VERSION ""

NS_ :

BS_:

BU_: GWM SCMB_PSM HVAC_RCCM GENERIC_GWMWakeup SOBDMD_AHCM_FOH TRM _delete SODL RTM PDM SCMH SCMG RSM SODR DDM RGTM DSM SCME TSTR

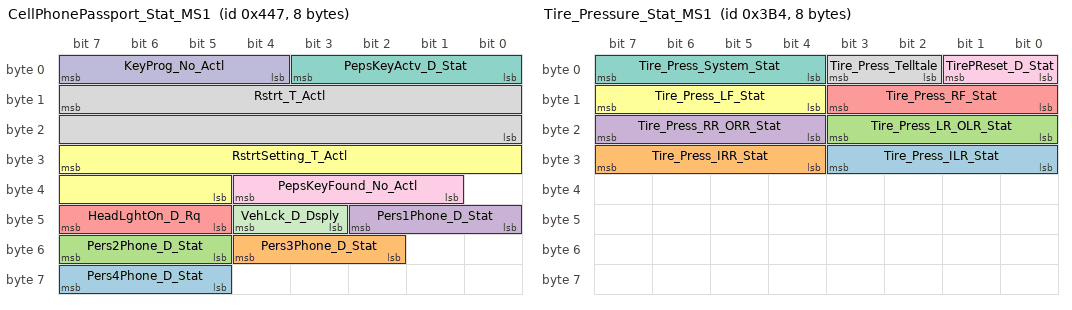
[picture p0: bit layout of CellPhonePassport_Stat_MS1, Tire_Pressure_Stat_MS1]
BO_ 1095 CellPhonePassport_Stat_MS1: 8 GWM
 SG_ Pers4Phone_D_Stat : 63|3@0+ (1,0) [0|7] "SED" Vector__XXX
 SG_ Pers3Phone_D_Stat : 52|3@0+ (1,0) [0|7] "SED" Vector__XXX
 SG_ Pers2Phone_D_Stat : 55|3@0+ (1,0) [0|7] "SED" Vector__XXX
 SG_ Pers1Phone_D_Stat : 42|3@0+ (1,0) [0|7] "SED" Vector__XXX
 SG_ HeadLghtOn_D_Rq : 47|3@0+ (1,0) [0|7] "SED" Vector__XXX
 SG_ RstrtSetting_T_Actl : 31|11@0+ (1,0) [0|2047] "second"  RSM
 SG_ PepsKeyActv_D_Stat : 3|4@0+ (1,0) [0|15] "SED" Vector__XXX
 SG_ Rstrt_T_Actl : 15|16@0+ (1,0) [0|65535] "seconds"  RSM
 SG_ PepsKeyFound_No_Actl : 36|4@0+ (1,0) [0|15] "unitless" Vector__XXX
 SG_ KeyProg_No_Actl : 7|4@0+ (1,0) [0|15] "unitless" Vector__XXX
 SG_ VehLck_D_Dsply : 44|2@0+ (1,0) [0|3] "SED" Vector__XXX

BO_ 948 Tire_Pressure_Stat_MS1: 8 GWM
 SG_ Tire_Press_ILR_Stat : 27|4@0+ (1,0) [0|15] "SED"  RTM
 SG_ Tire_Press_IRR_Stat : 31|4@0+ (1,0) [0|15] "SED"  RTM
 SG_ Tire_Press_LR_OLR_Stat : 19|4@0+ (1,0) [0|15] "SED"  RTM
 SG_ Tire_Press_RR_ORR_Stat : 23|4@0+ (1,0) [0|15] "SED"  RTM
 SG_ Tire_Press_RF_Stat : 11|4@0+ (1,0) [0|15] "SED"  RTM
 SG_ Tire_Press_LF_Stat : 15|4@0+ (1,0) [0|15] "SED"  RTM
 SG_ Tire_Press_System_Stat : 7|4@0+ (1,0) [0|15] "SED"  RTM
 SG_ Tire_Press_Telltale : 3|2@0+ (1,0) [0|3] "SED"  RTM
 SG_ TirePReset_D_Stat : 1|2@0+ (1,0) [0|3] "Discrete"  RTM

BO_ 840 FoH_Day_Req_MS1: 8 GWM
 SG_ FohT2Wednesday_T_Rq : 10|1@0+ (1,0) [0|1] "SED"  SOBDMD_AHCM_FOH
 SG_ FohT2Tuesday_T_Rq : 11|1@0+ (1,0) [0|1] "SED"  SOBDMD_AHCM_FOH
 SG_ FohT2Thursday_T_Rq : 12|1@0+ (1,0) [0|1] "SED"  SOBDMD_AHCM_FOH
 SG_ FohT2Sunday_T_Rq : 13|1@0+ (1,0) [0|1] "SED"  SOBDMD_AHCM_FOH
 SG_ FohT2Saturday_T_Rq : 14|1@0+ (1,0) [0|1] "SED"  SOBDMD_AHCM_FOH
 SG_ FohT2Monday_T_Rq : 15|1@0+ (1,0) [0|1] "SED"  SOBDMD_AHCM_FOH
 SG_ FohT2Friday_T_Rq : 0|1@0+ (1,0) [0|1] "SED"  SOBDMD_AHCM_FOH
 SG_ FohT1Wednesday_T_Rq : 1|1@0+ (1,0) [0|1] "SED"  SOBDMD_AHCM_FOH
 SG_ FohT1Tuesday_T_Rq : 2|1@0+ (1,0) [0|1] "SED"  SOBDMD_AHCM_FOH
 SG_ FohT1Thursday_T_Rq : 3|1@0+ (1,0) [0|1] "SED"  SOBDMD_AHCM_FOH
 SG_ FohT1Sunday_T_Rq : 4|1@0+ (1,0) [0|1] "SED"  SOBDMD_AHCM_FOH
 SG_ FohT1Saturday_T_Rq : 5|1@0+ (1,0) [0|1] "SED"  SOBDMD_AHCM_FOH
 SG_ FohT1Monday_T_Rq : 6|1@0+ (1,0) [0|1] "SED"  SOBDMD_AHCM_FOH
 SG_ FohT1Friday_T_Rq : 7|1@0+ (1,0) [0|1] "SED"  SOBDMD_AHCM_FOH
 SG_ FohAddHeater_D_Rq : 9|2@0+ (1,0) [0|3] "SED"  SOBDMD_AHCM_FOH
 SG_ FohStrtDateYr_No_Rq : 39|8@0+ (1,2000) [2000|2255] "year"  SOBDMD_AHCM_FOH
 SG_ FohStrtDateDay_No_Rq : 23|16@0+ (1,0) [0|65535] "julian day"  SOBDMD_AHCM_FOH

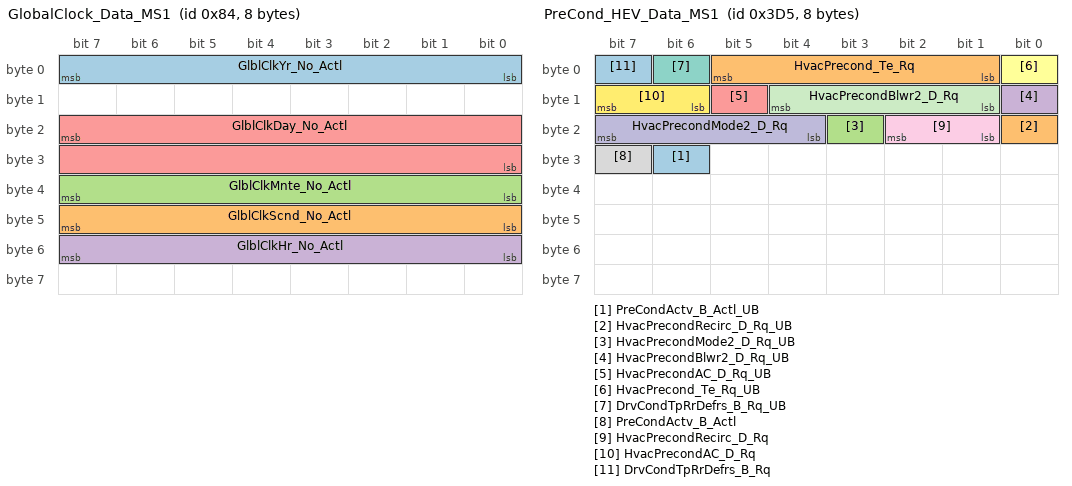
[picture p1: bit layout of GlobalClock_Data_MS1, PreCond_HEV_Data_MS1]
BO_ 132 GlobalClock_Data_MS1: 8 GWM
 SG_ GlblClkYr_No_Actl : 7|8@0+ (1,2000) [2000|2255] "year"  TRM,SOBDMD_AHCM_FOH
 SG_ GlblClkScnd_No_Actl : 47|8@0+ (1,0) [0|255] "second"  TRM,SOBDMD_AHCM_FOH
 SG_ GlblClkMnte_No_Actl : 39|8@0+ (1,0) [0|255] "minute"  TRM,SOBDMD_AHCM_FOH
 SG_ GlblClkHr_No_Actl : 55|8@0+ (1,0) [0|255] "hour"  TRM,SOBDMD_AHCM_FOH
 SG_ GlblClkDay_No_Actl : 23|16@0+ (1,0) [0|65535] "julian day"  TRM,SOBDMD_AHCM_FOH

BO_ 945 Body_Info_7_MS1: 8 GWM
 SG_ KeyOffMde_D_Actl : 7|4@0+ (1,0) [0|15] "SED"  PDM,DDM,DSM,HVAC_RCCM,RGTM

BO_ 981 PreCond_HEV_Data_MS1: 8 GWM
 SG_ PreCondActv_B_Actl_UB : 30|1@0+ (1,0) [0|1] "SED"  HVAC_RCCM
 SG_ HvacPrecondRecirc_D_Rq_UB : 16|1@0+ (1,0) [0|1] "SED"  HVAC_RCCM
 SG_ HvacPrecondMode2_D_Rq_UB : 19|1@0+ (1,0) [0|1] "SED"  HVAC_RCCM
 SG_ HvacPrecondBlwr2_D_Rq_UB : 8|1@0+ (1,0) [0|1] "SED"  HVAC_RCCM
 SG_ HvacPrecondAC_D_Rq_UB : 13|1@0+ (1,0) [0|1] "SED"  HVAC_RCCM
 SG_ HvacPrecond_Te_Rq_UB : 0|1@0+ (1,0) [0|1] "SED"  HVAC_RCCM
 SG_ DrvCondTpRrDefrs_B_Rq_UB : 6|1@0+ (1,0) [0|1] "SED"  HVAC_RCCM
 SG_ PreCondActv_B_Actl : 31|1@0+ (1,0) [0|1] "SED"  HVAC_RCCM
 SG_ HvacPrecondRecirc_D_Rq : 18|2@0+ (1,0) [0|3] "SED"  HVAC_RCCM
 SG_ HvacPrecondMode2_D_Rq : 23|4@0+ (1,0) [0|15] "SED"  HVAC_RCCM
 SG_ HvacPrecondBlwr2_D_Rq : 12|4@0+ (1,0) [0|15] "SED"  HVAC_RCCM
 SG_ HvacPrecondAC_D_Rq : 15|2@0+ (1,0) [0|3] "SED"  HVAC_RCCM
 SG_ DrvCondTpRrDefrs_B_Rq : 7|1@0+ (1,0) [0|1] "SED"  HVAC_RCCM
 SG_ HvacPrecond_Te_Rq : 5|5@0+ (0.5,14.5) [14.5|30] "deg C"  HVAC_RCCM

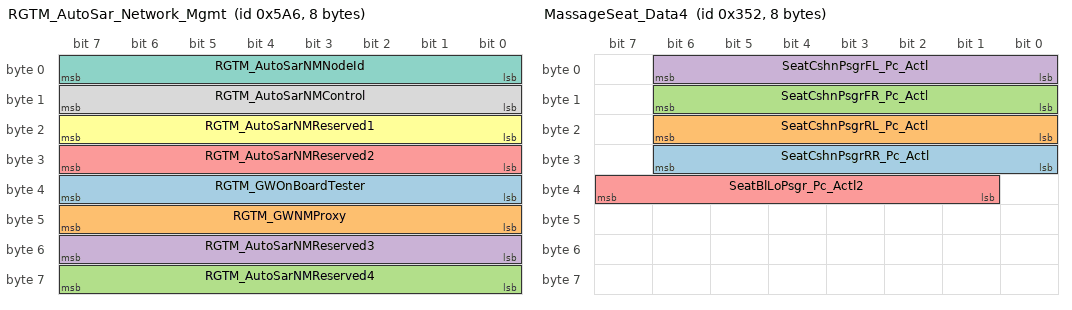
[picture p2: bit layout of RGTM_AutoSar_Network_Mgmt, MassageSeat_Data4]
BO_ 1446 RGTM_AutoSar_Network_Mgmt: 8 RGTM
 SG_ RGTM_GWOnBoardTester : 39|8@0+ (1,0) [0|255] "unitless"  DDM,GWM
 SG_ RGTM_GWNMProxy : 47|8@0+ (1,0) [0|255] "unitless"  DDM,GWM
 SG_ RGTM_AutoSarNMReserved4 : 63|8@0+ (1,0) [0|255] "unitless"  DDM,GWM
 SG_ RGTM_AutoSarNMReserved3 : 55|8@0+ (1,0) [0|255] "unitless"  DDM,GWM
 SG_ RGTM_AutoSarNMReserved2 : 31|8@0+ (1,0) [0|255] "unitless"  DDM,GWM
 SG_ RGTM_AutoSarNMReserved1 : 23|8@0+ (1,0) [0|255] "unitless"  DDM,GWM
 SG_ RGTM_AutoSarNMNodeId : 7|8@0+ (1,0) [0|255] "unitless"  DDM,GWM
 SG_ RGTM_AutoSarNMControl : 15|8@0+ (1,0) [0|255] "unitless"  DDM,GWM

BO_ 839 FuelOpHeater_Stat: 8 SOBDMD_AHCM_FOH
 SG_ FohStop_B_Stat : 49|2@0+ (1,0) [0|3] "SED"  GWM
 SG_ FohMsgTxt_D_Rq : 4|3@0+ (1,0) [0|7] "SED"  GWM
 SG_ FohKeyOff_B_Rq : 6|1@0+ (1,0) [0|1] "SED"  GWM
 SG_ FohEnbl_B_Rq : 7|1@0+ (1,0) [0|1] "SED"  GWM
 SG_ FohTAllEnable_B_Stat : 17|2@0+ (1,0) [0|3] "SED"  GWM
 SG_ FohT2Mnte_T_Stat : 55|6@0+ (1,0) [0|63] "minute"  GWM
 SG_ FohT2Hr_T_Stat : 47|5@0+ (1,0) [0|31] "hour"  GWM
 SG_ FohT2Enable_B_Stat : 63|1@0+ (1,0) [0|1] "SED"  GWM
 SG_ FohT1Mnte_T_Stat : 39|6@0+ (1,0) [0|63] "minute"  GWM
 SG_ FohT1Hr_T_Stat : 31|5@0+ (1,0) [0|31] "hour"  GWM
 SG_ FohT1Enable_B_Stat : 0|1@0+ (1,0) [0|1] "SED"  GWM
 SG_ FohStrtMnte_T_Stat : 23|6@0+ (1,0) [0|63] "minute"  GWM
 SG_ FohStrtHr_T_Stat : 15|5@0+ (1,0) [0|31] "hour"  GWM
 SG_ FohStrtEnable_B_Stat : 1|1@0+ (1,0) [0|1] "SED"  GWM
 SG_ FohContOn_B_Stat : 33|2@0+ (1,0) [0|3] "SED"  GWM
 SG_ FohStrtDay_T_Stat : 10|3@0+ (1,0) [0|7] "SED"  GWM
 SG_ FohT2Wednesday_T_Stat : 56|1@0+ (1,0) [0|1] "SED"  GWM
 SG_ FohT2Tuesday_T_Stat : 57|1@0+ (1,0) [0|1] "SED"  GWM
 SG_ FohT2Thursday_T_Stat : 58|1@0+ (1,0) [0|1] "SED"  GWM
 SG_ FohT2Sunday_T_Stat : 59|1@0+ (1,0) [0|1] "SED"  GWM
 SG_ FohT2Saturday_T_Stat : 60|1@0+ (1,0) [0|1] "SED"  GWM
 SG_ FohT2Monday_T_Stat : 61|1@0+ (1,0) [0|1] "SED"  GWM
 SG_ FohT2Friday_T_Stat : 62|1@0+ (1,0) [0|1] "SED"  GWM
 SG_ FohT1Wednesday_T_Stat : 40|1@0+ (1,0) [0|1] "SED"  GWM
 SG_ FohT1Tuesday_T_Stat : 41|1@0+ (1,0) [0|1] "SED"  GWM
 SG_ FohT1Thursday_T_Stat : 42|1@0+ (1,0) [0|1] "SED"  GWM
 SG_ FohT1Sunday_T_Stat : 24|1@0+ (1,0) [0|1] "SED"  GWM
 SG_ FohT1Saturday_T_Stat : 25|1@0+ (1,0) [0|1] "SED"  GWM
 SG_ FohT1Monday_T_Stat : 26|1@0+ (1,0) [0|1] "SED"  GWM
 SG_ FohT1Friday_T_Stat : 5|1@0+ (1,0) [0|1] "SED"  GWM

BO_ 850 MassageSeat_Data4: 8 SCMH
 SG_ SeatCshnPsgrRR_Pc_Actl : 30|7@0+ (1,0) [0|126] "Percent"  GWM
 SG_ SeatCshnPsgrRL_Pc_Actl : 22|7@0+ (1,0) [0|126] "Percent"  GWM
 SG_ SeatCshnPsgrFR_Pc_Actl : 14|7@0+ (1,0) [0|126] "Percent"  GWM
 SG_ SeatCshnPsgrFL_Pc_Actl : 6|7@0+ (1,0) [0|126] "Percent"  GWM
 SG_ SeatBlLoPsgr_Pc_Actl2 : 39|7@0+ (1,0) [0|126] "Percent"  GWM

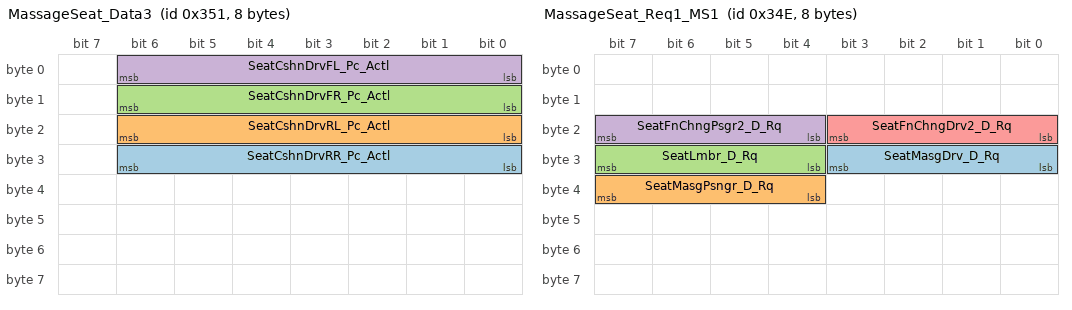
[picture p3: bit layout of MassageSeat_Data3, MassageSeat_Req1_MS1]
BO_ 849 MassageSeat_Data3: 8 SCMG
 SG_ SeatCshnDrvRR_Pc_Actl : 30|7@0+ (1,0) [0|126] "Percent"  GWM
 SG_ SeatCshnDrvRL_Pc_Actl : 22|7@0+ (1,0) [0|126] "Percent"  GWM
 SG_ SeatCshnDrvFR_Pc_Actl : 14|7@0+ (1,0) [0|126] "Percent"  GWM
 SG_ SeatCshnDrvFL_Pc_Actl : 6|7@0+ (1,0) [0|126] "Percent"  GWM

BO_ 846 MassageSeat_Req1_MS1: 8 GWM
 SG_ SeatMasgDrv_D_Rq : 27|4@0+ (1,0) [0|15] "SED" Vector__XXX
 SG_ SeatMasgPsngr_D_Rq : 39|4@0+ (1,0) [0|15] "SED" Vector__XXX
 SG_ SeatLmbr_D_Rq : 31|4@0+ (1,0) [0|15] "SED"  DSM,SCMB_PSM
 SG_ SeatFnChngPsgr2_D_Rq : 23|4@0+ (1,0) [0|15] "SED"  SCMG,SCMH
 SG_ SeatFnChngDrv2_D_Rq : 19|4@0+ (1,0) [0|15] "SED"  SCMG,SCMH

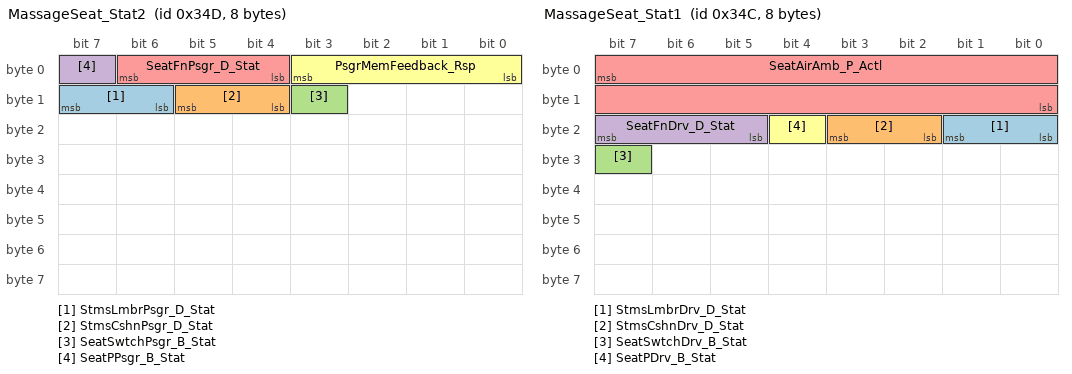
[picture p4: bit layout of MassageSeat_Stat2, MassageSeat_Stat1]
BO_ 845 MassageSeat_Stat2: 8 SCMH
 SG_ StmsLmbrPsgr_D_Stat : 15|2@0+ (1,0) [0|3] "SED"  GWM
 SG_ StmsCshnPsgr_D_Stat : 13|2@0+ (1,0) [0|3] "SED"  GWM
 SG_ SeatSwtchPsgr_B_Stat : 11|1@0+ (1,0) [0|1] "SED"  GWM
 SG_ SeatPPsgr_B_Stat : 7|1@0+ (1,0) [0|1] "SED"  GWM
 SG_ SeatFnPsgr_D_Stat : 6|3@0+ (1,0) [0|7] "SED"  GWM
 SG_ PsgrMemFeedback_Rsp : 3|4@0+ (1,0) [0|15] "SED"  GWM

BO_ 844 MassageSeat_Stat1: 8 SCMG
 SG_ StmsLmbrDrv_D_Stat : 17|2@0+ (1,0) [0|3] "SED"  GWM
 SG_ StmsCshnDrv_D_Stat : 19|2@0+ (1,0) [0|3] "SED"  GWM
 SG_ SeatSwtchDrv_B_Stat : 31|1@0+ (1,0) [0|1] "SED"  GWM
 SG_ SeatFnDrv_D_Stat : 23|3@0+ (1,0) [0|7] "SED"  GWM
 SG_ SeatAirAmb_P_Actl : 7|16@0+ (0.01,0) [0|655.35] "KiloPascal"  GWM,SCMH
 SG_ SeatPDrv_B_Stat : 20|1@0+ (1,0) [0|1] "SED"  GWM

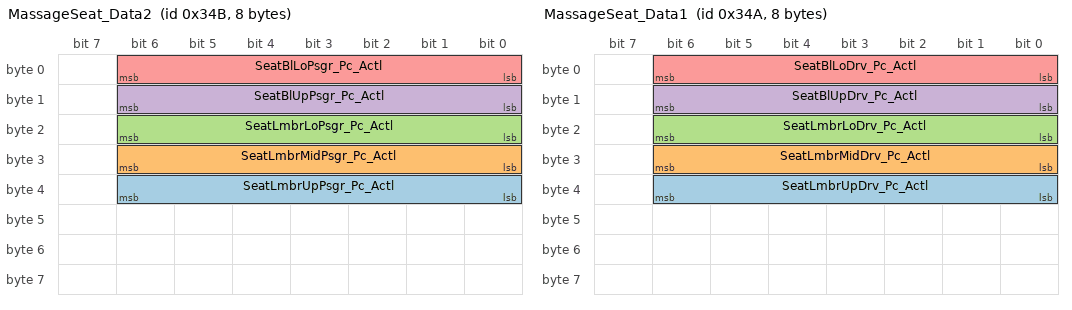
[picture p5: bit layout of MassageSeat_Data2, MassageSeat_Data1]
BO_ 843 MassageSeat_Data2: 8 SCMH
 SG_ SeatLmbrUpPsgr_Pc_Actl : 38|7@0+ (1,0) [0|127] "Percent"  GWM
 SG_ SeatLmbrMidPsgr_Pc_Actl : 30|7@0+ (1,0) [0|127] "Percent"  GWM
 SG_ SeatLmbrLoPsgr_Pc_Actl : 22|7@0+ (1,0) [0|127] "Percent"  GWM
 SG_ SeatBlUpPsgr_Pc_Actl : 14|7@0+ (1,0) [0|126] "Percent"  GWM
 SG_ SeatBlLoPsgr_Pc_Actl : 6|7@0+ (1,0) [0|126] "Percent"  GWM

BO_ 842 MassageSeat_Data1: 8 SCMG
 SG_ SeatLmbrUpDrv_Pc_Actl : 38|7@0+ (1,0) [0|127] "Percent"  GWM
 SG_ SeatLmbrMidDrv_Pc_Actl : 30|7@0+ (1,0) [0|127] "Percent"  GWM
 SG_ SeatLmbrLoDrv_Pc_Actl : 22|7@0+ (1,0) [0|127] "Percent"  GWM
 SG_ SeatBlUpDrv_Pc_Actl : 14|7@0+ (1,0) [0|126] "Percent"  GWM
 SG_ SeatBlLoDrv_Pc_Actl : 6|7@0+ (1,0) [0|126] "Percent"  GWM

BO_ 1994 TesterPhysicalResRSM: 8 RSM
 SG_ TesterPhysicalResRSM : 7|64@0+ (1,0) [0|1.84467E+019] "unitless"  TSTR

BO_ 1986 TesterPhysicalReqRSM: 8 TSTR
 SG_ TesterPhysicalReqRSM : 7|64@0+ (1,0) [0|1.84467E+019] "unitless"  RSM

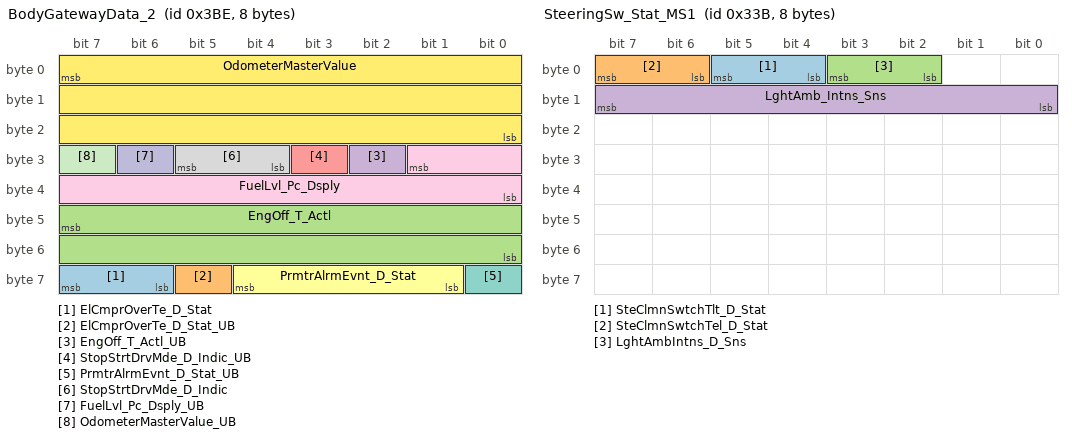
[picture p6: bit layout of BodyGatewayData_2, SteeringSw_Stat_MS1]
BO_ 958 BodyGatewayData_2: 8 GWM
 SG_ ElCmprOverTe_D_Stat : 63|2@0+ (1,0) [0|3] "SED"  HVAC_RCCM
 SG_ ElCmprOverTe_D_Stat_UB : 61|1@0+ (1,0) [0|1] "SED"  HVAC_RCCM
 SG_ EngOff_T_Actl : 47|16@0+ (1,0) [0|65534] "second^0.5"  HVAC_RCCM
 SG_ EngOff_T_Actl_UB : 26|1@0+ (1,0) [0|1] "SED"  HVAC_RCCM
 SG_ StopStrtDrvMde_D_Indic_UB : 27|1@0+ (1,0) [0|1] "SED"  HVAC_RCCM
 SG_ PrmtrAlrmEvnt_D_Stat : 60|4@0+ (1,0) [0|15] "SED"  RSM
 SG_ PrmtrAlrmEvnt_D_Stat_UB : 56|1@0+ (1,0) [0|1] "SED"  RSM
 SG_ StopStrtDrvMde_D_Indic : 29|2@0+ (1,0) [0|3] "SED"  HVAC_RCCM
 SG_ FuelLvl_Pc_Dsply : 25|10@0+ (0.108696,-5.217408) [-5.217408|105.9786] "Percent"  SOBDMD_AHCM_FOH
 SG_ FuelLvl_Pc_Dsply_UB : 30|1@0+ (1,0) [0|1] "SED"  SOBDMD_AHCM_FOH
 SG_ OdometerMasterValue_UB : 31|1@0+ (1,0) [0|1] "SED"  HVAC_RCCM,SOBDMD_AHCM_FOH,RGTM
 SG_ OdometerMasterValue : 7|24@0+ (1,0) [0|16777214] "km"  HVAC_RCCM,SOBDMD_AHCM_FOH,RGTM

BO_ 827 SteeringSw_Stat_MS1: 8 GWM
 SG_ SteClmnSwtchTlt_D_Stat : 5|2@0+ (1,0) [0|3] "SED"  DSM
 SG_ SteClmnSwtchTel_D_Stat : 7|2@0+ (1,0) [0|3] "SED"  DSM
 SG_ LghtAmbIntns_D_Sns : 3|2@0+ (1,0) [0|3] "SED" Vector__XXX
 SG_ LghtAmb_Intns_Sns : 15|8@0+ (1,0) [0|255] "unitless" Vector__XXX

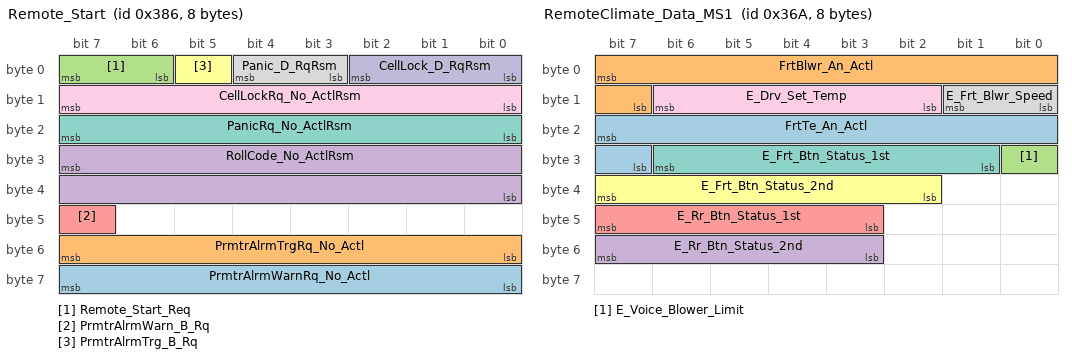
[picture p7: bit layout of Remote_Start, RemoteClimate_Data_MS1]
BO_ 902 Remote_Start: 8 RSM
 SG_ PrmtrAlrmWarnRq_No_Actl : 63|8@0+ (1,0) [0|255] "unitless"  GWM
 SG_ PrmtrAlrmTrgRq_No_Actl : 55|8@0+ (1,0) [0|255] "unitless"  GWM
 SG_ Remote_Start_Req : 7|2@0+ (1,0) [0|3] "SED"  GWM
 SG_ RollCode_No_ActlRsm : 31|16@0+ (1,0) [0|65535] "unitless"  GWM
 SG_ PrmtrAlrmWarn_B_Rq : 47|1@0+ (1,0) [0|1] "SED"  GWM
 SG_ PrmtrAlrmTrg_B_Rq : 5|1@0+ (1,0) [0|1] "SED"  GWM
 SG_ PanicRq_No_ActlRsm : 23|8@0+ (1,0) [0|255] "unitless"  GWM
 SG_ Panic_D_RqRsm : 4|2@0+ (1,0) [0|3] "SED"  GWM
 SG_ CellLockRq_No_ActlRsm : 15|8@0+ (1,0) [0|255] "unitless"  GWM
 SG_ CellLock_D_RqRsm : 2|3@0+ (1,0) [0|7] "SED"  GWM

BO_ 765 GatewayData_MS1: 8 GWM
 SG_ ValetMode_D_Stat_UB : 35|1@0+ (1,0) [0|1] "SED"  DSM
 SG_ ValetMode_D_Stat : 25|2@0+ (1,0) [0|3] "SED"  DSM
 SG_ CcStat_D_Actl_UB : 48|1@0+ (1,0) [0|1] "SED" Vector__XXX
 SG_ CcStat_D_Actl : 51|3@0+ (1,0) [0|7] "SED" Vector__XXX
 SG_ PrplTqMnSat_B_Actl_UB : 52|1@0+ (1,0) [0|1] "SED" Vector__XXX
 SG_ PrplTqMnSat_B_Actl : 53|1@0+ (1,0) [0|1] "SED" Vector__XXX
 SG_ ClimtBlwrLim_B_Rq_UB : 60|1@0+ (1,0) [0|1] "SED"  HVAC_RCCM
 SG_ ClimtBlwrLim_B_Rq : 61|1@0+ (1,0) [0|1] "SED"  HVAC_RCCM
 SG_ TrlrBrkActCnnct_B_Actl_UB : 62|1@0+ (1,0) [0|1] "SED" Vector__XXX
 SG_ TrlrBrkActCnnct_B_Actl : 63|1@0+ (1,0) [0|1] "SED" Vector__XXX
 SG_ EmPrflButtnAssoc_D_Rq : 17|2@0+ (1,0) [0|3] "SED"  DSM
 SG_ EmPrflButtnAssoc_D_Rq_UB : 56|1@0+ (1,0) [0|1] "SED"  DSM
 SG_ CamraFrntStat_D_Stat_UB : 32|1@0+ (1,0) [0|1] "SED"  HVAC_RCCM
 SG_ CamraFrntStat_D_Stat : 34|2@0+ (1,0) [0|3] "SED"  HVAC_RCCM
 SG_ AutoHoldSwMde_B_Ind_UB : 46|1@0+ (1,0) [0|1] "SED"  HVAC_RCCM
 SG_ AutoHoldSwMde_B_Ind : 47|1@0+ (1,0) [0|1] "SED"  HVAC_RCCM
 SG_ SteWhlHeat_D_Stat : 39|4@0+ (1,0) [0|15] "SED"  HVAC_RCCM
 SG_ Running_Board_Cmd_UB : 27|1@0+ (1,0) [0|1] "SED" Vector__XXX
 SG_ Running_Board_Cmd : 29|2@0+ (1,0) [0|3] "SED" Vector__XXX
 SG_ Bezel_Beeps_Rq_UB : 18|1@0+ (1,0) [0|1] "SED" Vector__XXX
 SG_ Bezel_Beeps_Rq : 20|2@0+ (1,0) [0|3] "unitless" Vector__XXX
 SG_ Diagnostic_Operation_Rq_UB : 21|1@0+ (1,0) [0|1] "SED"  HVAC_RCCM
 SG_ Bezel_Diag_State_Rq_UB : 23|1@0+ (1,0) [0|1] "SED" Vector__XXX
 SG_ Bezel_Diag_Module_Rq_UB : 22|1@0+ (1,0) [0|1] "SED" Vector__XXX
 SG_ Diagnostic_Operation_Rq : 11|4@0+ (1,0) [0|15] "unitless"  HVAC_RCCM
 SG_ Bezel_Diag_State_Rq : 1|2@0+ (1,0) [0|3] "unitless" Vector__XXX
 SG_ Bezel_Diag_Module_Rq : 15|4@0+ (1,0) [0|15] "unitless" Vector__XXX
 SG_ HMI_HMIMode_St_UB : 2|1@0+ (1,0) [0|1] "SED"  HVAC_RCCM,RGTM
 SG_ HMI_HMIMode_St : 5|3@0+ (1,0) [0|7] "SED"  HVAC_RCCM,RGTM
 SG_ Mc_VehUnitTempUsrSel_St_UB : 6|1@0+ (1,0) [0|1] "SED"  HVAC_RCCM
 SG_ Mc_VehUnitTempUsrSel_St : 7|1@0+ (1,0) [0|1] "SED"  HVAC_RCCM
 SG_ PsngrFrntDetct_D_Actl_UB : 40|1@0+ (1,0) [0|1] "SED"  HVAC_RCCM
 SG_ PsngrFrntDetct_D_Actl : 55|2@0+ (1,0) [0|3] "SED"  HVAC_RCCM
 SG_ SteWhlHeat_D_Stat_UB : 26|1@0+ (1,0) [0|1] "SED"  HVAC_RCCM
 SG_ PrkAidLamp_D_Rq_UB : 41|1@0+ (1,0) [0|1] "SED" Vector__XXX
 SG_ ParkDetect_Stat_UB : 30|1@0+ (1,0) [0|1] "SED"  RSM
 SG_ ParkDetect_Stat : 31|1@0+ (1,0) [0|1] "SED"  RSM
 SG_ Voice_Blower_Limit_UB : 44|1@0+ (1,0) [0|1] "SED"  HVAC_RCCM
 SG_ Voice_Blower_Limit : 45|1@0+ (1,0) [0|1] "SED"  HVAC_RCCM
 SG_ PwStep_D_DrvInhbt_UB : 57|1@0+ (1,0) [0|1] "SED" Vector__XXX
 SG_ PwStep_D_DrvInhbt : 59|2@0+ (1,0) [0|3] "SED" Vector__XXX

BO_ 874 RemoteClimate_Data_MS1: 8 GWM
 SG_ FrtTe_An_Actl : 23|9@0+ (1,0) [0|510] "degrees"  HVAC_RCCM
 SG_ FrtBlwr_An_Actl : 7|9@0+ (1,0) [0|510] "degrees"  HVAC_RCCM
 SG_ E_Voice_Blower_Limit : 24|1@0+ (1,0) [0|1] "SED"  HVAC_RCCM
 SG_ E_Rr_Btn_Status_2nd : 55|5@0+ (1,0) [0|31] "SED"  HVAC_RCCM
 SG_ E_Rr_Btn_Status_1st : 47|5@0+ (1,0) [0|31] "SED"  HVAC_RCCM
 SG_ E_Frt_Btn_Status_2nd : 39|6@0+ (1,0) [0|63] "SED"  HVAC_RCCM
 SG_ E_Frt_Btn_Status_1st : 30|6@0+ (1,0) [0|63] "SED"  HVAC_RCCM
 SG_ E_Frt_Blwr_Speed : 9|2@0+ (1,0) [0|3] "SED"  HVAC_RCCM
 SG_ E_Drv_Set_Temp : 14|5@0+ (1,0) [0|31] "SED"  HVAC_RCCM

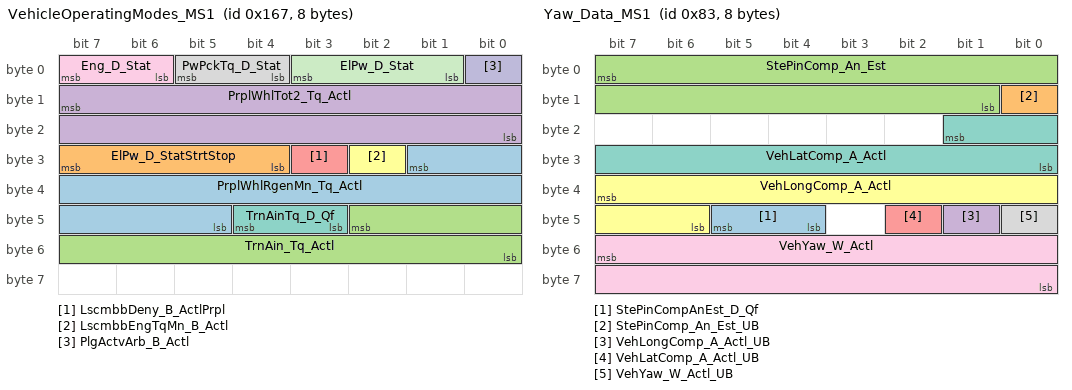
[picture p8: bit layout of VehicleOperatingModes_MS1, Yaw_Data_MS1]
BO_ 359 VehicleOperatingModes_MS1: 8 GWM
 SG_ PrplWhlRgenMn_Tq_Actl : 25|13@0+ (4,-16380) [-16380|16380] "Nm" Vector__XXX
 SG_ ElPw_D_StatStrtStop : 31|4@0+ (1,0) [0|15] "SED" Vector__XXX
 SG_ TrnAin_Tq_Actl : 42|11@0+ (1,-500) [-500|1547] "Nm" Vector__XXX
 SG_ PrplWhlTot2_Tq_Actl : 15|16@0+ (4,-131072) [-131072|131060] "Nm" Vector__XXX
 SG_ LscmbbDeny_B_ActlPrpl : 27|1@0+ (1,0) [0|1] "SED" Vector__XXX
 SG_ LscmbbEngTqMn_B_Actl : 26|1@0+ (1,0) [0|1] "SED" Vector__XXX
 SG_ TrnAinTq_D_Qf : 44|2@0+ (1,0) [0|3] "SED" Vector__XXX
 SG_ PwPckTq_D_Stat : 5|2@0+ (1,0) [0|3] "SED"  SCMB_PSM,SCME,HVAC_RCCM,RSM,TRM,SCMH,SCMG,RTM,RGTM,PDM,DSM,DDM,SOBDMD_AHCM_FOH
 SG_ Eng_D_Stat : 7|2@0+ (1,0) [0|3] "SED"  HVAC_RCCM,SOBDMD_AHCM_FOH
 SG_ PlgActvArb_B_Actl : 0|1@0+ (1,0) [0|1] "SED" Vector__XXX
 SG_ ElPw_D_Stat : 3|3@0+ (1,0) [0|7] "SED"  SCMB_PSM,SCME,HVAC_RCCM,SCMG,SCMH,TRM,SOBDMD_AHCM_FOH,DDM,DSM,PDM,RGTM,RTM

BO_ 131 Yaw_Data_MS1: 8 GWM
 SG_ StePinCompAnEst_D_Qf : 45|2@0+ (1,0) [0|3] "SED"  SODL,SODR
 SG_ StePinComp_An_Est_UB : 8|1@0+ (1,0) [0|1] "SED"  SODL,SODR
 SG_ StePinComp_An_Est : 7|15@0+ (0.1,-1600) [-1600|1676.7] "degrees"  SODL,SODR
 SG_ VehLongComp_A_Actl_UB : 41|1@0+ (1,0) [0|1] "SED"  RGTM
 SG_ VehLatComp_A_Actl_UB : 42|1@0+ (1,0) [0|1] "SED"  RGTM
 SG_ VehLongComp_A_Actl : 39|10@0+ (0.035,-17.9) [-17.9|17.835] "m/s^2"  RGTM
 SG_ VehLatComp_A_Actl : 17|10@0+ (0.035,-17.9) [-17.9|17.835] "m/s^2"  RGTM
 SG_ VehYaw_W_Actl_UB : 40|1@0+ (1,0) [0|1] "SED"  SODL,SODR
 SG_ VehYaw_W_Actl : 55|16@0+ (0.0002,-6.5) [-6.5|6.6066] "rad/s"  SODL,SODR

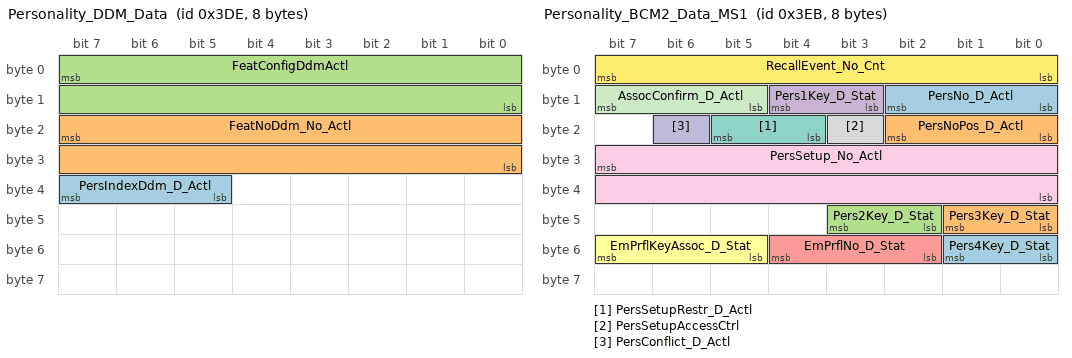
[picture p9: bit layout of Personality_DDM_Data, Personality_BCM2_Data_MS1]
BO_ 990 Personality_DDM_Data: 8 DDM
 SG_ PersIndexDdm_D_Actl : 39|3@0+ (1,0) [0|7] "SED"  GWM
 SG_ FeatNoDdm_No_Actl : 23|16@0+ (1,0) [0|65535] "Number"  GWM
 SG_ FeatConfigDdmActl : 7|16@0+ (1,0) [0|65535] "Undefined"  GWM

BO_ 1003 Personality_BCM2_Data_MS1: 8 GWM
 SG_ Pers4Key_D_Stat : 49|2@0+ (1,0) [0|3] "SED" Vector__XXX
 SG_ Pers3Key_D_Stat : 41|2@0+ (1,0) [0|3] "SED" Vector__XXX
 SG_ Pers2Key_D_Stat : 43|2@0+ (1,0) [0|3] "SED" Vector__XXX
 SG_ Pers1Key_D_Stat : 12|2@0+ (1,0) [0|3] "SED" Vector__XXX
 SG_ EmPrflNo_D_Stat : 52|3@0+ (1,0) [0|7] "SED" Vector__XXX
 SG_ EmPrflKeyAssoc_D_Stat : 55|3@0+ (1,0) [0|7] "SED" Vector__XXX
 SG_ PersSetupRestr_D_Actl : 21|2@0+ (1,0) [0|3] "SED"  HVAC_RCCM,PDM,DDM,DSM
 SG_ PersSetupAccessCtrl : 19|1@0+ (1,0) [0|1] "SED"  HVAC_RCCM,DDM,DSM
 SG_ PersSetup_No_Actl : 31|16@0+ (1,0) [0|65535] "Number"  HVAC_RCCM,PDM,DDM,DSM
 SG_ PersConflict_D_Actl : 22|1@0+ (1,0) [0|1] "SED" Vector__XXX
 SG_ AssocConfirm_D_Actl : 15|3@0+ (1,0) [0|7] "SED" Vector__XXX
 SG_ RecallEvent_No_Cnt : 7|8@0+ (1,0) [0|255] "Counts"  HVAC_RCCM,SCMG,SCMH,DDM,DSM
 SG_ PersNo_D_Actl : 10|3@0+ (1,0) [0|7] "SED"  HVAC_RCCM,DDM,DSM,SCMG,SCMH
 SG_ PersNoPos_D_Actl : 18|3@0+ (1,0) [0|7] "SED"  SCMG,SCMH,DSM

BO_ 1945 TesterPhysicalResTRM: 8 TRM
 SG_ TesterPhysicalResTRM : 7|64@0+ (1,0) [0|1.84467E+019] "unitless"  TSTR

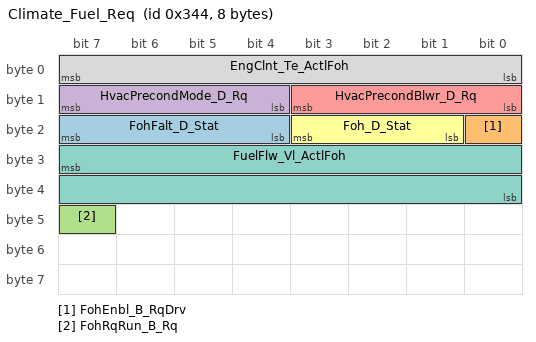
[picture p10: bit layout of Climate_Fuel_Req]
BO_ 836 Climate_Fuel_Req: 8 SOBDMD_AHCM_FOH
 SG_ FohFalt_D_Stat : 23|4@0+ (1,0) [0|15] "SED"  GWM
 SG_ FohEnbl_B_RqDrv : 16|1@0+ (1,0) [0|1] "SED"  GWM
 SG_ FohRqRun_B_Rq : 47|1@0+ (1,0) [0|1] "SED"  GWM
 SG_ HvacPrecondMode_D_Rq : 15|4@0+ (1,0) [0|15] "SED"  HVAC_RCCM,GWM
 SG_ HvacPrecondBlwr_D_Rq : 11|4@0+ (1,0) [0|15] "SED"  HVAC_RCCM,GWM
 SG_ Foh_D_Stat : 19|3@0+ (1,0) [0|7] "SED"  HVAC_RCCM,GWM
 SG_ FuelFlw_Vl_ActlFoh : 31|16@0+ (25,0) [0|1638375] "microlitre"  GWM
 SG_ EngClnt_Te_ActlFoh : 7|8@0+ (1,-50) [-50|204] "degC"  HVAC_RCCM,GWM

CM_ BO_ 948 "$3B4 used by CGEA SPDJB";
CM_ SG_ 840 FohT2Wednesday_T_Rq "Signal not transmitted on vehicles that do not have the Fuel operated heater feature.";
CM_ SG_ 840 FohT2Tuesday_T_Rq "Signal not transmitted on vehicles that do not have the Fuel operated heater feature.";
CM_ SG_ 840 FohT2Thursday_T_Rq "Signal not transmitted on vehicles that do not have the Fuel operated heater feature.";
CM_ SG_ 840 FohT2Sunday_T_Rq "Signal not transmitted on vehicles that do not have the Fuel operated heater feature.";
CM_ SG_ 840 FohT2Saturday_T_Rq "Signal not transmitted on vehicles that do not have the Fuel operated heater feature.";
CM_ SG_ 840 FohT2Monday_T_Rq "Signal not transmitted on vehicles that do not have the Fuel operated heater feature.";
CM_ SG_ 840 FohT2Friday_T_Rq "Signal not transmitted on vehicles that do not have the Fuel operated heater feature.";
CM_ SG_ 840 FohT1Wednesday_T_Rq "Signal not transmitted on vehicles that do not have the Fuel operated heater feature.";
CM_ SG_ 840 FohT1Tuesday_T_Rq "Signal not transmitted on vehicles that do not have the Fuel operated heater feature.";
CM_ SG_ 840 FohT1Thursday_T_Rq "Signal not transmitted on vehicles that do not have the Fuel operated heater feature.";
CM_ SG_ 840 FohT1Sunday_T_Rq "Signal not transmitted on vehicles that do not have the Fuel operated heater feature.";
CM_ SG_ 840 FohT1Saturday_T_Rq "Signal not transmitted on vehicles that do not have the Fuel operated heater feature.";
CM_ SG_ 840 FohT1Monday_T_Rq "Signal not transmitted on vehicles that do not have the Fuel operated heater feature.";
CM_ SG_ 840 FohT1Friday_T_Rq "Signal not transmitted on vehicles that do not have the Fuel operated heater feature.";
CM_ SG_ 981 HvacPrecondMode2_D_Rq "Signal not transmitted on vehicles that do not have the Fuel operated heater feature.";
CM_ SG_ 981 HvacPrecondBlwr2_D_Rq "Signal not transmitted on vehicles that do not have the Fuel operated heater feature.";
CM_ SG_ 839 FohStop_B_Stat "Signal not transmitted on vehicles that do not have the Fuel operated heater feature.";
CM_ SG_ 839 FohMsgTxt_D_Rq "Signal not transmitted on vehicles that do not have the Fuel operated heater feature.";
CM_ SG_ 839 FohKeyOff_B_Rq "Signal not transmitted on vehicles that do not have the Fuel operated heater feature.";
CM_ SG_ 839 FohEnbl_B_Rq "Signal not transmitted on vehicles that do not have the Fuel operated heater feature.";
CM_ SG_ 839 FohTAllEnable_B_Stat "Signal not transmitted on vehicles that do not have the Fuel operated heater feature.";
CM_ SG_ 839 FohT2Mnte_T_Stat "Signal not transmitted on vehicles that do not have the Fuel operated heater feature.";
CM_ SG_ 839 FohT2Hr_T_Stat "Signal not transmitted on vehicles that do not have the Fuel operated heater feature.";
CM_ SG_ 839 FohT2Enable_B_Stat "Signal not transmitted on vehicles that do not have the Fuel operated heater feature.";
CM_ SG_ 839 FohT1Mnte_T_Stat "Signal not transmitted on vehicles that do not have the Fuel operated heater feature.";
CM_ SG_ 839 FohT1Hr_T_Stat "Signal not transmitted on vehicles that do not have the Fuel operated heater feature.";
CM_ SG_ 839 FohT1Enable_B_Stat "Signal not transmitted on vehicles that do not have the Fuel operated heater feature.";
CM_ SG_ 839 FohStrtMnte_T_Stat "Signal not transmitted on vehicles that do not have the Fuel operated heater feature.";
CM_ SG_ 839 FohStrtHr_T_Stat "Signal not transmitted on vehicles that do not have the Fuel operated heater feature.";
CM_ SG_ 839 FohStrtEnable_B_Stat "Signal not transmitted on vehicles that do not have the Fuel operated heater feature.";
CM_ SG_ 839 FohContOn_B_Stat "Signal not transmitted on vehicles that do not have the Fuel operated heater feature.";
CM_ SG_ 839 FohStrtDay_T_Stat "Signal not transmitted on vehicles that do not have the Fuel operated heater feature.";
CM_ SG_ 839 FohT2Wednesday_T_Stat "Signal not transmitted on vehicles that do not have the Fuel operated heater feature.";
CM_ SG_ 839 FohT2Tuesday_T_Stat "Signal not transmitted on vehicles that do not have the Fuel operated heater feature.";
CM_ SG_ 839 FohT2Thursday_T_Stat "Signal not transmitted on vehicles that do not have the Fuel operated heater feature.";
CM_ SG_ 839 FohT2Sunday_T_Stat "Signal not transmitted on vehicles that do not have the Fuel operated heater feature.";
CM_ SG_ 839 FohT2Saturday_T_Stat "Signal not transmitted on vehicles that do not have the Fuel operated heater feature.";
CM_ SG_ 839 FohT2Monday_T_Stat "Signal not transmitted on vehicles that do not have the Fuel operated heater feature.";
CM_ SG_ 839 FohT2Friday_T_Stat "Signal not transmitted on vehicles that do not have the Fuel operated heater feature.";
CM_ SG_ 839 FohT1Wednesday_T_Stat "Signal not transmitted on vehicles that do not have the Fuel operated heater feature.";
CM_ SG_ 839 FohT1Tuesday_T_Stat "Signal not transmitted on vehicles that do not have the Fuel operated heater feature.";
CM_ SG_ 839 FohT1Thursday_T_Stat "Signal not transmitted on vehicles that do not have the Fuel operated heater feature.";
CM_ SG_ 839 FohT1Sunday_T_Stat "Signal not transmitted on vehicles that do not have the Fuel operated heater feature.";
CM_ SG_ 839 FohT1Saturday_T_Stat "Signal not transmitted on vehicles that do not have the Fuel operated heater feature.";
CM_ SG_ 839 FohT1Monday_T_Stat "Signal not transmitted on vehicles that do not have the Fuel operated heater feature.";
CM_ SG_ 839 FohT1Friday_T_Stat "Signal not transmitted on vehicles that do not have the Fuel operated heater feature.";
CM_ SG_ 765 CcStat_D_Actl "ABSGenSigTimeoutTime=1000";
CM_ SG_ 765 Bezel_Beeps_Rq "Vehicle Settings";
CM_ SG_ 765 Diagnostic_Operation_Rq "Object:BezelDiagnostics.MFD_Bezel_Diagnostic.St";
CM_ SG_ 765 Bezel_Diag_State_Rq "Object:BezelDiagnostics.MFD_Bezel_Diagnostic.Rq";
CM_ SG_ 765 Bezel_Diag_Module_Rq "Object:BezelDiagnostics.MFD_Bezel_Diagnostic.St";
CM_ SG_ 765 HMI_HMIMode_St "Object ACU System Master.HMIMode
OR
Object NAV System Master.HMIMode

Refer Method HMIAudioMode in the SPSS";
CM_ SG_ 765 Mc_VehUnitTempUsrSel_St "Object.VehicleSettings.Disp_Temperature.Rq";
CM_ BO_ 874 "Tx HS3 FCIMB for 16U502";
CM_ SG_ 359 TrnAin_Tq_Actl "Signal not transmitted on HEV variances.";
CM_ SG_ 359 TrnAinTq_D_Qf "Signal not transmitted on HEV variances.";
CM_ SG_ 359 PlgActvArb_B_Actl "Only supported on PHEV programs.  PlgActvArb_B_Actl HPCM will Tx on Powersplit PHEV’s,  On MHT PHEVs the PCM_HEV will Tx and HPCM will Rx. 
";
CM_ SG_ 131 VehYaw_W_Actl "CCMGenSigTimeoutTime=1000";
CM_ SG_ 836 FohFalt_D_Stat "Signal not transmitted on vehicles that do not have the Fuel operated heater feature.";
CM_ SG_ 836 FohEnbl_B_RqDrv "Signal not transmitted on vehicles that do not have the Fuel operated heater feature.";
CM_ SG_ 836 FohRqRun_B_Rq "Signal not transmitted on vehicles that do not have the Fuel operated heater feature.";
CM_ SG_ 836 HvacPrecondMode_D_Rq "Signal not transmitted on vehicles that do not have the Fuel operated heater feature.";
CM_ SG_ 836 HvacPrecondBlwr_D_Rq "Signal not transmitted on vehicles that do not have the Fuel operated heater feature.";
CM_ SG_ 836 Foh_D_Stat "Signal not transmitted on vehicles that do not have the Fuel operated heater feature.";
CM_ SG_ 836 FuelFlw_Vl_ActlFoh "Signal not transmitted on vehicles that do not have the Fuel operated heater feature.";
CM_ SG_ 836 EngClnt_Te_ActlFoh "Signal not transmitted on vehicles that do not have the Fuel operated heater feature.";
BA_DEF_ BO_  "FrameGatewayNetwork" STRING ;
BA_DEF_ BO_  "FrameGatewayMS1" HEX 0 1407;
BA_DEF_ BO_  "NetworkInitialization" ENUM  "No","Yes";
BA_DEF_ BO_  "FrameGatewayId" HEX 0 1407;
BA_DEF_ BO_  "EventRateOfChange" INT 10 10000;
BA_DEF_ BO_  "GenMsgStartDelayTime" INT 0 10000;
BA_DEF_ BO_  "GenMsgNrOfRepetition" INT 0 100;
BA_DEF_ BO_  "GenMsgDelayTime" INT 0 1000;
BA_DEF_ BO_  "GenMsgCycleTime" INT 0 100000;
BA_DEF_ BO_  "GenMsgSendType" ENUM  "FixedPeriodic","Event","EnabledPeriodic","NotUsed","NotUsed","EventPeriodic","NotUsed","NotUsed","NoMsgSendType";
BA_DEF_ SG_  "U_P702_MY2021_Tx" ENUM  "No","Yes";
BA_DEF_ SG_  "U_CX727_MY2021_Tx" ENUM  "No","Yes";
BA_DEF_ SG_  "U_VN127_MY20_Tx" ENUM  "No","Yes";
BA_DEF_ SG_  "U_H567_MY20_Tx" ENUM  "No","Yes";
BA_DEF_ SG_  "U_CX430_MY2021_Tx" ENUM  "No","Yes";
BA_DEF_ SG_  "U_U611_U625_MY20_Phev_Tx" ENUM  "No","Yes";
BA_DEF_ SG_  "U_B562_MY18_Diesel_Tx" ENUM  "No","Yes";
BA_DEF_ SG_  "U_CX482_CX483_MY20_Tx" ENUM  "No","Yes";
BA_DEF_ SG_  "U_U611_U625_MY20_Hev_Tx" ENUM  "No","Yes";
BA_DEF_ SG_  "U_U611_U625_MY20_Gas_Tx" ENUM  "No","Yes";
BA_DEF_ SG_  "U_B500_MY18_Diesel_Tx" ENUM  "No","Yes";
BA_DEF_ SG_  "U_B500_MY18_Gas_Tx" ENUM  "No","Yes";
BA_DEF_ SG_  "U_C490_MY18_Tx" ENUM  "No","Yes";
BA_DEF_ SG_  "U_B562_MY18_Gas_Tx" ENUM  "No","Yes";
BA_DEF_ SG_  "U_C519_MY18_5_Gas_Tx" ENUM  "No","Yes";
BA_DEF_ SG_  "U_C519_MY18_5_Diesel_Tx" ENUM  "No","Yes";
BA_DEF_ SG_  "U_B515_MCA_MY17_Gas_Tx" ENUM  "No","Yes";
BA_DEF_ SG_  "U_B515_MCA_MY17_Diesel_Tx" ENUM  "No","Yes";
BA_DEF_ SG_  "U_B479_MY17_Diesel_Tx" ENUM  "No","Yes";
BA_DEF_ SG_  "U_B479_MY17_Gas_Tx" ENUM  "No","Yes";
BA_DEF_ SG_  "U_P702_MY2021_Rx" ENUM  "No","Yes";
BA_DEF_ SG_  "U_CX727_MY2021_Rx" ENUM  "No","Yes";
BA_DEF_ SG_  "U_VN127_MY20_Rx" ENUM  "No","Yes";
BA_DEF_ SG_  "U_H567_MY20_Rx" ENUM  "No","Yes";
BA_DEF_ SG_  "U_CX430_MY2021_Rx" ENUM  "No","Yes";
BA_DEF_ SG_  "U_U611_U625_MY20_Phev_Rx" ENUM  "No","Yes";
BA_DEF_ SG_  "U_B562_MY18_Diesel_Rx" ENUM  "No","Yes";
BA_DEF_ SG_  "U_CX482_CX483_MY20_Rx" ENUM  "No","Yes";
BA_DEF_ SG_  "U_U611_U625_MY20_Hev_Rx" ENUM  "No","Yes";
BA_DEF_ SG_  "U_U611_U625_MY20_Gas_Rx" ENUM  "No","Yes";
BA_DEF_ SG_  "U_B500_MY18_Diesel_Rx" ENUM  "No","Yes";
BA_DEF_ SG_  "U_B500_MY18_Gas_Rx" ENUM  "No","Yes";
BA_DEF_ SG_  "U_C490_MY18_Rx" ENUM  "No","Yes";
BA_DEF_ SG_  "U_B562_MY18_Gas_Rx" ENUM  "No","Yes";
BA_DEF_ SG_  "U_LC1_B515_MY17_Gas_Rx" ENUM  "No","Yes";
BA_DEF_ SG_  "U_LC1_B515_MY17_Diesel_Rx" ENUM  "No","Yes";
BA_DEF_ SG_  "U_C519_MY18_5_Gas_Rx" ENUM  "No","Yes";
BA_DEF_ SG_  "U_C519_MY18_5_Diesel_Rx" ENUM  "No","Yes";
BA_DEF_ SG_  "U_B515_MCA_MY17_Gas_Rx" ENUM  "No","Yes";
BA_DEF_ SG_  "U_B515_MCA_MY17_Diesel_Rx" ENUM  "No","Yes";
BA_DEF_ SG_  "U_B479_MY17_Diesel_Rx" ENUM  "No","Yes";
BA_DEF_ SG_  "U_B479_MY17_Gas_Rx" ENUM  "No","Yes";
BA_DEF_ SG_  "U_B562LC_MY15_Gas_Rx" ENUM  "No","Yes";
BA_DEF_ SG_  "U_B562LC_MY15_Diesel_Rx" ENUM  "No","Yes";
BA_DEF_ SG_  "GenSigStartValue" HEX 0 268435455;
BA_DEF_ SG_  "MetaData" ENUM  "No","Yes";
BA_DEF_ SG_  "ContentDependant" ENUM  "No","Yes";
BA_DEF_ SG_  "GenSigStartValueInteger" INT 0 1000000000;
BA_DEF_ SG_  "UsedOnPgmDBC" ENUM  "No","Yes";
BA_DEF_ SG_  "CrossOver_InfoCAN" ENUM  "No","Yes";
BA_DEF_ SG_  "WakeupSignal" ENUM  "No","Yes";
BA_DEF_ SG_  "GenSigInactiveValue" INT 0 100000;
BA_DEF_ SG_  "GenSigSendType" ENUM  "Cyclic","OnWrite","vector_leerstring","OnChange","vector_leerstring","IfActive","vector_leerstring","NoSigSendType";
BA_DEF_ BO_  "AuthFreshnessCounterSyncAttempt" INT 0 2;
BA_DEF_ BO_  "GenMsgRoutingTimeoutTime" INT 0 5000;
BA_DEF_ BO_  "MessageGateway" ENUM  "No","Yes";
BA_DEF_ BO_  "NmAsrMessage" ENUM  "No","Yes";
BA_DEF_ BO_  "DiagState" ENUM  "No","Yes";
BA_DEF_ BO_  "DiagRequest" ENUM  "No","Yes";
BA_DEF_ BO_  "DiagResponse" ENUM  "No","Yes";
BA_DEF_ BO_  "NmMessage" ENUM  "No","Yes";
BA_DEF_ BO_  "GenMsgILSupport" ENUM  "No","Yes";
BA_DEF_DEF_  "FrameGatewayNetwork" "NONE";
BA_DEF_DEF_  "FrameGatewayMS1" 0;
BA_DEF_DEF_  "NetworkInitialization" "Yes";
BA_DEF_DEF_  "FrameGatewayId" 0;
BA_DEF_DEF_  "EventRateOfChange" 10000;
BA_DEF_DEF_  "GenMsgStartDelayTime" 0;
BA_DEF_DEF_  "GenMsgNrOfRepetition" 1;
BA_DEF_DEF_  "GenMsgDelayTime" 20;
BA_DEF_DEF_  "GenMsgCycleTime" 0;
BA_DEF_DEF_  "GenMsgSendType" "NoMsgSendType";
BA_DEF_DEF_  "U_P702_MY2021_Tx" "No";
BA_DEF_DEF_  "U_CX727_MY2021_Tx" "No";
BA_DEF_DEF_  "U_VN127_MY20_Tx" "No";
BA_DEF_DEF_  "U_H567_MY20_Tx" "No";
BA_DEF_DEF_  "U_CX430_MY2021_Tx" "No";
BA_DEF_DEF_  "U_U611_U625_MY20_Phev_Tx" "No";
BA_DEF_DEF_  "U_B562_MY18_Diesel_Tx" "No";
BA_DEF_DEF_  "U_CX482_CX483_MY20_Tx" "No";
BA_DEF_DEF_  "U_U611_U625_MY20_Hev_Tx" "No";
BA_DEF_DEF_  "U_U611_U625_MY20_Gas_Tx" "No";
BA_DEF_DEF_  "U_B500_MY18_Diesel_Tx" "No";
BA_DEF_DEF_  "U_B500_MY18_Gas_Tx" "No";
BA_DEF_DEF_  "U_C490_MY18_Tx" "No";
BA_DEF_DEF_  "U_B562_MY18_Gas_Tx" "No";
BA_DEF_DEF_  "U_C519_MY18_5_Gas_Tx" "No";
BA_DEF_DEF_  "U_C519_MY18_5_Diesel_Tx" "No";
BA_DEF_DEF_  "U_B515_MCA_MY17_Gas_Tx" "No";
BA_DEF_DEF_  "U_B515_MCA_MY17_Diesel_Tx" "No";
BA_DEF_DEF_  "U_B479_MY17_Diesel_Tx" "No";
BA_DEF_DEF_  "U_B479_MY17_Gas_Tx" "No";
BA_DEF_DEF_  "U_P702_MY2021_Rx" "No";
BA_DEF_DEF_  "U_CX727_MY2021_Rx" "No";
BA_DEF_DEF_  "U_VN127_MY20_Rx" "No";
BA_DEF_DEF_  "U_H567_MY20_Rx" "No";
BA_DEF_DEF_  "U_CX430_MY2021_Rx" "No";
BA_DEF_DEF_  "U_U611_U625_MY20_Phev_Rx" "No";
BA_DEF_DEF_  "U_B562_MY18_Diesel_Rx" "No";
BA_DEF_DEF_  "U_CX482_CX483_MY20_Rx" "No";
BA_DEF_DEF_  "U_U611_U625_MY20_Hev_Rx" "No";
BA_DEF_DEF_  "U_U611_U625_MY20_Gas_Rx" "No";
BA_DEF_DEF_  "U_B500_MY18_Diesel_Rx" "No";
BA_DEF_DEF_  "U_B500_MY18_Gas_Rx" "No";
BA_DEF_DEF_  "U_C490_MY18_Rx" "No";
BA_DEF_DEF_  "U_B562_MY18_Gas_Rx" "No";
BA_DEF_DEF_  "U_LC1_B515_MY17_Gas_Rx" "No";
BA_DEF_DEF_  "U_LC1_B515_MY17_Diesel_Rx" "No";
BA_DEF_DEF_  "U_C519_MY18_5_Gas_Rx" "No";
BA_DEF_DEF_  "U_C519_MY18_5_Diesel_Rx" "No";
BA_DEF_DEF_  "U_B515_MCA_MY17_Gas_Rx" "No";
BA_DEF_DEF_  "U_B515_MCA_MY17_Diesel_Rx" "No";
BA_DEF_DEF_  "U_B479_MY17_Diesel_Rx" "No";
BA_DEF_DEF_  "U_B479_MY17_Gas_Rx" "No";
BA_DEF_DEF_  "U_B562LC_MY15_Gas_Rx" "No";
BA_DEF_DEF_  "U_B562LC_MY15_Diesel_Rx" "No";
BA_DEF_DEF_  "GenSigStartValue" 0;
BA_DEF_DEF_  "MetaData" "No";
BA_DEF_DEF_  "ContentDependant" "No";
BA_DEF_DEF_  "GenSigStartValueInteger" 0;
BA_DEF_DEF_  "UsedOnPgmDBC" "Yes";
BA_DEF_DEF_  "CrossOver_InfoCAN" "No";
BA_DEF_DEF_  "WakeupSignal" "No";
BA_DEF_DEF_  "GenSigInactiveValue" 0;
BA_DEF_DEF_  "GenSigSendType" "NoSigSendType";
BA_DEF_DEF_  "AuthFreshnessCounterSyncAttempt" 2;
BA_DEF_DEF_  "GenMsgRoutingTimeoutTime" 0;
BA_DEF_DEF_  "MessageGateway" "No";
BA_DEF_DEF_  "NmAsrMessage" "No";
BA_DEF_DEF_  "DiagState" "No";
BA_DEF_DEF_  "DiagRequest" "No";
BA_DEF_DEF_  "DiagResponse" "No";
BA_DEF_DEF_  "NmMessage" "No";
BA_DEF_DEF_  "GenMsgILSupport" "Yes";
BA_ "FrameGatewayNetwork" BO_ 1095 "HS1_CAN";
BA_ "FrameGatewayId" BO_ 1095 1095;
BA_ "FrameGatewayNetwork" BO_ 948 "HS1_CAN";
BA_ "FrameGatewayId" BO_ 948 948;
BA_ "FrameGatewayNetwork" BO_ 840 "HS3_CAN";
BA_ "FrameGatewayId" BO_ 840 840;
BA_ "FrameGatewayNetwork" BO_ 132 "HS1_CAN";
BA_ "FrameGatewayId" BO_ 132 132;
BA_ "GenMsgSendType" BO_ 945 5;
BA_ "GenMsgCycleTime" BO_ 945 1000;
BA_ "FrameGatewayNetwork" BO_ 945 "HS1_CAN";
BA_ "FrameGatewayId" BO_ 945 945;
BA_ "GenMsgCycleTime" BO_ 981 1000;
BA_ "GenMsgSendType" BO_ 981 0;
BA_ "NetworkInitialization" BO_ 1446 0;
BA_ "GenMsgCycleTime" BO_ 1446 1000;
BA_ "GenMsgSendType" BO_ 1446 0;
BA_ "NmAsrMessage" BO_ 1446 1;
BA_ "GenMsgILSupport" BO_ 1446 0;
BA_ "GenMsgCycleTime" BO_ 839 100;
BA_ "GenMsgSendType" BO_ 839 0;
BA_ "GenMsgCycleTime" BO_ 850 500;
BA_ "GenMsgSendType" BO_ 850 0;
BA_ "GenMsgCycleTime" BO_ 849 500;
BA_ "GenMsgSendType" BO_ 849 0;
BA_ "FrameGatewayNetwork" BO_ 846 "HS3_CAN";
BA_ "FrameGatewayId" BO_ 846 846;
BA_ "GenMsgCycleTime" BO_ 845 1000;
BA_ "GenMsgSendType" BO_ 845 5;
BA_ "GenMsgCycleTime" BO_ 844 1000;
BA_ "GenMsgSendType" BO_ 844 5;
BA_ "GenMsgCycleTime" BO_ 843 1000;
BA_ "GenMsgSendType" BO_ 843 5;
BA_ "GenMsgCycleTime" BO_ 842 1000;
BA_ "GenMsgSendType" BO_ 842 5;
BA_ "NetworkInitialization" BO_ 1994 0;
BA_ "GenMsgDelayTime" BO_ 1994 0;
BA_ "GenMsgSendType" BO_ 1994 1;
BA_ "DiagResponse" BO_ 1994 1;
BA_ "GenMsgILSupport" BO_ 1994 0;
BA_ "NetworkInitialization" BO_ 1986 0;
BA_ "GenMsgDelayTime" BO_ 1986 0;
BA_ "GenMsgSendType" BO_ 1986 1;
BA_ "DiagRequest" BO_ 1986 1;
BA_ "GenMsgILSupport" BO_ 1986 0;
BA_ "GenMsgCycleTime" BO_ 958 100;
BA_ "GenMsgSendType" BO_ 958 5;
BA_ "GenMsgCycleTime" BO_ 827 1000;
BA_ "GenMsgSendType" BO_ 827 5;
BA_ "GenMsgRoutingTimeoutTime" BO_ 827 180;
BA_ "MessageGateway" BO_ 827 1;
BA_ "GenMsgCycleTime" BO_ 902 1000;
BA_ "GenMsgSendType" BO_ 902 5;
BA_ "GenMsgCycleTime" BO_ 765 1000;
BA_ "GenMsgSendType" BO_ 765 5;
BA_ "GenMsgSendType" BO_ 874 5;
BA_ "GenMsgCycleTime" BO_ 874 1000;
BA_ "FrameGatewayNetwork" BO_ 874 "HS3_CAN";
BA_ "FrameGatewayId" BO_ 874 874;
BA_ "GenMsgCycleTime" BO_ 359 1000;
BA_ "GenMsgSendType" BO_ 359 5;
BA_ "GenMsgRoutingTimeoutTime" BO_ 359 30;
BA_ "MessageGateway" BO_ 359 1;
BA_ "GenMsgCycleTime" BO_ 131 100;
BA_ "GenMsgSendType" BO_ 131 0;
BA_ "GenMsgCycleTime" BO_ 990 1000;
BA_ "GenMsgSendType" BO_ 990 5;
BA_ "GenMsgSendType" BO_ 1003 5;
BA_ "GenMsgCycleTime" BO_ 1003 1000;
BA_ "FrameGatewayNetwork" BO_ 1003 "HS1_CAN";
BA_ "FrameGatewayId" BO_ 1003 1003;
BA_ "NetworkInitialization" BO_ 1945 0;
BA_ "GenMsgDelayTime" BO_ 1945 0;
BA_ "GenMsgSendType" BO_ 1945 1;
BA_ "DiagResponse" BO_ 1945 1;
BA_ "GenMsgILSupport" BO_ 1945 0;
BA_ "GenMsgCycleTime" BO_ 836 1000;
BA_ "GenMsgSendType" BO_ 836 5;
BA_ "GenSigStartValue" SG_ 1095 HeadLghtOn_D_Rq 1;
BA_ "GenSigStartValueInteger" SG_ 1095 HeadLghtOn_D_Rq 1;
BA_ "WakeupSignal" SG_ 1095 HeadLghtOn_D_Rq 1;
BA_ "U_CX727_MY2021_Rx" SG_ 1095 RstrtSetting_T_Actl 1;
BA_ "U_CX430_MY2021_Rx" SG_ 1095 RstrtSetting_T_Actl 1;
BA_ "U_CX482_CX483_MY20_Rx" SG_ 1095 RstrtSetting_T_Actl 1;
BA_ "U_C519_MY18_5_Gas_Rx" SG_ 1095 RstrtSetting_T_Actl 1;
BA_ "U_C519_MY18_5_Diesel_Rx" SG_ 1095 RstrtSetting_T_Actl 1;
BA_ "U_B515_MCA_MY17_Gas_Rx" SG_ 1095 RstrtSetting_T_Actl 1;
BA_ "U_B515_MCA_MY17_Diesel_Rx" SG_ 1095 RstrtSetting_T_Actl 1;
BA_ "U_CX727_MY2021_Rx" SG_ 1095 Rstrt_T_Actl 1;
BA_ "U_CX430_MY2021_Rx" SG_ 1095 Rstrt_T_Actl 1;
BA_ "U_CX482_CX483_MY20_Rx" SG_ 1095 Rstrt_T_Actl 1;
BA_ "U_C519_MY18_5_Gas_Rx" SG_ 1095 Rstrt_T_Actl 1;
BA_ "U_C519_MY18_5_Diesel_Rx" SG_ 1095 Rstrt_T_Actl 1;
BA_ "U_B515_MCA_MY17_Gas_Rx" SG_ 1095 Rstrt_T_Actl 1;
BA_ "U_B515_MCA_MY17_Diesel_Rx" SG_ 1095 Rstrt_T_Actl 1;
BA_ "U_P702_MY2021_Rx" SG_ 948 Tire_Press_ILR_Stat 1;
BA_ "U_CX727_MY2021_Rx" SG_ 948 Tire_Press_ILR_Stat 1;
BA_ "U_VN127_MY20_Rx" SG_ 948 Tire_Press_ILR_Stat 1;
BA_ "U_H567_MY20_Rx" SG_ 948 Tire_Press_ILR_Stat 1;
BA_ "U_CX430_MY2021_Rx" SG_ 948 Tire_Press_ILR_Stat 1;
BA_ "U_U611_U625_MY20_Phev_Rx" SG_ 948 Tire_Press_ILR_Stat 1;
BA_ "U_CX482_CX483_MY20_Rx" SG_ 948 Tire_Press_ILR_Stat 1;
BA_ "U_U611_U625_MY20_Hev_Rx" SG_ 948 Tire_Press_ILR_Stat 1;
BA_ "U_U611_U625_MY20_Gas_Rx" SG_ 948 Tire_Press_ILR_Stat 1;
BA_ "U_C519_MY18_5_Gas_Rx" SG_ 948 Tire_Press_ILR_Stat 1;
BA_ "U_C519_MY18_5_Diesel_Rx" SG_ 948 Tire_Press_ILR_Stat 1;
BA_ "U_B515_MCA_MY17_Gas_Rx" SG_ 948 Tire_Press_ILR_Stat 1;
BA_ "U_B515_MCA_MY17_Diesel_Rx" SG_ 948 Tire_Press_ILR_Stat 1;
BA_ "U_B479_MY17_Diesel_Rx" SG_ 948 Tire_Press_ILR_Stat 1;
BA_ "U_B479_MY17_Gas_Rx" SG_ 948 Tire_Press_ILR_Stat 1;
BA_ "CrossOver_InfoCAN" SG_ 948 Tire_Press_ILR_Stat 1;
BA_ "U_P702_MY2021_Rx" SG_ 948 Tire_Press_IRR_Stat 1;
BA_ "U_CX727_MY2021_Rx" SG_ 948 Tire_Press_IRR_Stat 1;
BA_ "U_VN127_MY20_Rx" SG_ 948 Tire_Press_IRR_Stat 1;
BA_ "U_H567_MY20_Rx" SG_ 948 Tire_Press_IRR_Stat 1;
BA_ "U_CX430_MY2021_Rx" SG_ 948 Tire_Press_IRR_Stat 1;
BA_ "U_U611_U625_MY20_Phev_Rx" SG_ 948 Tire_Press_IRR_Stat 1;
BA_ "U_CX482_CX483_MY20_Rx" SG_ 948 Tire_Press_IRR_Stat 1;
BA_ "U_U611_U625_MY20_Hev_Rx" SG_ 948 Tire_Press_IRR_Stat 1;
BA_ "U_U611_U625_MY20_Gas_Rx" SG_ 948 Tire_Press_IRR_Stat 1;
BA_ "U_C519_MY18_5_Gas_Rx" SG_ 948 Tire_Press_IRR_Stat 1;
BA_ "U_C519_MY18_5_Diesel_Rx" SG_ 948 Tire_Press_IRR_Stat 1;
BA_ "U_B515_MCA_MY17_Gas_Rx" SG_ 948 Tire_Press_IRR_Stat 1;
BA_ "U_B515_MCA_MY17_Diesel_Rx" SG_ 948 Tire_Press_IRR_Stat 1;
BA_ "U_B479_MY17_Diesel_Rx" SG_ 948 Tire_Press_IRR_Stat 1;
BA_ "U_B479_MY17_Gas_Rx" SG_ 948 Tire_Press_IRR_Stat 1;
BA_ "CrossOver_InfoCAN" SG_ 948 Tire_Press_IRR_Stat 1;
BA_ "U_P702_MY2021_Rx" SG_ 948 Tire_Press_LR_OLR_Stat 1;
BA_ "U_CX727_MY2021_Rx" SG_ 948 Tire_Press_LR_OLR_Stat 1;
BA_ "U_VN127_MY20_Rx" SG_ 948 Tire_Press_LR_OLR_Stat 1;
BA_ "U_H567_MY20_Rx" SG_ 948 Tire_Press_LR_OLR_Stat 1;
BA_ "U_CX430_MY2021_Rx" SG_ 948 Tire_Press_LR_OLR_Stat 1;
BA_ "U_U611_U625_MY20_Phev_Rx" SG_ 948 Tire_Press_LR_OLR_Stat 1;
BA_ "U_CX482_CX483_MY20_Rx" SG_ 948 Tire_Press_LR_OLR_Stat 1;
BA_ "U_U611_U625_MY20_Hev_Rx" SG_ 948 Tire_Press_LR_OLR_Stat 1;
BA_ "U_U611_U625_MY20_Gas_Rx" SG_ 948 Tire_Press_LR_OLR_Stat 1;
BA_ "U_C519_MY18_5_Gas_Rx" SG_ 948 Tire_Press_LR_OLR_Stat 1;
BA_ "U_C519_MY18_5_Diesel_Rx" SG_ 948 Tire_Press_LR_OLR_Stat 1;
BA_ "U_B515_MCA_MY17_Gas_Rx" SG_ 948 Tire_Press_LR_OLR_Stat 1;
BA_ "U_B515_MCA_MY17_Diesel_Rx" SG_ 948 Tire_Press_LR_OLR_Stat 1;
BA_ "U_B479_MY17_Diesel_Rx" SG_ 948 Tire_Press_LR_OLR_Stat 1;
BA_ "U_B479_MY17_Gas_Rx" SG_ 948 Tire_Press_LR_OLR_Stat 1;
BA_ "CrossOver_InfoCAN" SG_ 948 Tire_Press_LR_OLR_Stat 1;
BA_ "U_P702_MY2021_Rx" SG_ 948 Tire_Press_RR_ORR_Stat 1;
BA_ "U_CX727_MY2021_Rx" SG_ 948 Tire_Press_RR_ORR_Stat 1;
BA_ "U_VN127_MY20_Rx" SG_ 948 Tire_Press_RR_ORR_Stat 1;
BA_ "U_H567_MY20_Rx" SG_ 948 Tire_Press_RR_ORR_Stat 1;
BA_ "U_CX430_MY2021_Rx" SG_ 948 Tire_Press_RR_ORR_Stat 1;
BA_ "U_U611_U625_MY20_Phev_Rx" SG_ 948 Tire_Press_RR_ORR_Stat 1;
BA_ "U_CX482_CX483_MY20_Rx" SG_ 948 Tire_Press_RR_ORR_Stat 1;
BA_ "U_U611_U625_MY20_Hev_Rx" SG_ 948 Tire_Press_RR_ORR_Stat 1;
BA_ "U_U611_U625_MY20_Gas_Rx" SG_ 948 Tire_Press_RR_ORR_Stat 1;
BA_ "U_C519_MY18_5_Gas_Rx" SG_ 948 Tire_Press_RR_ORR_Stat 1;
BA_ "U_C519_MY18_5_Diesel_Rx" SG_ 948 Tire_Press_RR_ORR_Stat 1;
BA_ "U_B515_MCA_MY17_Gas_Rx" SG_ 948 Tire_Press_RR_ORR_Stat 1;
BA_ "U_B515_MCA_MY17_Diesel_Rx" SG_ 948 Tire_Press_RR_ORR_Stat 1;
BA_ "U_B479_MY17_Diesel_Rx" SG_ 948 Tire_Press_RR_ORR_Stat 1;
BA_ "U_B479_MY17_Gas_Rx" SG_ 948 Tire_Press_RR_ORR_Stat 1;
BA_ "CrossOver_InfoCAN" SG_ 948 Tire_Press_RR_ORR_Stat 1;
BA_ "U_P702_MY2021_Rx" SG_ 948 Tire_Press_RF_Stat 1;
BA_ "U_CX727_MY2021_Rx" SG_ 948 Tire_Press_RF_Stat 1;
BA_ "U_VN127_MY20_Rx" SG_ 948 Tire_Press_RF_Stat 1;
BA_ "U_H567_MY20_Rx" SG_ 948 Tire_Press_RF_Stat 1;
BA_ "U_CX430_MY2021_Rx" SG_ 948 Tire_Press_RF_Stat 1;
BA_ "U_U611_U625_MY20_Phev_Rx" SG_ 948 Tire_Press_RF_Stat 1;
BA_ "U_CX482_CX483_MY20_Rx" SG_ 948 Tire_Press_RF_Stat 1;
BA_ "U_U611_U625_MY20_Hev_Rx" SG_ 948 Tire_Press_RF_Stat 1;
BA_ "U_U611_U625_MY20_Gas_Rx" SG_ 948 Tire_Press_RF_Stat 1;
BA_ "U_C519_MY18_5_Gas_Rx" SG_ 948 Tire_Press_RF_Stat 1;
BA_ "U_C519_MY18_5_Diesel_Rx" SG_ 948 Tire_Press_RF_Stat 1;
BA_ "U_B515_MCA_MY17_Gas_Rx" SG_ 948 Tire_Press_RF_Stat 1;
BA_ "U_B515_MCA_MY17_Diesel_Rx" SG_ 948 Tire_Press_RF_Stat 1;
BA_ "U_B479_MY17_Diesel_Rx" SG_ 948 Tire_Press_RF_Stat 1;
BA_ "U_B479_MY17_Gas_Rx" SG_ 948 Tire_Press_RF_Stat 1;
BA_ "CrossOver_InfoCAN" SG_ 948 Tire_Press_RF_Stat 1;
BA_ "U_P702_MY2021_Rx" SG_ 948 Tire_Press_LF_Stat 1;
BA_ "U_CX727_MY2021_Rx" SG_ 948 Tire_Press_LF_Stat 1;
BA_ "U_VN127_MY20_Rx" SG_ 948 Tire_Press_LF_Stat 1;
BA_ "U_H567_MY20_Rx" SG_ 948 Tire_Press_LF_Stat 1;
BA_ "U_CX430_MY2021_Rx" SG_ 948 Tire_Press_LF_Stat 1;
BA_ "U_U611_U625_MY20_Phev_Rx" SG_ 948 Tire_Press_LF_Stat 1;
BA_ "U_CX482_CX483_MY20_Rx" SG_ 948 Tire_Press_LF_Stat 1;
BA_ "U_U611_U625_MY20_Hev_Rx" SG_ 948 Tire_Press_LF_Stat 1;
BA_ "U_U611_U625_MY20_Gas_Rx" SG_ 948 Tire_Press_LF_Stat 1;
BA_ "U_C519_MY18_5_Gas_Rx" SG_ 948 Tire_Press_LF_Stat 1;
BA_ "U_C519_MY18_5_Diesel_Rx" SG_ 948 Tire_Press_LF_Stat 1;
BA_ "U_B515_MCA_MY17_Gas_Rx" SG_ 948 Tire_Press_LF_Stat 1;
BA_ "U_B515_MCA_MY17_Diesel_Rx" SG_ 948 Tire_Press_LF_Stat 1;
BA_ "U_B479_MY17_Diesel_Rx" SG_ 948 Tire_Press_LF_Stat 1;
BA_ "U_B479_MY17_Gas_Rx" SG_ 948 Tire_Press_LF_Stat 1;
BA_ "CrossOver_InfoCAN" SG_ 948 Tire_Press_LF_Stat 1;
BA_ "U_P702_MY2021_Rx" SG_ 948 Tire_Press_System_Stat 1;
BA_ "U_CX727_MY2021_Rx" SG_ 948 Tire_Press_System_Stat 1;
BA_ "U_VN127_MY20_Rx" SG_ 948 Tire_Press_System_Stat 1;
BA_ "U_H567_MY20_Rx" SG_ 948 Tire_Press_System_Stat 1;
BA_ "U_CX430_MY2021_Rx" SG_ 948 Tire_Press_System_Stat 1;
BA_ "U_U611_U625_MY20_Phev_Rx" SG_ 948 Tire_Press_System_Stat 1;
BA_ "U_CX482_CX483_MY20_Rx" SG_ 948 Tire_Press_System_Stat 1;
BA_ "U_U611_U625_MY20_Hev_Rx" SG_ 948 Tire_Press_System_Stat 1;
BA_ "U_U611_U625_MY20_Gas_Rx" SG_ 948 Tire_Press_System_Stat 1;
BA_ "U_C519_MY18_5_Gas_Rx" SG_ 948 Tire_Press_System_Stat 1;
BA_ "U_C519_MY18_5_Diesel_Rx" SG_ 948 Tire_Press_System_Stat 1;
BA_ "U_B515_MCA_MY17_Gas_Rx" SG_ 948 Tire_Press_System_Stat 1;
BA_ "U_B515_MCA_MY17_Diesel_Rx" SG_ 948 Tire_Press_System_Stat 1;
BA_ "U_B479_MY17_Diesel_Rx" SG_ 948 Tire_Press_System_Stat 1;
BA_ "U_B479_MY17_Gas_Rx" SG_ 948 Tire_Press_System_Stat 1;
BA_ "CrossOver_InfoCAN" SG_ 948 Tire_Press_System_Stat 1;
BA_ "U_P702_MY2021_Rx" SG_ 948 Tire_Press_Telltale 1;
BA_ "U_CX727_MY2021_Rx" SG_ 948 Tire_Press_Telltale 1;
BA_ "U_VN127_MY20_Rx" SG_ 948 Tire_Press_Telltale 1;
BA_ "U_H567_MY20_Rx" SG_ 948 Tire_Press_Telltale 1;
BA_ "U_CX430_MY2021_Rx" SG_ 948 Tire_Press_Telltale 1;
BA_ "U_U611_U625_MY20_Phev_Rx" SG_ 948 Tire_Press_Telltale 1;
BA_ "U_CX482_CX483_MY20_Rx" SG_ 948 Tire_Press_Telltale 1;
BA_ "U_U611_U625_MY20_Hev_Rx" SG_ 948 Tire_Press_Telltale 1;
BA_ "U_U611_U625_MY20_Gas_Rx" SG_ 948 Tire_Press_Telltale 1;
BA_ "U_C519_MY18_5_Gas_Rx" SG_ 948 Tire_Press_Telltale 1;
BA_ "U_C519_MY18_5_Diesel_Rx" SG_ 948 Tire_Press_Telltale 1;
BA_ "U_B515_MCA_MY17_Gas_Rx" SG_ 948 Tire_Press_Telltale 1;
BA_ "U_B515_MCA_MY17_Diesel_Rx" SG_ 948 Tire_Press_Telltale 1;
BA_ "U_B479_MY17_Diesel_Rx" SG_ 948 Tire_Press_Telltale 1;
BA_ "U_B479_MY17_Gas_Rx" SG_ 948 Tire_Press_Telltale 1;
BA_ "CrossOver_InfoCAN" SG_ 948 Tire_Press_Telltale 1;
BA_ "U_P702_MY2021_Rx" SG_ 948 TirePReset_D_Stat 1;
BA_ "U_CX727_MY2021_Rx" SG_ 948 TirePReset_D_Stat 1;
BA_ "U_VN127_MY20_Rx" SG_ 948 TirePReset_D_Stat 1;
BA_ "U_H567_MY20_Rx" SG_ 948 TirePReset_D_Stat 1;
BA_ "U_CX430_MY2021_Rx" SG_ 948 TirePReset_D_Stat 1;
BA_ "U_U611_U625_MY20_Phev_Rx" SG_ 948 TirePReset_D_Stat 1;
BA_ "U_CX482_CX483_MY20_Rx" SG_ 948 TirePReset_D_Stat 1;
BA_ "U_U611_U625_MY20_Hev_Rx" SG_ 948 TirePReset_D_Stat 1;
BA_ "U_U611_U625_MY20_Gas_Rx" SG_ 948 TirePReset_D_Stat 1;
BA_ "U_C519_MY18_5_Gas_Rx" SG_ 948 TirePReset_D_Stat 1;
BA_ "U_C519_MY18_5_Diesel_Rx" SG_ 948 TirePReset_D_Stat 1;
BA_ "U_B515_MCA_MY17_Gas_Rx" SG_ 948 TirePReset_D_Stat 1;
BA_ "U_B515_MCA_MY17_Diesel_Rx" SG_ 948 TirePReset_D_Stat 1;
BA_ "U_B479_MY17_Diesel_Rx" SG_ 948 TirePReset_D_Stat 1;
BA_ "U_B479_MY17_Gas_Rx" SG_ 948 TirePReset_D_Stat 1;
BA_ "CrossOver_InfoCAN" SG_ 948 TirePReset_D_Stat 1;
BA_ "CrossOver_InfoCAN" SG_ 840 FohT2Wednesday_T_Rq 1;
BA_ "ContentDependant" SG_ 840 FohT2Wednesday_T_Rq 1;
BA_ "U_C519_MY18_5_Diesel_Rx" SG_ 840 FohT2Wednesday_T_Rq 1;
BA_ "U_C519_MY18_5_Gas_Rx" SG_ 840 FohT2Wednesday_T_Rq 1;
BA_ "U_CX482_CX483_MY20_Rx" SG_ 840 FohT2Wednesday_T_Rq 1;
BA_ "CrossOver_InfoCAN" SG_ 840 FohT2Tuesday_T_Rq 1;
BA_ "ContentDependant" SG_ 840 FohT2Tuesday_T_Rq 1;
BA_ "U_C519_MY18_5_Diesel_Rx" SG_ 840 FohT2Tuesday_T_Rq 1;
BA_ "U_C519_MY18_5_Gas_Rx" SG_ 840 FohT2Tuesday_T_Rq 1;
BA_ "U_CX482_CX483_MY20_Rx" SG_ 840 FohT2Tuesday_T_Rq 1;
BA_ "CrossOver_InfoCAN" SG_ 840 FohT2Thursday_T_Rq 1;
BA_ "ContentDependant" SG_ 840 FohT2Thursday_T_Rq 1;
BA_ "U_C519_MY18_5_Diesel_Rx" SG_ 840 FohT2Thursday_T_Rq 1;
BA_ "U_C519_MY18_5_Gas_Rx" SG_ 840 FohT2Thursday_T_Rq 1;
BA_ "U_CX482_CX483_MY20_Rx" SG_ 840 FohT2Thursday_T_Rq 1;
BA_ "CrossOver_InfoCAN" SG_ 840 FohT2Sunday_T_Rq 1;
BA_ "ContentDependant" SG_ 840 FohT2Sunday_T_Rq 1;
BA_ "U_C519_MY18_5_Diesel_Rx" SG_ 840 FohT2Sunday_T_Rq 1;
BA_ "U_C519_MY18_5_Gas_Rx" SG_ 840 FohT2Sunday_T_Rq 1;
BA_ "U_CX482_CX483_MY20_Rx" SG_ 840 FohT2Sunday_T_Rq 1;
BA_ "CrossOver_InfoCAN" SG_ 840 FohT2Saturday_T_Rq 1;
BA_ "ContentDependant" SG_ 840 FohT2Saturday_T_Rq 1;
BA_ "U_C519_MY18_5_Diesel_Rx" SG_ 840 FohT2Saturday_T_Rq 1;
BA_ "U_C519_MY18_5_Gas_Rx" SG_ 840 FohT2Saturday_T_Rq 1;
BA_ "U_CX482_CX483_MY20_Rx" SG_ 840 FohT2Saturday_T_Rq 1;
BA_ "CrossOver_InfoCAN" SG_ 840 FohT2Monday_T_Rq 1;
BA_ "ContentDependant" SG_ 840 FohT2Monday_T_Rq 1;
BA_ "U_C519_MY18_5_Diesel_Rx" SG_ 840 FohT2Monday_T_Rq 1;
BA_ "U_C519_MY18_5_Gas_Rx" SG_ 840 FohT2Monday_T_Rq 1;
BA_ "U_CX482_CX483_MY20_Rx" SG_ 840 FohT2Monday_T_Rq 1;
BA_ "CrossOver_InfoCAN" SG_ 840 FohT2Friday_T_Rq 1;
BA_ "ContentDependant" SG_ 840 FohT2Friday_T_Rq 1;
BA_ "U_C519_MY18_5_Diesel_Rx" SG_ 840 FohT2Friday_T_Rq 1;
BA_ "U_C519_MY18_5_Gas_Rx" SG_ 840 FohT2Friday_T_Rq 1;
BA_ "U_CX482_CX483_MY20_Rx" SG_ 840 FohT2Friday_T_Rq 1;
BA_ "CrossOver_InfoCAN" SG_ 840 FohT1Wednesday_T_Rq 1;
BA_ "ContentDependant" SG_ 840 FohT1Wednesday_T_Rq 1;
BA_ "U_C519_MY18_5_Diesel_Rx" SG_ 840 FohT1Wednesday_T_Rq 1;
BA_ "U_C519_MY18_5_Gas_Rx" SG_ 840 FohT1Wednesday_T_Rq 1;
BA_ "U_CX482_CX483_MY20_Rx" SG_ 840 FohT1Wednesday_T_Rq 1;
BA_ "CrossOver_InfoCAN" SG_ 840 FohT1Tuesday_T_Rq 1;
BA_ "ContentDependant" SG_ 840 FohT1Tuesday_T_Rq 1;
BA_ "U_C519_MY18_5_Diesel_Rx" SG_ 840 FohT1Tuesday_T_Rq 1;
BA_ "U_C519_MY18_5_Gas_Rx" SG_ 840 FohT1Tuesday_T_Rq 1;
BA_ "U_CX482_CX483_MY20_Rx" SG_ 840 FohT1Tuesday_T_Rq 1;
BA_ "CrossOver_InfoCAN" SG_ 840 FohT1Thursday_T_Rq 1;
BA_ "ContentDependant" SG_ 840 FohT1Thursday_T_Rq 1;
BA_ "U_C519_MY18_5_Diesel_Rx" SG_ 840 FohT1Thursday_T_Rq 1;
BA_ "U_C519_MY18_5_Gas_Rx" SG_ 840 FohT1Thursday_T_Rq 1;
BA_ "U_CX482_CX483_MY20_Rx" SG_ 840 FohT1Thursday_T_Rq 1;
BA_ "CrossOver_InfoCAN" SG_ 840 FohT1Sunday_T_Rq 1;
BA_ "ContentDependant" SG_ 840 FohT1Sunday_T_Rq 1;
BA_ "U_C519_MY18_5_Diesel_Rx" SG_ 840 FohT1Sunday_T_Rq 1;
BA_ "U_C519_MY18_5_Gas_Rx" SG_ 840 FohT1Sunday_T_Rq 1;
BA_ "U_CX482_CX483_MY20_Rx" SG_ 840 FohT1Sunday_T_Rq 1;
BA_ "CrossOver_InfoCAN" SG_ 840 FohT1Saturday_T_Rq 1;
BA_ "ContentDependant" SG_ 840 FohT1Saturday_T_Rq 1;
BA_ "U_C519_MY18_5_Diesel_Rx" SG_ 840 FohT1Saturday_T_Rq 1;
BA_ "U_C519_MY18_5_Gas_Rx" SG_ 840 FohT1Saturday_T_Rq 1;
BA_ "U_CX482_CX483_MY20_Rx" SG_ 840 FohT1Saturday_T_Rq 1;
BA_ "CrossOver_InfoCAN" SG_ 840 FohT1Monday_T_Rq 1;
BA_ "ContentDependant" SG_ 840 FohT1Monday_T_Rq 1;
BA_ "U_C519_MY18_5_Diesel_Rx" SG_ 840 FohT1Monday_T_Rq 1;
BA_ "U_C519_MY18_5_Gas_Rx" SG_ 840 FohT1Monday_T_Rq 1;
BA_ "U_CX482_CX483_MY20_Rx" SG_ 840 FohT1Monday_T_Rq 1;
BA_ "CrossOver_InfoCAN" SG_ 840 FohT1Friday_T_Rq 1;
BA_ "ContentDependant" SG_ 840 FohT1Friday_T_Rq 1;
BA_ "U_C519_MY18_5_Diesel_Rx" SG_ 840 FohT1Friday_T_Rq 1;
BA_ "U_C519_MY18_5_Gas_Rx" SG_ 840 FohT1Friday_T_Rq 1;
BA_ "U_CX482_CX483_MY20_Rx" SG_ 840 FohT1Friday_T_Rq 1;
BA_ "U_CX482_CX483_MY20_Rx" SG_ 840 FohAddHeater_D_Rq 1;
BA_ "U_C519_MY18_5_Gas_Rx" SG_ 840 FohAddHeater_D_Rq 1;
BA_ "U_C519_MY18_5_Diesel_Rx" SG_ 840 FohAddHeater_D_Rq 1;
BA_ "U_CX482_CX483_MY20_Rx" SG_ 840 FohStrtDateYr_No_Rq 1;
BA_ "U_C519_MY18_5_Gas_Rx" SG_ 840 FohStrtDateYr_No_Rq 1;
BA_ "U_C519_MY18_5_Diesel_Rx" SG_ 840 FohStrtDateYr_No_Rq 1;
BA_ "U_CX482_CX483_MY20_Rx" SG_ 840 FohStrtDateDay_No_Rq 1;
BA_ "U_C519_MY18_5_Gas_Rx" SG_ 840 FohStrtDateDay_No_Rq 1;
BA_ "U_C519_MY18_5_Diesel_Rx" SG_ 840 FohStrtDateDay_No_Rq 1;
BA_ "U_P702_MY2021_Rx" SG_ 132 GlblClkYr_No_Actl 1;
BA_ "U_CX430_MY2021_Rx" SG_ 132 GlblClkYr_No_Actl 1;
BA_ "U_U611_U625_MY20_Phev_Rx" SG_ 132 GlblClkYr_No_Actl 1;
BA_ "U_U611_U625_MY20_Gas_Rx" SG_ 132 GlblClkYr_No_Actl 1;
BA_ "U_B515_MCA_MY17_Gas_Rx" SG_ 132 GlblClkYr_No_Actl 1;
BA_ "U_B515_MCA_MY17_Diesel_Rx" SG_ 132 GlblClkYr_No_Actl 1;
BA_ "U_B479_MY17_Diesel_Rx" SG_ 132 GlblClkYr_No_Actl 1;
BA_ "U_B479_MY17_Gas_Rx" SG_ 132 GlblClkYr_No_Actl 1;
BA_ "U_CX482_CX483_MY20_Rx" SG_ 132 GlblClkYr_No_Actl 1;
BA_ "U_C519_MY18_5_Gas_Rx" SG_ 132 GlblClkYr_No_Actl 1;
BA_ "U_C519_MY18_5_Diesel_Rx" SG_ 132 GlblClkYr_No_Actl 1;
BA_ "CrossOver_InfoCAN" SG_ 132 GlblClkYr_No_Actl 1;
BA_ "U_P702_MY2021_Rx" SG_ 132 GlblClkScnd_No_Actl 1;
BA_ "U_CX430_MY2021_Rx" SG_ 132 GlblClkScnd_No_Actl 1;
BA_ "U_U611_U625_MY20_Phev_Rx" SG_ 132 GlblClkScnd_No_Actl 1;
BA_ "U_U611_U625_MY20_Gas_Rx" SG_ 132 GlblClkScnd_No_Actl 1;
BA_ "U_B515_MCA_MY17_Gas_Rx" SG_ 132 GlblClkScnd_No_Actl 1;
BA_ "U_B515_MCA_MY17_Diesel_Rx" SG_ 132 GlblClkScnd_No_Actl 1;
BA_ "U_B479_MY17_Diesel_Rx" SG_ 132 GlblClkScnd_No_Actl 1;
BA_ "U_B479_MY17_Gas_Rx" SG_ 132 GlblClkScnd_No_Actl 1;
BA_ "U_CX482_CX483_MY20_Rx" SG_ 132 GlblClkScnd_No_Actl 1;
BA_ "U_C519_MY18_5_Gas_Rx" SG_ 132 GlblClkScnd_No_Actl 1;
BA_ "U_C519_MY18_5_Diesel_Rx" SG_ 132 GlblClkScnd_No_Actl 1;
BA_ "CrossOver_InfoCAN" SG_ 132 GlblClkScnd_No_Actl 1;
BA_ "U_P702_MY2021_Rx" SG_ 132 GlblClkMnte_No_Actl 1;
BA_ "U_CX430_MY2021_Rx" SG_ 132 GlblClkMnte_No_Actl 1;
BA_ "U_U611_U625_MY20_Phev_Rx" SG_ 132 GlblClkMnte_No_Actl 1;
BA_ "U_U611_U625_MY20_Gas_Rx" SG_ 132 GlblClkMnte_No_Actl 1;
BA_ "U_B515_MCA_MY17_Gas_Rx" SG_ 132 GlblClkMnte_No_Actl 1;
BA_ "U_B515_MCA_MY17_Diesel_Rx" SG_ 132 GlblClkMnte_No_Actl 1;
BA_ "U_B479_MY17_Diesel_Rx" SG_ 132 GlblClkMnte_No_Actl 1;
BA_ "U_B479_MY17_Gas_Rx" SG_ 132 GlblClkMnte_No_Actl 1;
BA_ "U_CX482_CX483_MY20_Rx" SG_ 132 GlblClkMnte_No_Actl 1;
BA_ "U_C519_MY18_5_Gas_Rx" SG_ 132 GlblClkMnte_No_Actl 1;
BA_ "U_C519_MY18_5_Diesel_Rx" SG_ 132 GlblClkMnte_No_Actl 1;
BA_ "CrossOver_InfoCAN" SG_ 132 GlblClkMnte_No_Actl 1;
BA_ "U_P702_MY2021_Rx" SG_ 132 GlblClkHr_No_Actl 1;
BA_ "U_CX430_MY2021_Rx" SG_ 132 GlblClkHr_No_Actl 1;
BA_ "U_U611_U625_MY20_Phev_Rx" SG_ 132 GlblClkHr_No_Actl 1;
BA_ "U_U611_U625_MY20_Gas_Rx" SG_ 132 GlblClkHr_No_Actl 1;
BA_ "U_B515_MCA_MY17_Gas_Rx" SG_ 132 GlblClkHr_No_Actl 1;
BA_ "U_B515_MCA_MY17_Diesel_Rx" SG_ 132 GlblClkHr_No_Actl 1;
BA_ "U_B479_MY17_Diesel_Rx" SG_ 132 GlblClkHr_No_Actl 1;
BA_ "U_B479_MY17_Gas_Rx" SG_ 132 GlblClkHr_No_Actl 1;
BA_ "U_CX482_CX483_MY20_Rx" SG_ 132 GlblClkHr_No_Actl 1;
BA_ "U_C519_MY18_5_Gas_Rx" SG_ 132 GlblClkHr_No_Actl 1;
BA_ "U_C519_MY18_5_Diesel_Rx" SG_ 132 GlblClkHr_No_Actl 1;
BA_ "CrossOver_InfoCAN" SG_ 132 GlblClkHr_No_Actl 1;
BA_ "U_P702_MY2021_Rx" SG_ 132 GlblClkDay_No_Actl 1;
BA_ "U_CX430_MY2021_Rx" SG_ 132 GlblClkDay_No_Actl 1;
BA_ "U_U611_U625_MY20_Phev_Rx" SG_ 132 GlblClkDay_No_Actl 1;
BA_ "U_U611_U625_MY20_Gas_Rx" SG_ 132 GlblClkDay_No_Actl 1;
BA_ "U_B515_MCA_MY17_Gas_Rx" SG_ 132 GlblClkDay_No_Actl 1;
BA_ "U_B515_MCA_MY17_Diesel_Rx" SG_ 132 GlblClkDay_No_Actl 1;
BA_ "U_B479_MY17_Diesel_Rx" SG_ 132 GlblClkDay_No_Actl 1;
BA_ "U_B479_MY17_Gas_Rx" SG_ 132 GlblClkDay_No_Actl 1;
BA_ "U_CX482_CX483_MY20_Rx" SG_ 132 GlblClkDay_No_Actl 1;
BA_ "U_C519_MY18_5_Gas_Rx" SG_ 132 GlblClkDay_No_Actl 1;
BA_ "U_C519_MY18_5_Diesel_Rx" SG_ 132 GlblClkDay_No_Actl 1;
BA_ "CrossOver_InfoCAN" SG_ 132 GlblClkDay_No_Actl 1;
BA_ "U_P702_MY2021_Rx" SG_ 945 KeyOffMde_D_Actl 1;
BA_ "U_H567_MY20_Rx" SG_ 945 KeyOffMde_D_Actl 1;
BA_ "U_CX430_MY2021_Rx" SG_ 945 KeyOffMde_D_Actl 1;
BA_ "U_CX727_MY2021_Rx" SG_ 945 KeyOffMde_D_Actl 1;
BA_ "U_U611_U625_MY20_Phev_Rx" SG_ 945 KeyOffMde_D_Actl 1;
BA_ "U_CX482_CX483_MY20_Rx" SG_ 945 KeyOffMde_D_Actl 1;
BA_ "U_U611_U625_MY20_Hev_Rx" SG_ 945 KeyOffMde_D_Actl 1;
BA_ "U_U611_U625_MY20_Gas_Rx" SG_ 945 KeyOffMde_D_Actl 1;
BA_ "U_C519_MY18_5_Gas_Rx" SG_ 945 KeyOffMde_D_Actl 1;
BA_ "U_C519_MY18_5_Diesel_Rx" SG_ 945 KeyOffMde_D_Actl 1;
BA_ "GenSigSendType" SG_ 945 KeyOffMde_D_Actl 3;
BA_ "GenSigSendType" SG_ 981 PreCondActv_B_Actl_UB 3;
BA_ "U_CX727_MY2021_Rx" SG_ 981 PreCondActv_B_Actl_UB 1;
BA_ "U_U611_U625_MY20_Phev_Rx" SG_ 981 PreCondActv_B_Actl_UB 1;
BA_ "U_CX482_CX483_MY20_Rx" SG_ 981 PreCondActv_B_Actl_UB 1;
BA_ "U_U611_U625_MY20_Hev_Rx" SG_ 981 PreCondActv_B_Actl_UB 1;
BA_ "U_U611_U625_MY20_Gas_Rx" SG_ 981 PreCondActv_B_Actl_UB 1;
BA_ "GenSigSendType" SG_ 981 HvacPrecondRecirc_D_Rq_UB 3;
BA_ "U_CX727_MY2021_Rx" SG_ 981 HvacPrecondRecirc_D_Rq_UB 1;
BA_ "U_U611_U625_MY20_Phev_Rx" SG_ 981 HvacPrecondRecirc_D_Rq_UB 1;
BA_ "U_CX482_CX483_MY20_Rx" SG_ 981 HvacPrecondRecirc_D_Rq_UB 1;
BA_ "U_U611_U625_MY20_Hev_Rx" SG_ 981 HvacPrecondRecirc_D_Rq_UB 1;
BA_ "U_U611_U625_MY20_Gas_Rx" SG_ 981 HvacPrecondRecirc_D_Rq_UB 1;
BA_ "GenSigSendType" SG_ 981 HvacPrecondMode2_D_Rq_UB 3;
BA_ "U_CX727_MY2021_Rx" SG_ 981 HvacPrecondMode2_D_Rq_UB 1;
BA_ "U_U611_U625_MY20_Phev_Rx" SG_ 981 HvacPrecondMode2_D_Rq_UB 1;
BA_ "U_CX482_CX483_MY20_Rx" SG_ 981 HvacPrecondMode2_D_Rq_UB 1;
BA_ "U_U611_U625_MY20_Hev_Rx" SG_ 981 HvacPrecondMode2_D_Rq_UB 1;
BA_ "U_U611_U625_MY20_Gas_Rx" SG_ 981 HvacPrecondMode2_D_Rq_UB 1;
BA_ "GenSigSendType" SG_ 981 HvacPrecondBlwr2_D_Rq_UB 3;
BA_ "U_CX727_MY2021_Rx" SG_ 981 HvacPrecondBlwr2_D_Rq_UB 1;
BA_ "U_U611_U625_MY20_Phev_Rx" SG_ 981 HvacPrecondBlwr2_D_Rq_UB 1;
BA_ "U_CX482_CX483_MY20_Rx" SG_ 981 HvacPrecondBlwr2_D_Rq_UB 1;
BA_ "U_U611_U625_MY20_Hev_Rx" SG_ 981 HvacPrecondBlwr2_D_Rq_UB 1;
BA_ "U_U611_U625_MY20_Gas_Rx" SG_ 981 HvacPrecondBlwr2_D_Rq_UB 1;
BA_ "GenSigSendType" SG_ 981 HvacPrecondAC_D_Rq_UB 3;
BA_ "U_CX727_MY2021_Rx" SG_ 981 HvacPrecondAC_D_Rq_UB 1;
BA_ "U_U611_U625_MY20_Phev_Rx" SG_ 981 HvacPrecondAC_D_Rq_UB 1;
BA_ "U_CX482_CX483_MY20_Rx" SG_ 981 HvacPrecondAC_D_Rq_UB 1;
BA_ "U_U611_U625_MY20_Hev_Rx" SG_ 981 HvacPrecondAC_D_Rq_UB 1;
BA_ "U_U611_U625_MY20_Gas_Rx" SG_ 981 HvacPrecondAC_D_Rq_UB 1;
BA_ "GenSigSendType" SG_ 981 HvacPrecond_Te_Rq_UB 3;
BA_ "U_CX727_MY2021_Rx" SG_ 981 HvacPrecond_Te_Rq_UB 1;
BA_ "U_U611_U625_MY20_Phev_Rx" SG_ 981 HvacPrecond_Te_Rq_UB 1;
BA_ "U_CX482_CX483_MY20_Rx" SG_ 981 HvacPrecond_Te_Rq_UB 1;
BA_ "U_U611_U625_MY20_Hev_Rx" SG_ 981 HvacPrecond_Te_Rq_UB 1;
BA_ "U_U611_U625_MY20_Gas_Rx" SG_ 981 HvacPrecond_Te_Rq_UB 1;
BA_ "GenSigSendType" SG_ 981 DrvCondTpRrDefrs_B_Rq_UB 3;
BA_ "U_CX727_MY2021_Rx" SG_ 981 DrvCondTpRrDefrs_B_Rq_UB 1;
BA_ "U_U611_U625_MY20_Phev_Rx" SG_ 981 DrvCondTpRrDefrs_B_Rq_UB 1;
BA_ "U_CX482_CX483_MY20_Rx" SG_ 981 DrvCondTpRrDefrs_B_Rq_UB 1;
BA_ "U_U611_U625_MY20_Hev_Rx" SG_ 981 DrvCondTpRrDefrs_B_Rq_UB 1;
BA_ "U_U611_U625_MY20_Gas_Rx" SG_ 981 DrvCondTpRrDefrs_B_Rq_UB 1;
BA_ "GenSigSendType" SG_ 981 PreCondActv_B_Actl 3;
BA_ "U_CX727_MY2021_Rx" SG_ 981 PreCondActv_B_Actl 1;
BA_ "U_U611_U625_MY20_Phev_Rx" SG_ 981 PreCondActv_B_Actl 1;
BA_ "U_CX482_CX483_MY20_Rx" SG_ 981 PreCondActv_B_Actl 1;
BA_ "U_U611_U625_MY20_Hev_Rx" SG_ 981 PreCondActv_B_Actl 1;
BA_ "U_U611_U625_MY20_Gas_Rx" SG_ 981 PreCondActv_B_Actl 1;
BA_ "GenSigSendType" SG_ 981 HvacPrecondRecirc_D_Rq 3;
BA_ "U_CX727_MY2021_Rx" SG_ 981 HvacPrecondRecirc_D_Rq 1;
BA_ "U_U611_U625_MY20_Phev_Rx" SG_ 981 HvacPrecondRecirc_D_Rq 1;
BA_ "U_CX482_CX483_MY20_Rx" SG_ 981 HvacPrecondRecirc_D_Rq 1;
BA_ "U_U611_U625_MY20_Hev_Rx" SG_ 981 HvacPrecondRecirc_D_Rq 1;
BA_ "U_U611_U625_MY20_Gas_Rx" SG_ 981 HvacPrecondRecirc_D_Rq 1;
BA_ "GenSigSendType" SG_ 981 HvacPrecondMode2_D_Rq 3;
BA_ "U_CX727_MY2021_Rx" SG_ 981 HvacPrecondMode2_D_Rq 1;
BA_ "U_U611_U625_MY20_Phev_Rx" SG_ 981 HvacPrecondMode2_D_Rq 1;
BA_ "U_CX482_CX483_MY20_Rx" SG_ 981 HvacPrecondMode2_D_Rq 1;
BA_ "U_U611_U625_MY20_Hev_Rx" SG_ 981 HvacPrecondMode2_D_Rq 1;
BA_ "U_U611_U625_MY20_Gas_Rx" SG_ 981 HvacPrecondMode2_D_Rq 1;
BA_ "ContentDependant" SG_ 981 HvacPrecondMode2_D_Rq 1;
BA_ "WakeupSignal" SG_ 981 HvacPrecondMode2_D_Rq 1;
BA_ "GenSigSendType" SG_ 981 HvacPrecondBlwr2_D_Rq 3;
BA_ "U_CX727_MY2021_Rx" SG_ 981 HvacPrecondBlwr2_D_Rq 1;
BA_ "U_U611_U625_MY20_Phev_Rx" SG_ 981 HvacPrecondBlwr2_D_Rq 1;
BA_ "U_CX482_CX483_MY20_Rx" SG_ 981 HvacPrecondBlwr2_D_Rq 1;
BA_ "U_U611_U625_MY20_Hev_Rx" SG_ 981 HvacPrecondBlwr2_D_Rq 1;
BA_ "U_U611_U625_MY20_Gas_Rx" SG_ 981 HvacPrecondBlwr2_D_Rq 1;
BA_ "ContentDependant" SG_ 981 HvacPrecondBlwr2_D_Rq 1;
BA_ "WakeupSignal" SG_ 981 HvacPrecondBlwr2_D_Rq 1;
BA_ "GenSigSendType" SG_ 981 HvacPrecondAC_D_Rq 3;
BA_ "U_CX727_MY2021_Rx" SG_ 981 HvacPrecondAC_D_Rq 1;
BA_ "U_U611_U625_MY20_Phev_Rx" SG_ 981 HvacPrecondAC_D_Rq 1;
BA_ "U_CX482_CX483_MY20_Rx" SG_ 981 HvacPrecondAC_D_Rq 1;
BA_ "U_U611_U625_MY20_Hev_Rx" SG_ 981 HvacPrecondAC_D_Rq 1;
BA_ "U_U611_U625_MY20_Gas_Rx" SG_ 981 HvacPrecondAC_D_Rq 1;
BA_ "GenSigSendType" SG_ 981 DrvCondTpRrDefrs_B_Rq 3;
BA_ "U_CX727_MY2021_Rx" SG_ 981 DrvCondTpRrDefrs_B_Rq 1;
BA_ "U_U611_U625_MY20_Phev_Rx" SG_ 981 DrvCondTpRrDefrs_B_Rq 1;
BA_ "U_CX482_CX483_MY20_Rx" SG_ 981 DrvCondTpRrDefrs_B_Rq 1;
BA_ "U_U611_U625_MY20_Hev_Rx" SG_ 981 DrvCondTpRrDefrs_B_Rq 1;
BA_ "U_U611_U625_MY20_Gas_Rx" SG_ 981 DrvCondTpRrDefrs_B_Rq 1;
BA_ "GenSigSendType" SG_ 981 HvacPrecond_Te_Rq 3;
BA_ "U_CX727_MY2021_Rx" SG_ 981 HvacPrecond_Te_Rq 1;
BA_ "U_U611_U625_MY20_Phev_Rx" SG_ 981 HvacPrecond_Te_Rq 1;
BA_ "U_CX482_CX483_MY20_Rx" SG_ 981 HvacPrecond_Te_Rq 1;
BA_ "U_U611_U625_MY20_Hev_Rx" SG_ 981 HvacPrecond_Te_Rq 1;
BA_ "U_U611_U625_MY20_Gas_Rx" SG_ 981 HvacPrecond_Te_Rq 1;
BA_ "GenSigStartValue" SG_ 981 HvacPrecond_Te_Rq 2;
BA_ "GenSigStartValueInteger" SG_ 981 HvacPrecond_Te_Rq 2;
BA_ "U_CX727_MY2021_Tx" SG_ 1446 RGTM_GWOnBoardTester 1;
BA_ "U_U611_U625_MY20_Phev_Tx" SG_ 1446 RGTM_GWOnBoardTester 1;
BA_ "U_CX482_CX483_MY20_Tx" SG_ 1446 RGTM_GWOnBoardTester 1;
BA_ "U_U611_U625_MY20_Hev_Tx" SG_ 1446 RGTM_GWOnBoardTester 1;
BA_ "U_U611_U625_MY20_Gas_Tx" SG_ 1446 RGTM_GWOnBoardTester 1;
BA_ "U_C519_MY18_5_Gas_Tx" SG_ 1446 RGTM_GWOnBoardTester 1;
BA_ "U_C519_MY18_5_Diesel_Tx" SG_ 1446 RGTM_GWOnBoardTester 1;
BA_ "U_P702_MY2021_Rx" SG_ 1446 RGTM_GWOnBoardTester 1;
BA_ "U_U611_U625_MY20_Phev_Rx" SG_ 1446 RGTM_GWOnBoardTester 1;
BA_ "U_CX482_CX483_MY20_Rx" SG_ 1446 RGTM_GWOnBoardTester 1;
BA_ "U_U611_U625_MY20_Hev_Rx" SG_ 1446 RGTM_GWOnBoardTester 1;
BA_ "U_U611_U625_MY20_Gas_Rx" SG_ 1446 RGTM_GWOnBoardTester 1;
BA_ "U_C519_MY18_5_Gas_Rx" SG_ 1446 RGTM_GWOnBoardTester 1;
BA_ "U_C519_MY18_5_Diesel_Rx" SG_ 1446 RGTM_GWOnBoardTester 1;
BA_ "GenSigStartValue" SG_ 1446 RGTM_GWOnBoardTester 255;
BA_ "ContentDependant" SG_ 1446 RGTM_GWOnBoardTester 1;
BA_ "GenSigStartValueInteger" SG_ 1446 RGTM_GWOnBoardTester 255;
BA_ "U_CX727_MY2021_Tx" SG_ 1446 RGTM_GWNMProxy 1;
BA_ "U_U611_U625_MY20_Phev_Tx" SG_ 1446 RGTM_GWNMProxy 1;
BA_ "U_CX482_CX483_MY20_Tx" SG_ 1446 RGTM_GWNMProxy 1;
BA_ "U_U611_U625_MY20_Hev_Tx" SG_ 1446 RGTM_GWNMProxy 1;
BA_ "U_U611_U625_MY20_Gas_Tx" SG_ 1446 RGTM_GWNMProxy 1;
BA_ "U_C519_MY18_5_Gas_Tx" SG_ 1446 RGTM_GWNMProxy 1;
BA_ "U_C519_MY18_5_Diesel_Tx" SG_ 1446 RGTM_GWNMProxy 1;
BA_ "U_P702_MY2021_Rx" SG_ 1446 RGTM_GWNMProxy 1;
BA_ "U_U611_U625_MY20_Phev_Rx" SG_ 1446 RGTM_GWNMProxy 1;
BA_ "U_CX482_CX483_MY20_Rx" SG_ 1446 RGTM_GWNMProxy 1;
BA_ "U_U611_U625_MY20_Hev_Rx" SG_ 1446 RGTM_GWNMProxy 1;
BA_ "U_U611_U625_MY20_Gas_Rx" SG_ 1446 RGTM_GWNMProxy 1;
BA_ "U_C519_MY18_5_Gas_Rx" SG_ 1446 RGTM_GWNMProxy 1;
BA_ "U_C519_MY18_5_Diesel_Rx" SG_ 1446 RGTM_GWNMProxy 1;
BA_ "GenSigStartValue" SG_ 1446 RGTM_GWNMProxy 255;
BA_ "ContentDependant" SG_ 1446 RGTM_GWNMProxy 1;
BA_ "GenSigStartValueInteger" SG_ 1446 RGTM_GWNMProxy 255;
BA_ "U_CX727_MY2021_Tx" SG_ 1446 RGTM_AutoSarNMReserved4 1;
BA_ "U_U611_U625_MY20_Phev_Tx" SG_ 1446 RGTM_AutoSarNMReserved4 1;
BA_ "U_CX482_CX483_MY20_Tx" SG_ 1446 RGTM_AutoSarNMReserved4 1;
BA_ "U_U611_U625_MY20_Hev_Tx" SG_ 1446 RGTM_AutoSarNMReserved4 1;
BA_ "U_U611_U625_MY20_Gas_Tx" SG_ 1446 RGTM_AutoSarNMReserved4 1;
BA_ "U_C519_MY18_5_Gas_Tx" SG_ 1446 RGTM_AutoSarNMReserved4 1;
BA_ "U_C519_MY18_5_Diesel_Tx" SG_ 1446 RGTM_AutoSarNMReserved4 1;
BA_ "U_P702_MY2021_Rx" SG_ 1446 RGTM_AutoSarNMReserved4 1;
BA_ "U_U611_U625_MY20_Phev_Rx" SG_ 1446 RGTM_AutoSarNMReserved4 1;
BA_ "U_CX482_CX483_MY20_Rx" SG_ 1446 RGTM_AutoSarNMReserved4 1;
BA_ "U_U611_U625_MY20_Hev_Rx" SG_ 1446 RGTM_AutoSarNMReserved4 1;
BA_ "U_U611_U625_MY20_Gas_Rx" SG_ 1446 RGTM_AutoSarNMReserved4 1;
BA_ "U_C519_MY18_5_Gas_Rx" SG_ 1446 RGTM_AutoSarNMReserved4 1;
BA_ "U_C519_MY18_5_Diesel_Rx" SG_ 1446 RGTM_AutoSarNMReserved4 1;
BA_ "GenSigStartValue" SG_ 1446 RGTM_AutoSarNMReserved4 255;
BA_ "ContentDependant" SG_ 1446 RGTM_AutoSarNMReserved4 1;
BA_ "GenSigStartValueInteger" SG_ 1446 RGTM_AutoSarNMReserved4 255;
BA_ "U_CX727_MY2021_Tx" SG_ 1446 RGTM_AutoSarNMReserved3 1;
BA_ "U_U611_U625_MY20_Phev_Tx" SG_ 1446 RGTM_AutoSarNMReserved3 1;
BA_ "U_CX482_CX483_MY20_Tx" SG_ 1446 RGTM_AutoSarNMReserved3 1;
BA_ "U_U611_U625_MY20_Hev_Tx" SG_ 1446 RGTM_AutoSarNMReserved3 1;
BA_ "U_U611_U625_MY20_Gas_Tx" SG_ 1446 RGTM_AutoSarNMReserved3 1;
BA_ "U_C519_MY18_5_Gas_Tx" SG_ 1446 RGTM_AutoSarNMReserved3 1;
BA_ "U_C519_MY18_5_Diesel_Tx" SG_ 1446 RGTM_AutoSarNMReserved3 1;
BA_ "U_P702_MY2021_Rx" SG_ 1446 RGTM_AutoSarNMReserved3 1;
BA_ "U_U611_U625_MY20_Phev_Rx" SG_ 1446 RGTM_AutoSarNMReserved3 1;
BA_ "U_CX482_CX483_MY20_Rx" SG_ 1446 RGTM_AutoSarNMReserved3 1;
BA_ "U_U611_U625_MY20_Hev_Rx" SG_ 1446 RGTM_AutoSarNMReserved3 1;
BA_ "U_U611_U625_MY20_Gas_Rx" SG_ 1446 RGTM_AutoSarNMReserved3 1;
BA_ "U_C519_MY18_5_Gas_Rx" SG_ 1446 RGTM_AutoSarNMReserved3 1;
BA_ "U_C519_MY18_5_Diesel_Rx" SG_ 1446 RGTM_AutoSarNMReserved3 1;
BA_ "GenSigStartValue" SG_ 1446 RGTM_AutoSarNMReserved3 255;
BA_ "ContentDependant" SG_ 1446 RGTM_AutoSarNMReserved3 1;
BA_ "GenSigStartValueInteger" SG_ 1446 RGTM_AutoSarNMReserved3 255;
BA_ "U_CX727_MY2021_Tx" SG_ 1446 RGTM_AutoSarNMReserved2 1;
BA_ "U_U611_U625_MY20_Phev_Tx" SG_ 1446 RGTM_AutoSarNMReserved2 1;
BA_ "U_CX482_CX483_MY20_Tx" SG_ 1446 RGTM_AutoSarNMReserved2 1;
BA_ "U_U611_U625_MY20_Hev_Tx" SG_ 1446 RGTM_AutoSarNMReserved2 1;
BA_ "U_U611_U625_MY20_Gas_Tx" SG_ 1446 RGTM_AutoSarNMReserved2 1;
BA_ "U_C519_MY18_5_Gas_Tx" SG_ 1446 RGTM_AutoSarNMReserved2 1;
BA_ "U_C519_MY18_5_Diesel_Tx" SG_ 1446 RGTM_AutoSarNMReserved2 1;
BA_ "U_P702_MY2021_Rx" SG_ 1446 RGTM_AutoSarNMReserved2 1;
BA_ "U_U611_U625_MY20_Phev_Rx" SG_ 1446 RGTM_AutoSarNMReserved2 1;
BA_ "U_CX482_CX483_MY20_Rx" SG_ 1446 RGTM_AutoSarNMReserved2 1;
BA_ "U_U611_U625_MY20_Hev_Rx" SG_ 1446 RGTM_AutoSarNMReserved2 1;
BA_ "U_U611_U625_MY20_Gas_Rx" SG_ 1446 RGTM_AutoSarNMReserved2 1;
BA_ "U_C519_MY18_5_Gas_Rx" SG_ 1446 RGTM_AutoSarNMReserved2 1;
BA_ "U_C519_MY18_5_Diesel_Rx" SG_ 1446 RGTM_AutoSarNMReserved2 1;
BA_ "GenSigStartValue" SG_ 1446 RGTM_AutoSarNMReserved2 255;
BA_ "ContentDependant" SG_ 1446 RGTM_AutoSarNMReserved2 1;
BA_ "GenSigStartValueInteger" SG_ 1446 RGTM_AutoSarNMReserved2 255;
BA_ "U_CX727_MY2021_Tx" SG_ 1446 RGTM_AutoSarNMReserved1 1;
BA_ "U_U611_U625_MY20_Phev_Tx" SG_ 1446 RGTM_AutoSarNMReserved1 1;
BA_ "U_CX482_CX483_MY20_Tx" SG_ 1446 RGTM_AutoSarNMReserved1 1;
BA_ "U_U611_U625_MY20_Hev_Tx" SG_ 1446 RGTM_AutoSarNMReserved1 1;
BA_ "U_U611_U625_MY20_Gas_Tx" SG_ 1446 RGTM_AutoSarNMReserved1 1;
BA_ "U_C519_MY18_5_Gas_Tx" SG_ 1446 RGTM_AutoSarNMReserved1 1;
BA_ "U_C519_MY18_5_Diesel_Tx" SG_ 1446 RGTM_AutoSarNMReserved1 1;
BA_ "U_P702_MY2021_Rx" SG_ 1446 RGTM_AutoSarNMReserved1 1;
BA_ "U_U611_U625_MY20_Phev_Rx" SG_ 1446 RGTM_AutoSarNMReserved1 1;
BA_ "U_CX482_CX483_MY20_Rx" SG_ 1446 RGTM_AutoSarNMReserved1 1;
BA_ "U_U611_U625_MY20_Hev_Rx" SG_ 1446 RGTM_AutoSarNMReserved1 1;
BA_ "U_U611_U625_MY20_Gas_Rx" SG_ 1446 RGTM_AutoSarNMReserved1 1;
BA_ "U_C519_MY18_5_Gas_Rx" SG_ 1446 RGTM_AutoSarNMReserved1 1;
BA_ "U_C519_MY18_5_Diesel_Rx" SG_ 1446 RGTM_AutoSarNMReserved1 1;
BA_ "GenSigStartValue" SG_ 1446 RGTM_AutoSarNMReserved1 255;
BA_ "ContentDependant" SG_ 1446 RGTM_AutoSarNMReserved1 1;
BA_ "GenSigStartValueInteger" SG_ 1446 RGTM_AutoSarNMReserved1 255;
BA_ "U_CX727_MY2021_Tx" SG_ 1446 RGTM_AutoSarNMNodeId 1;
BA_ "U_U611_U625_MY20_Phev_Tx" SG_ 1446 RGTM_AutoSarNMNodeId 1;
BA_ "U_CX482_CX483_MY20_Tx" SG_ 1446 RGTM_AutoSarNMNodeId 1;
BA_ "U_U611_U625_MY20_Hev_Tx" SG_ 1446 RGTM_AutoSarNMNodeId 1;
BA_ "U_U611_U625_MY20_Gas_Tx" SG_ 1446 RGTM_AutoSarNMNodeId 1;
BA_ "U_C519_MY18_5_Gas_Tx" SG_ 1446 RGTM_AutoSarNMNodeId 1;
BA_ "U_C519_MY18_5_Diesel_Tx" SG_ 1446 RGTM_AutoSarNMNodeId 1;
BA_ "U_P702_MY2021_Rx" SG_ 1446 RGTM_AutoSarNMNodeId 1;
BA_ "U_U611_U625_MY20_Phev_Rx" SG_ 1446 RGTM_AutoSarNMNodeId 1;
BA_ "U_CX482_CX483_MY20_Rx" SG_ 1446 RGTM_AutoSarNMNodeId 1;
BA_ "U_U611_U625_MY20_Hev_Rx" SG_ 1446 RGTM_AutoSarNMNodeId 1;
BA_ "U_U611_U625_MY20_Gas_Rx" SG_ 1446 RGTM_AutoSarNMNodeId 1;
BA_ "U_C519_MY18_5_Gas_Rx" SG_ 1446 RGTM_AutoSarNMNodeId 1;
BA_ "U_C519_MY18_5_Diesel_Rx" SG_ 1446 RGTM_AutoSarNMNodeId 1;
BA_ "GenSigStartValue" SG_ 1446 RGTM_AutoSarNMNodeId 166;
BA_ "ContentDependant" SG_ 1446 RGTM_AutoSarNMNodeId 1;
BA_ "GenSigStartValueInteger" SG_ 1446 RGTM_AutoSarNMNodeId 166;
BA_ "U_CX727_MY2021_Tx" SG_ 1446 RGTM_AutoSarNMControl 1;
BA_ "U_U611_U625_MY20_Phev_Tx" SG_ 1446 RGTM_AutoSarNMControl 1;
BA_ "U_CX482_CX483_MY20_Tx" SG_ 1446 RGTM_AutoSarNMControl 1;
BA_ "U_U611_U625_MY20_Hev_Tx" SG_ 1446 RGTM_AutoSarNMControl 1;
BA_ "U_U611_U625_MY20_Gas_Tx" SG_ 1446 RGTM_AutoSarNMControl 1;
BA_ "U_C519_MY18_5_Gas_Tx" SG_ 1446 RGTM_AutoSarNMControl 1;
BA_ "U_C519_MY18_5_Diesel_Tx" SG_ 1446 RGTM_AutoSarNMControl 1;
BA_ "U_P702_MY2021_Rx" SG_ 1446 RGTM_AutoSarNMControl 1;
BA_ "U_U611_U625_MY20_Phev_Rx" SG_ 1446 RGTM_AutoSarNMControl 1;
BA_ "U_CX482_CX483_MY20_Rx" SG_ 1446 RGTM_AutoSarNMControl 1;
BA_ "U_U611_U625_MY20_Hev_Rx" SG_ 1446 RGTM_AutoSarNMControl 1;
BA_ "U_U611_U625_MY20_Gas_Rx" SG_ 1446 RGTM_AutoSarNMControl 1;
BA_ "U_C519_MY18_5_Gas_Rx" SG_ 1446 RGTM_AutoSarNMControl 1;
BA_ "U_C519_MY18_5_Diesel_Rx" SG_ 1446 RGTM_AutoSarNMControl 1;
BA_ "ContentDependant" SG_ 1446 RGTM_AutoSarNMControl 1;
BA_ "U_CX482_CX483_MY20_Tx" SG_ 839 FohStop_B_Stat 1;
BA_ "U_C519_MY18_5_Gas_Tx" SG_ 839 FohStop_B_Stat 1;
BA_ "U_C519_MY18_5_Diesel_Tx" SG_ 839 FohStop_B_Stat 1;
BA_ "GenSigStartValue" SG_ 839 FohStop_B_Stat 3;
BA_ "ContentDependant" SG_ 839 FohStop_B_Stat 1;
BA_ "GenSigStartValueInteger" SG_ 839 FohStop_B_Stat 3;
BA_ "CrossOver_InfoCAN" SG_ 839 FohStop_B_Stat 1;
BA_ "WakeupSignal" SG_ 839 FohStop_B_Stat 1;
BA_ "U_CX482_CX483_MY20_Tx" SG_ 839 FohMsgTxt_D_Rq 1;
BA_ "U_C519_MY18_5_Gas_Tx" SG_ 839 FohMsgTxt_D_Rq 1;
BA_ "U_C519_MY18_5_Diesel_Tx" SG_ 839 FohMsgTxt_D_Rq 1;
BA_ "ContentDependant" SG_ 839 FohMsgTxt_D_Rq 1;
BA_ "CrossOver_InfoCAN" SG_ 839 FohMsgTxt_D_Rq 1;
BA_ "U_CX482_CX483_MY20_Tx" SG_ 839 FohKeyOff_B_Rq 1;
BA_ "U_C519_MY18_5_Gas_Tx" SG_ 839 FohKeyOff_B_Rq 1;
BA_ "U_C519_MY18_5_Diesel_Tx" SG_ 839 FohKeyOff_B_Rq 1;
BA_ "U_B479_MY17_Gas_Rx" SG_ 839 FohKeyOff_B_Rq 1;
BA_ "ContentDependant" SG_ 839 FohKeyOff_B_Rq 1;
BA_ "CrossOver_InfoCAN" SG_ 839 FohKeyOff_B_Rq 1;
BA_ "WakeupSignal" SG_ 839 FohKeyOff_B_Rq 1;
BA_ "U_CX482_CX483_MY20_Tx" SG_ 839 FohEnbl_B_Rq 1;
BA_ "U_C519_MY18_5_Gas_Tx" SG_ 839 FohEnbl_B_Rq 1;
BA_ "U_C519_MY18_5_Diesel_Tx" SG_ 839 FohEnbl_B_Rq 1;
BA_ "ContentDependant" SG_ 839 FohEnbl_B_Rq 1;
BA_ "CrossOver_InfoCAN" SG_ 839 FohEnbl_B_Rq 1;
BA_ "WakeupSignal" SG_ 839 FohEnbl_B_Rq 1;
BA_ "U_CX482_CX483_MY20_Tx" SG_ 839 FohTAllEnable_B_Stat 1;
BA_ "U_C519_MY18_5_Gas_Tx" SG_ 839 FohTAllEnable_B_Stat 1;
BA_ "U_C519_MY18_5_Diesel_Tx" SG_ 839 FohTAllEnable_B_Stat 1;
BA_ "GenSigStartValue" SG_ 839 FohTAllEnable_B_Stat 3;
BA_ "ContentDependant" SG_ 839 FohTAllEnable_B_Stat 1;
BA_ "GenSigStartValueInteger" SG_ 839 FohTAllEnable_B_Stat 3;
BA_ "CrossOver_InfoCAN" SG_ 839 FohTAllEnable_B_Stat 1;
BA_ "U_CX482_CX483_MY20_Tx" SG_ 839 FohT2Mnte_T_Stat 1;
BA_ "U_C519_MY18_5_Gas_Tx" SG_ 839 FohT2Mnte_T_Stat 1;
BA_ "U_C519_MY18_5_Diesel_Tx" SG_ 839 FohT2Mnte_T_Stat 1;
BA_ "ContentDependant" SG_ 839 FohT2Mnte_T_Stat 1;
BA_ "CrossOver_InfoCAN" SG_ 839 FohT2Mnte_T_Stat 1;
BA_ "U_CX482_CX483_MY20_Tx" SG_ 839 FohT2Hr_T_Stat 1;
BA_ "U_C519_MY18_5_Gas_Tx" SG_ 839 FohT2Hr_T_Stat 1;
BA_ "U_C519_MY18_5_Diesel_Tx" SG_ 839 FohT2Hr_T_Stat 1;
BA_ "ContentDependant" SG_ 839 FohT2Hr_T_Stat 1;
BA_ "CrossOver_InfoCAN" SG_ 839 FohT2Hr_T_Stat 1;
BA_ "U_CX482_CX483_MY20_Tx" SG_ 839 FohT2Enable_B_Stat 1;
BA_ "U_C519_MY18_5_Gas_Tx" SG_ 839 FohT2Enable_B_Stat 1;
BA_ "U_C519_MY18_5_Diesel_Tx" SG_ 839 FohT2Enable_B_Stat 1;
BA_ "ContentDependant" SG_ 839 FohT2Enable_B_Stat 1;
BA_ "CrossOver_InfoCAN" SG_ 839 FohT2Enable_B_Stat 1;
BA_ "U_CX482_CX483_MY20_Tx" SG_ 839 FohT1Mnte_T_Stat 1;
BA_ "U_C519_MY18_5_Gas_Tx" SG_ 839 FohT1Mnte_T_Stat 1;
BA_ "U_C519_MY18_5_Diesel_Tx" SG_ 839 FohT1Mnte_T_Stat 1;
BA_ "ContentDependant" SG_ 839 FohT1Mnte_T_Stat 1;
BA_ "CrossOver_InfoCAN" SG_ 839 FohT1Mnte_T_Stat 1;
BA_ "U_CX482_CX483_MY20_Tx" SG_ 839 FohT1Hr_T_Stat 1;
BA_ "U_C519_MY18_5_Gas_Tx" SG_ 839 FohT1Hr_T_Stat 1;
BA_ "U_C519_MY18_5_Diesel_Tx" SG_ 839 FohT1Hr_T_Stat 1;
BA_ "ContentDependant" SG_ 839 FohT1Hr_T_Stat 1;
BA_ "CrossOver_InfoCAN" SG_ 839 FohT1Hr_T_Stat 1;
BA_ "U_CX482_CX483_MY20_Tx" SG_ 839 FohT1Enable_B_Stat 1;
BA_ "U_C519_MY18_5_Gas_Tx" SG_ 839 FohT1Enable_B_Stat 1;
BA_ "U_C519_MY18_5_Diesel_Tx" SG_ 839 FohT1Enable_B_Stat 1;
BA_ "ContentDependant" SG_ 839 FohT1Enable_B_Stat 1;
BA_ "CrossOver_InfoCAN" SG_ 839 FohT1Enable_B_Stat 1;
BA_ "U_CX482_CX483_MY20_Tx" SG_ 839 FohStrtMnte_T_Stat 1;
BA_ "U_C519_MY18_5_Gas_Tx" SG_ 839 FohStrtMnte_T_Stat 1;
BA_ "U_C519_MY18_5_Diesel_Tx" SG_ 839 FohStrtMnte_T_Stat 1;
BA_ "ContentDependant" SG_ 839 FohStrtMnte_T_Stat 1;
BA_ "CrossOver_InfoCAN" SG_ 839 FohStrtMnte_T_Stat 1;
BA_ "U_CX482_CX483_MY20_Tx" SG_ 839 FohStrtHr_T_Stat 1;
BA_ "U_C519_MY18_5_Gas_Tx" SG_ 839 FohStrtHr_T_Stat 1;
BA_ "U_C519_MY18_5_Diesel_Tx" SG_ 839 FohStrtHr_T_Stat 1;
BA_ "ContentDependant" SG_ 839 FohStrtHr_T_Stat 1;
BA_ "CrossOver_InfoCAN" SG_ 839 FohStrtHr_T_Stat 1;
BA_ "U_CX482_CX483_MY20_Tx" SG_ 839 FohStrtEnable_B_Stat 1;
BA_ "U_C519_MY18_5_Gas_Tx" SG_ 839 FohStrtEnable_B_Stat 1;
BA_ "U_C519_MY18_5_Diesel_Tx" SG_ 839 FohStrtEnable_B_Stat 1;
BA_ "ContentDependant" SG_ 839 FohStrtEnable_B_Stat 1;
BA_ "CrossOver_InfoCAN" SG_ 839 FohStrtEnable_B_Stat 1;
BA_ "U_CX482_CX483_MY20_Tx" SG_ 839 FohContOn_B_Stat 1;
BA_ "U_C519_MY18_5_Gas_Tx" SG_ 839 FohContOn_B_Stat 1;
BA_ "U_C519_MY18_5_Diesel_Tx" SG_ 839 FohContOn_B_Stat 1;
BA_ "GenSigStartValue" SG_ 839 FohContOn_B_Stat 3;
BA_ "ContentDependant" SG_ 839 FohContOn_B_Stat 1;
BA_ "GenSigStartValueInteger" SG_ 839 FohContOn_B_Stat 3;
BA_ "CrossOver_InfoCAN" SG_ 839 FohContOn_B_Stat 1;
BA_ "U_CX482_CX483_MY20_Tx" SG_ 839 FohStrtDay_T_Stat 1;
BA_ "U_C519_MY18_5_Gas_Tx" SG_ 839 FohStrtDay_T_Stat 1;
BA_ "U_C519_MY18_5_Diesel_Tx" SG_ 839 FohStrtDay_T_Stat 1;
BA_ "ContentDependant" SG_ 839 FohStrtDay_T_Stat 1;
BA_ "CrossOver_InfoCAN" SG_ 839 FohStrtDay_T_Stat 1;
BA_ "U_CX482_CX483_MY20_Tx" SG_ 839 FohT2Wednesday_T_Stat 1;
BA_ "U_C519_MY18_5_Gas_Tx" SG_ 839 FohT2Wednesday_T_Stat 1;
BA_ "U_C519_MY18_5_Diesel_Tx" SG_ 839 FohT2Wednesday_T_Stat 1;
BA_ "ContentDependant" SG_ 839 FohT2Wednesday_T_Stat 1;
BA_ "CrossOver_InfoCAN" SG_ 839 FohT2Wednesday_T_Stat 1;
BA_ "U_CX482_CX483_MY20_Tx" SG_ 839 FohT2Tuesday_T_Stat 1;
BA_ "U_C519_MY18_5_Gas_Tx" SG_ 839 FohT2Tuesday_T_Stat 1;
BA_ "U_C519_MY18_5_Diesel_Tx" SG_ 839 FohT2Tuesday_T_Stat 1;
BA_ "ContentDependant" SG_ 839 FohT2Tuesday_T_Stat 1;
BA_ "CrossOver_InfoCAN" SG_ 839 FohT2Tuesday_T_Stat 1;
BA_ "U_CX482_CX483_MY20_Tx" SG_ 839 FohT2Thursday_T_Stat 1;
BA_ "U_C519_MY18_5_Gas_Tx" SG_ 839 FohT2Thursday_T_Stat 1;
BA_ "U_C519_MY18_5_Diesel_Tx" SG_ 839 FohT2Thursday_T_Stat 1;
BA_ "ContentDependant" SG_ 839 FohT2Thursday_T_Stat 1;
BA_ "CrossOver_InfoCAN" SG_ 839 FohT2Thursday_T_Stat 1;
BA_ "U_CX482_CX483_MY20_Tx" SG_ 839 FohT2Sunday_T_Stat 1;
BA_ "U_C519_MY18_5_Gas_Tx" SG_ 839 FohT2Sunday_T_Stat 1;
BA_ "U_C519_MY18_5_Diesel_Tx" SG_ 839 FohT2Sunday_T_Stat 1;
BA_ "ContentDependant" SG_ 839 FohT2Sunday_T_Stat 1;
BA_ "CrossOver_InfoCAN" SG_ 839 FohT2Sunday_T_Stat 1;
BA_ "U_CX482_CX483_MY20_Tx" SG_ 839 FohT2Saturday_T_Stat 1;
BA_ "U_C519_MY18_5_Gas_Tx" SG_ 839 FohT2Saturday_T_Stat 1;
BA_ "U_C519_MY18_5_Diesel_Tx" SG_ 839 FohT2Saturday_T_Stat 1;
BA_ "ContentDependant" SG_ 839 FohT2Saturday_T_Stat 1;
BA_ "CrossOver_InfoCAN" SG_ 839 FohT2Saturday_T_Stat 1;
BA_ "U_CX482_CX483_MY20_Tx" SG_ 839 FohT2Monday_T_Stat 1;
BA_ "U_C519_MY18_5_Gas_Tx" SG_ 839 FohT2Monday_T_Stat 1;
BA_ "U_C519_MY18_5_Diesel_Tx" SG_ 839 FohT2Monday_T_Stat 1;
BA_ "ContentDependant" SG_ 839 FohT2Monday_T_Stat 1;
BA_ "CrossOver_InfoCAN" SG_ 839 FohT2Monday_T_Stat 1;
BA_ "U_CX482_CX483_MY20_Tx" SG_ 839 FohT2Friday_T_Stat 1;
BA_ "U_C519_MY18_5_Gas_Tx" SG_ 839 FohT2Friday_T_Stat 1;
BA_ "U_C519_MY18_5_Diesel_Tx" SG_ 839 FohT2Friday_T_Stat 1;
BA_ "ContentDependant" SG_ 839 FohT2Friday_T_Stat 1;
BA_ "CrossOver_InfoCAN" SG_ 839 FohT2Friday_T_Stat 1;
BA_ "U_CX482_CX483_MY20_Tx" SG_ 839 FohT1Wednesday_T_Stat 1;
BA_ "U_C519_MY18_5_Gas_Tx" SG_ 839 FohT1Wednesday_T_Stat 1;
BA_ "U_C519_MY18_5_Diesel_Tx" SG_ 839 FohT1Wednesday_T_Stat 1;
BA_ "ContentDependant" SG_ 839 FohT1Wednesday_T_Stat 1;
BA_ "CrossOver_InfoCAN" SG_ 839 FohT1Wednesday_T_Stat 1;
BA_ "U_CX482_CX483_MY20_Tx" SG_ 839 FohT1Tuesday_T_Stat 1;
BA_ "U_C519_MY18_5_Gas_Tx" SG_ 839 FohT1Tuesday_T_Stat 1;
BA_ "U_C519_MY18_5_Diesel_Tx" SG_ 839 FohT1Tuesday_T_Stat 1;
BA_ "ContentDependant" SG_ 839 FohT1Tuesday_T_Stat 1;
BA_ "CrossOver_InfoCAN" SG_ 839 FohT1Tuesday_T_Stat 1;
BA_ "U_CX482_CX483_MY20_Tx" SG_ 839 FohT1Thursday_T_Stat 1;
BA_ "U_C519_MY18_5_Gas_Tx" SG_ 839 FohT1Thursday_T_Stat 1;
BA_ "U_C519_MY18_5_Diesel_Tx" SG_ 839 FohT1Thursday_T_Stat 1;
BA_ "ContentDependant" SG_ 839 FohT1Thursday_T_Stat 1;
BA_ "CrossOver_InfoCAN" SG_ 839 FohT1Thursday_T_Stat 1;
BA_ "U_CX482_CX483_MY20_Tx" SG_ 839 FohT1Sunday_T_Stat 1;
BA_ "U_C519_MY18_5_Gas_Tx" SG_ 839 FohT1Sunday_T_Stat 1;
BA_ "U_C519_MY18_5_Diesel_Tx" SG_ 839 FohT1Sunday_T_Stat 1;
BA_ "ContentDependant" SG_ 839 FohT1Sunday_T_Stat 1;
BA_ "CrossOver_InfoCAN" SG_ 839 FohT1Sunday_T_Stat 1;
BA_ "U_CX482_CX483_MY20_Tx" SG_ 839 FohT1Saturday_T_Stat 1;
BA_ "U_C519_MY18_5_Gas_Tx" SG_ 839 FohT1Saturday_T_Stat 1;
BA_ "U_C519_MY18_5_Diesel_Tx" SG_ 839 FohT1Saturday_T_Stat 1;
BA_ "ContentDependant" SG_ 839 FohT1Saturday_T_Stat 1;
BA_ "CrossOver_InfoCAN" SG_ 839 FohT1Saturday_T_Stat 1;
BA_ "U_CX482_CX483_MY20_Tx" SG_ 839 FohT1Monday_T_Stat 1;
BA_ "U_C519_MY18_5_Gas_Tx" SG_ 839 FohT1Monday_T_Stat 1;
BA_ "U_C519_MY18_5_Diesel_Tx" SG_ 839 FohT1Monday_T_Stat 1;
BA_ "ContentDependant" SG_ 839 FohT1Monday_T_Stat 1;
BA_ "CrossOver_InfoCAN" SG_ 839 FohT1Monday_T_Stat 1;
BA_ "U_CX482_CX483_MY20_Tx" SG_ 839 FohT1Friday_T_Stat 1;
BA_ "U_C519_MY18_5_Gas_Tx" SG_ 839 FohT1Friday_T_Stat 1;
BA_ "U_C519_MY18_5_Diesel_Tx" SG_ 839 FohT1Friday_T_Stat 1;
BA_ "ContentDependant" SG_ 839 FohT1Friday_T_Stat 1;
BA_ "CrossOver_InfoCAN" SG_ 839 FohT1Friday_T_Stat 1;
BA_ "U_P702_MY2021_Tx" SG_ 850 SeatCshnPsgrRR_Pc_Actl 1;
BA_ "U_U611_U625_MY20_Phev_Tx" SG_ 850 SeatCshnPsgrRR_Pc_Actl 1;
BA_ "U_CX482_CX483_MY20_Tx" SG_ 850 SeatCshnPsgrRR_Pc_Actl 1;
BA_ "U_U611_U625_MY20_Hev_Tx" SG_ 850 SeatCshnPsgrRR_Pc_Actl 1;
BA_ "U_U611_U625_MY20_Gas_Tx" SG_ 850 SeatCshnPsgrRR_Pc_Actl 1;
BA_ "GenSigStartValue" SG_ 850 SeatCshnPsgrRR_Pc_Actl 127;
BA_ "GenSigStartValueInteger" SG_ 850 SeatCshnPsgrRR_Pc_Actl 127;
BA_ "CrossOver_InfoCAN" SG_ 850 SeatCshnPsgrRR_Pc_Actl 1;
BA_ "U_P702_MY2021_Tx" SG_ 850 SeatCshnPsgrRL_Pc_Actl 1;
BA_ "U_U611_U625_MY20_Phev_Tx" SG_ 850 SeatCshnPsgrRL_Pc_Actl 1;
BA_ "U_CX482_CX483_MY20_Tx" SG_ 850 SeatCshnPsgrRL_Pc_Actl 1;
BA_ "U_U611_U625_MY20_Hev_Tx" SG_ 850 SeatCshnPsgrRL_Pc_Actl 1;
BA_ "U_U611_U625_MY20_Gas_Tx" SG_ 850 SeatCshnPsgrRL_Pc_Actl 1;
BA_ "GenSigStartValue" SG_ 850 SeatCshnPsgrRL_Pc_Actl 127;
BA_ "GenSigStartValueInteger" SG_ 850 SeatCshnPsgrRL_Pc_Actl 127;
BA_ "CrossOver_InfoCAN" SG_ 850 SeatCshnPsgrRL_Pc_Actl 1;
BA_ "U_P702_MY2021_Tx" SG_ 850 SeatCshnPsgrFR_Pc_Actl 1;
BA_ "U_U611_U625_MY20_Phev_Tx" SG_ 850 SeatCshnPsgrFR_Pc_Actl 1;
BA_ "U_CX482_CX483_MY20_Tx" SG_ 850 SeatCshnPsgrFR_Pc_Actl 1;
BA_ "U_U611_U625_MY20_Hev_Tx" SG_ 850 SeatCshnPsgrFR_Pc_Actl 1;
BA_ "U_U611_U625_MY20_Gas_Tx" SG_ 850 SeatCshnPsgrFR_Pc_Actl 1;
BA_ "GenSigStartValue" SG_ 850 SeatCshnPsgrFR_Pc_Actl 127;
BA_ "GenSigStartValueInteger" SG_ 850 SeatCshnPsgrFR_Pc_Actl 127;
BA_ "CrossOver_InfoCAN" SG_ 850 SeatCshnPsgrFR_Pc_Actl 1;
BA_ "U_P702_MY2021_Tx" SG_ 850 SeatCshnPsgrFL_Pc_Actl 1;
BA_ "U_U611_U625_MY20_Phev_Tx" SG_ 850 SeatCshnPsgrFL_Pc_Actl 1;
BA_ "U_CX482_CX483_MY20_Tx" SG_ 850 SeatCshnPsgrFL_Pc_Actl 1;
BA_ "U_U611_U625_MY20_Hev_Tx" SG_ 850 SeatCshnPsgrFL_Pc_Actl 1;
BA_ "U_U611_U625_MY20_Gas_Tx" SG_ 850 SeatCshnPsgrFL_Pc_Actl 1;
BA_ "GenSigStartValue" SG_ 850 SeatCshnPsgrFL_Pc_Actl 127;
BA_ "GenSigStartValueInteger" SG_ 850 SeatCshnPsgrFL_Pc_Actl 127;
BA_ "CrossOver_InfoCAN" SG_ 850 SeatCshnPsgrFL_Pc_Actl 1;
BA_ "U_P702_MY2021_Tx" SG_ 850 SeatBlLoPsgr_Pc_Actl2 1;
BA_ "U_U611_U625_MY20_Phev_Tx" SG_ 850 SeatBlLoPsgr_Pc_Actl2 1;
BA_ "U_CX482_CX483_MY20_Tx" SG_ 850 SeatBlLoPsgr_Pc_Actl2 1;
BA_ "U_U611_U625_MY20_Hev_Tx" SG_ 850 SeatBlLoPsgr_Pc_Actl2 1;
BA_ "U_U611_U625_MY20_Gas_Tx" SG_ 850 SeatBlLoPsgr_Pc_Actl2 1;
BA_ "GenSigStartValue" SG_ 850 SeatBlLoPsgr_Pc_Actl2 127;
BA_ "GenSigStartValueInteger" SG_ 850 SeatBlLoPsgr_Pc_Actl2 127;
BA_ "CrossOver_InfoCAN" SG_ 850 SeatBlLoPsgr_Pc_Actl2 1;
BA_ "U_P702_MY2021_Tx" SG_ 849 SeatCshnDrvRR_Pc_Actl 1;
BA_ "U_U611_U625_MY20_Phev_Tx" SG_ 849 SeatCshnDrvRR_Pc_Actl 1;
BA_ "U_CX482_CX483_MY20_Tx" SG_ 849 SeatCshnDrvRR_Pc_Actl 1;
BA_ "U_U611_U625_MY20_Hev_Tx" SG_ 849 SeatCshnDrvRR_Pc_Actl 1;
BA_ "U_U611_U625_MY20_Gas_Tx" SG_ 849 SeatCshnDrvRR_Pc_Actl 1;
BA_ "GenSigStartValue" SG_ 849 SeatCshnDrvRR_Pc_Actl 127;
BA_ "GenSigStartValueInteger" SG_ 849 SeatCshnDrvRR_Pc_Actl 127;
BA_ "CrossOver_InfoCAN" SG_ 849 SeatCshnDrvRR_Pc_Actl 1;
BA_ "U_P702_MY2021_Tx" SG_ 849 SeatCshnDrvRL_Pc_Actl 1;
BA_ "U_U611_U625_MY20_Phev_Tx" SG_ 849 SeatCshnDrvRL_Pc_Actl 1;
BA_ "U_CX482_CX483_MY20_Tx" SG_ 849 SeatCshnDrvRL_Pc_Actl 1;
BA_ "U_U611_U625_MY20_Hev_Tx" SG_ 849 SeatCshnDrvRL_Pc_Actl 1;
BA_ "U_U611_U625_MY20_Gas_Tx" SG_ 849 SeatCshnDrvRL_Pc_Actl 1;
BA_ "GenSigStartValue" SG_ 849 SeatCshnDrvRL_Pc_Actl 127;
BA_ "GenSigStartValueInteger" SG_ 849 SeatCshnDrvRL_Pc_Actl 127;
BA_ "CrossOver_InfoCAN" SG_ 849 SeatCshnDrvRL_Pc_Actl 1;
BA_ "U_P702_MY2021_Tx" SG_ 849 SeatCshnDrvFR_Pc_Actl 1;
BA_ "U_U611_U625_MY20_Phev_Tx" SG_ 849 SeatCshnDrvFR_Pc_Actl 1;
BA_ "U_CX482_CX483_MY20_Tx" SG_ 849 SeatCshnDrvFR_Pc_Actl 1;
BA_ "U_U611_U625_MY20_Hev_Tx" SG_ 849 SeatCshnDrvFR_Pc_Actl 1;
BA_ "U_U611_U625_MY20_Gas_Tx" SG_ 849 SeatCshnDrvFR_Pc_Actl 1;
BA_ "GenSigStartValue" SG_ 849 SeatCshnDrvFR_Pc_Actl 127;
BA_ "GenSigStartValueInteger" SG_ 849 SeatCshnDrvFR_Pc_Actl 127;
BA_ "CrossOver_InfoCAN" SG_ 849 SeatCshnDrvFR_Pc_Actl 1;
BA_ "U_P702_MY2021_Tx" SG_ 849 SeatCshnDrvFL_Pc_Actl 1;
BA_ "U_U611_U625_MY20_Phev_Tx" SG_ 849 SeatCshnDrvFL_Pc_Actl 1;
BA_ "U_CX482_CX483_MY20_Tx" SG_ 849 SeatCshnDrvFL_Pc_Actl 1;
BA_ "U_U611_U625_MY20_Hev_Tx" SG_ 849 SeatCshnDrvFL_Pc_Actl 1;
BA_ "U_U611_U625_MY20_Gas_Tx" SG_ 849 SeatCshnDrvFL_Pc_Actl 1;
BA_ "GenSigStartValue" SG_ 849 SeatCshnDrvFL_Pc_Actl 127;
BA_ "GenSigStartValueInteger" SG_ 849 SeatCshnDrvFL_Pc_Actl 127;
BA_ "CrossOver_InfoCAN" SG_ 849 SeatCshnDrvFL_Pc_Actl 1;
BA_ "U_P702_MY2021_Rx" SG_ 846 SeatLmbr_D_Rq 1;
BA_ "U_U611_U625_MY20_Phev_Rx" SG_ 846 SeatLmbr_D_Rq 1;
BA_ "U_CX482_CX483_MY20_Rx" SG_ 846 SeatLmbr_D_Rq 1;
BA_ "U_U611_U625_MY20_Hev_Rx" SG_ 846 SeatLmbr_D_Rq 1;
BA_ "U_U611_U625_MY20_Gas_Rx" SG_ 846 SeatLmbr_D_Rq 1;
BA_ "U_P702_MY2021_Rx" SG_ 846 SeatFnChngPsgr2_D_Rq 1;
BA_ "U_U611_U625_MY20_Phev_Rx" SG_ 846 SeatFnChngPsgr2_D_Rq 1;
BA_ "U_CX482_CX483_MY20_Rx" SG_ 846 SeatFnChngPsgr2_D_Rq 1;
BA_ "U_U611_U625_MY20_Hev_Rx" SG_ 846 SeatFnChngPsgr2_D_Rq 1;
BA_ "U_U611_U625_MY20_Gas_Rx" SG_ 846 SeatFnChngPsgr2_D_Rq 1;
BA_ "U_P702_MY2021_Rx" SG_ 846 SeatFnChngDrv2_D_Rq 1;
BA_ "U_U611_U625_MY20_Phev_Rx" SG_ 846 SeatFnChngDrv2_D_Rq 1;
BA_ "U_CX482_CX483_MY20_Rx" SG_ 846 SeatFnChngDrv2_D_Rq 1;
BA_ "U_U611_U625_MY20_Hev_Rx" SG_ 846 SeatFnChngDrv2_D_Rq 1;
BA_ "U_U611_U625_MY20_Gas_Rx" SG_ 846 SeatFnChngDrv2_D_Rq 1;
BA_ "U_P702_MY2021_Tx" SG_ 845 StmsLmbrPsgr_D_Stat 1;
BA_ "U_U611_U625_MY20_Phev_Tx" SG_ 845 StmsLmbrPsgr_D_Stat 1;
BA_ "U_CX482_CX483_MY20_Tx" SG_ 845 StmsLmbrPsgr_D_Stat 1;
BA_ "U_U611_U625_MY20_Hev_Tx" SG_ 845 StmsLmbrPsgr_D_Stat 1;
BA_ "U_U611_U625_MY20_Gas_Tx" SG_ 845 StmsLmbrPsgr_D_Stat 1;
BA_ "GenSigSendType" SG_ 845 StmsLmbrPsgr_D_Stat 3;
BA_ "CrossOver_InfoCAN" SG_ 845 StmsLmbrPsgr_D_Stat 1;
BA_ "U_P702_MY2021_Tx" SG_ 845 StmsCshnPsgr_D_Stat 1;
BA_ "U_U611_U625_MY20_Phev_Tx" SG_ 845 StmsCshnPsgr_D_Stat 1;
BA_ "U_CX482_CX483_MY20_Tx" SG_ 845 StmsCshnPsgr_D_Stat 1;
BA_ "U_U611_U625_MY20_Hev_Tx" SG_ 845 StmsCshnPsgr_D_Stat 1;
BA_ "U_U611_U625_MY20_Gas_Tx" SG_ 845 StmsCshnPsgr_D_Stat 1;
BA_ "GenSigSendType" SG_ 845 StmsCshnPsgr_D_Stat 3;
BA_ "CrossOver_InfoCAN" SG_ 845 StmsCshnPsgr_D_Stat 1;
BA_ "U_P702_MY2021_Tx" SG_ 845 SeatSwtchPsgr_B_Stat 1;
BA_ "U_U611_U625_MY20_Phev_Tx" SG_ 845 SeatSwtchPsgr_B_Stat 1;
BA_ "U_CX482_CX483_MY20_Tx" SG_ 845 SeatSwtchPsgr_B_Stat 1;
BA_ "U_U611_U625_MY20_Hev_Tx" SG_ 845 SeatSwtchPsgr_B_Stat 1;
BA_ "U_U611_U625_MY20_Gas_Tx" SG_ 845 SeatSwtchPsgr_B_Stat 1;
BA_ "GenSigSendType" SG_ 845 SeatSwtchPsgr_B_Stat 3;
BA_ "CrossOver_InfoCAN" SG_ 845 SeatSwtchPsgr_B_Stat 1;
BA_ "U_P702_MY2021_Tx" SG_ 845 SeatPPsgr_B_Stat 1;
BA_ "U_U611_U625_MY20_Phev_Tx" SG_ 845 SeatPPsgr_B_Stat 1;
BA_ "U_CX482_CX483_MY20_Tx" SG_ 845 SeatPPsgr_B_Stat 1;
BA_ "U_U611_U625_MY20_Hev_Tx" SG_ 845 SeatPPsgr_B_Stat 1;
BA_ "U_U611_U625_MY20_Gas_Tx" SG_ 845 SeatPPsgr_B_Stat 1;
BA_ "GenSigSendType" SG_ 845 SeatPPsgr_B_Stat 3;
BA_ "CrossOver_InfoCAN" SG_ 845 SeatPPsgr_B_Stat 1;
BA_ "U_P702_MY2021_Tx" SG_ 845 SeatFnPsgr_D_Stat 1;
BA_ "U_U611_U625_MY20_Phev_Tx" SG_ 845 SeatFnPsgr_D_Stat 1;
BA_ "U_CX482_CX483_MY20_Tx" SG_ 845 SeatFnPsgr_D_Stat 1;
BA_ "U_U611_U625_MY20_Hev_Tx" SG_ 845 SeatFnPsgr_D_Stat 1;
BA_ "U_U611_U625_MY20_Gas_Tx" SG_ 845 SeatFnPsgr_D_Stat 1;
BA_ "GenSigSendType" SG_ 845 SeatFnPsgr_D_Stat 3;
BA_ "CrossOver_InfoCAN" SG_ 845 SeatFnPsgr_D_Stat 1;
BA_ "U_P702_MY2021_Tx" SG_ 845 PsgrMemFeedback_Rsp 1;
BA_ "U_U611_U625_MY20_Phev_Tx" SG_ 845 PsgrMemFeedback_Rsp 1;
BA_ "U_CX482_CX483_MY20_Tx" SG_ 845 PsgrMemFeedback_Rsp 1;
BA_ "U_U611_U625_MY20_Hev_Tx" SG_ 845 PsgrMemFeedback_Rsp 1;
BA_ "U_U611_U625_MY20_Gas_Tx" SG_ 845 PsgrMemFeedback_Rsp 1;
BA_ "GenSigSendType" SG_ 845 PsgrMemFeedback_Rsp 3;
BA_ "CrossOver_InfoCAN" SG_ 845 PsgrMemFeedback_Rsp 1;
BA_ "U_P702_MY2021_Tx" SG_ 844 StmsLmbrDrv_D_Stat 1;
BA_ "U_U611_U625_MY20_Phev_Tx" SG_ 844 StmsLmbrDrv_D_Stat 1;
BA_ "U_CX482_CX483_MY20_Tx" SG_ 844 StmsLmbrDrv_D_Stat 1;
BA_ "U_U611_U625_MY20_Hev_Tx" SG_ 844 StmsLmbrDrv_D_Stat 1;
BA_ "U_U611_U625_MY20_Gas_Tx" SG_ 844 StmsLmbrDrv_D_Stat 1;
BA_ "GenSigSendType" SG_ 844 StmsLmbrDrv_D_Stat 3;
BA_ "CrossOver_InfoCAN" SG_ 844 StmsLmbrDrv_D_Stat 1;
BA_ "U_P702_MY2021_Tx" SG_ 844 StmsCshnDrv_D_Stat 1;
BA_ "U_U611_U625_MY20_Phev_Tx" SG_ 844 StmsCshnDrv_D_Stat 1;
BA_ "U_CX482_CX483_MY20_Tx" SG_ 844 StmsCshnDrv_D_Stat 1;
BA_ "U_U611_U625_MY20_Hev_Tx" SG_ 844 StmsCshnDrv_D_Stat 1;
BA_ "U_U611_U625_MY20_Gas_Tx" SG_ 844 StmsCshnDrv_D_Stat 1;
BA_ "GenSigSendType" SG_ 844 StmsCshnDrv_D_Stat 3;
BA_ "CrossOver_InfoCAN" SG_ 844 StmsCshnDrv_D_Stat 1;
BA_ "U_P702_MY2021_Tx" SG_ 844 SeatSwtchDrv_B_Stat 1;
BA_ "U_U611_U625_MY20_Phev_Tx" SG_ 844 SeatSwtchDrv_B_Stat 1;
BA_ "U_CX482_CX483_MY20_Tx" SG_ 844 SeatSwtchDrv_B_Stat 1;
BA_ "U_U611_U625_MY20_Hev_Tx" SG_ 844 SeatSwtchDrv_B_Stat 1;
BA_ "U_U611_U625_MY20_Gas_Tx" SG_ 844 SeatSwtchDrv_B_Stat 1;
BA_ "GenSigSendType" SG_ 844 SeatSwtchDrv_B_Stat 3;
BA_ "CrossOver_InfoCAN" SG_ 844 SeatSwtchDrv_B_Stat 1;
BA_ "U_P702_MY2021_Tx" SG_ 844 SeatFnDrv_D_Stat 1;
BA_ "U_U611_U625_MY20_Phev_Tx" SG_ 844 SeatFnDrv_D_Stat 1;
BA_ "U_CX482_CX483_MY20_Tx" SG_ 844 SeatFnDrv_D_Stat 1;
BA_ "U_U611_U625_MY20_Hev_Tx" SG_ 844 SeatFnDrv_D_Stat 1;
BA_ "U_U611_U625_MY20_Gas_Tx" SG_ 844 SeatFnDrv_D_Stat 1;
BA_ "GenSigSendType" SG_ 844 SeatFnDrv_D_Stat 3;
BA_ "CrossOver_InfoCAN" SG_ 844 SeatFnDrv_D_Stat 1;
BA_ "U_P702_MY2021_Tx" SG_ 844 SeatAirAmb_P_Actl 1;
BA_ "U_U611_U625_MY20_Phev_Tx" SG_ 844 SeatAirAmb_P_Actl 1;
BA_ "U_CX482_CX483_MY20_Tx" SG_ 844 SeatAirAmb_P_Actl 1;
BA_ "U_U611_U625_MY20_Hev_Tx" SG_ 844 SeatAirAmb_P_Actl 1;
BA_ "U_U611_U625_MY20_Gas_Tx" SG_ 844 SeatAirAmb_P_Actl 1;
BA_ "U_P702_MY2021_Rx" SG_ 844 SeatAirAmb_P_Actl 1;
BA_ "U_U611_U625_MY20_Phev_Rx" SG_ 844 SeatAirAmb_P_Actl 1;
BA_ "U_CX482_CX483_MY20_Rx" SG_ 844 SeatAirAmb_P_Actl 1;
BA_ "U_U611_U625_MY20_Hev_Rx" SG_ 844 SeatAirAmb_P_Actl 1;
BA_ "U_U611_U625_MY20_Gas_Rx" SG_ 844 SeatAirAmb_P_Actl 1;
BA_ "CrossOver_InfoCAN" SG_ 844 SeatAirAmb_P_Actl 1;
BA_ "U_P702_MY2021_Tx" SG_ 844 SeatPDrv_B_Stat 1;
BA_ "U_U611_U625_MY20_Phev_Tx" SG_ 844 SeatPDrv_B_Stat 1;
BA_ "U_CX482_CX483_MY20_Tx" SG_ 844 SeatPDrv_B_Stat 1;
BA_ "U_U611_U625_MY20_Hev_Tx" SG_ 844 SeatPDrv_B_Stat 1;
BA_ "U_U611_U625_MY20_Gas_Tx" SG_ 844 SeatPDrv_B_Stat 1;
BA_ "GenSigSendType" SG_ 844 SeatPDrv_B_Stat 3;
BA_ "CrossOver_InfoCAN" SG_ 844 SeatPDrv_B_Stat 1;
BA_ "U_P702_MY2021_Tx" SG_ 843 SeatLmbrUpPsgr_Pc_Actl 1;
BA_ "U_U611_U625_MY20_Phev_Tx" SG_ 843 SeatLmbrUpPsgr_Pc_Actl 1;
BA_ "U_CX482_CX483_MY20_Tx" SG_ 843 SeatLmbrUpPsgr_Pc_Actl 1;
BA_ "U_U611_U625_MY20_Hev_Tx" SG_ 843 SeatLmbrUpPsgr_Pc_Actl 1;
BA_ "U_U611_U625_MY20_Gas_Tx" SG_ 843 SeatLmbrUpPsgr_Pc_Actl 1;
BA_ "GenSigSendType" SG_ 843 SeatLmbrUpPsgr_Pc_Actl 3;
BA_ "GenSigStartValue" SG_ 843 SeatLmbrUpPsgr_Pc_Actl 127;
BA_ "GenSigStartValueInteger" SG_ 843 SeatLmbrUpPsgr_Pc_Actl 127;
BA_ "CrossOver_InfoCAN" SG_ 843 SeatLmbrUpPsgr_Pc_Actl 1;
BA_ "U_P702_MY2021_Tx" SG_ 843 SeatLmbrMidPsgr_Pc_Actl 1;
BA_ "U_U611_U625_MY20_Phev_Tx" SG_ 843 SeatLmbrMidPsgr_Pc_Actl 1;
BA_ "U_CX482_CX483_MY20_Tx" SG_ 843 SeatLmbrMidPsgr_Pc_Actl 1;
BA_ "U_U611_U625_MY20_Hev_Tx" SG_ 843 SeatLmbrMidPsgr_Pc_Actl 1;
BA_ "U_U611_U625_MY20_Gas_Tx" SG_ 843 SeatLmbrMidPsgr_Pc_Actl 1;
BA_ "GenSigSendType" SG_ 843 SeatLmbrMidPsgr_Pc_Actl 3;
BA_ "GenSigStartValue" SG_ 843 SeatLmbrMidPsgr_Pc_Actl 127;
BA_ "GenSigStartValueInteger" SG_ 843 SeatLmbrMidPsgr_Pc_Actl 127;
BA_ "CrossOver_InfoCAN" SG_ 843 SeatLmbrMidPsgr_Pc_Actl 1;
BA_ "U_P702_MY2021_Tx" SG_ 843 SeatLmbrLoPsgr_Pc_Actl 1;
BA_ "U_U611_U625_MY20_Phev_Tx" SG_ 843 SeatLmbrLoPsgr_Pc_Actl 1;
BA_ "U_CX482_CX483_MY20_Tx" SG_ 843 SeatLmbrLoPsgr_Pc_Actl 1;
BA_ "U_U611_U625_MY20_Hev_Tx" SG_ 843 SeatLmbrLoPsgr_Pc_Actl 1;
BA_ "U_U611_U625_MY20_Gas_Tx" SG_ 843 SeatLmbrLoPsgr_Pc_Actl 1;
BA_ "GenSigSendType" SG_ 843 SeatLmbrLoPsgr_Pc_Actl 3;
BA_ "GenSigStartValue" SG_ 843 SeatLmbrLoPsgr_Pc_Actl 127;
BA_ "GenSigStartValueInteger" SG_ 843 SeatLmbrLoPsgr_Pc_Actl 127;
BA_ "CrossOver_InfoCAN" SG_ 843 SeatLmbrLoPsgr_Pc_Actl 1;
BA_ "U_P702_MY2021_Tx" SG_ 843 SeatBlUpPsgr_Pc_Actl 1;
BA_ "U_U611_U625_MY20_Phev_Tx" SG_ 843 SeatBlUpPsgr_Pc_Actl 1;
BA_ "U_CX482_CX483_MY20_Tx" SG_ 843 SeatBlUpPsgr_Pc_Actl 1;
BA_ "U_U611_U625_MY20_Hev_Tx" SG_ 843 SeatBlUpPsgr_Pc_Actl 1;
BA_ "U_U611_U625_MY20_Gas_Tx" SG_ 843 SeatBlUpPsgr_Pc_Actl 1;
BA_ "GenSigSendType" SG_ 843 SeatBlUpPsgr_Pc_Actl 3;
BA_ "GenSigStartValue" SG_ 843 SeatBlUpPsgr_Pc_Actl 127;
BA_ "GenSigStartValueInteger" SG_ 843 SeatBlUpPsgr_Pc_Actl 127;
BA_ "CrossOver_InfoCAN" SG_ 843 SeatBlUpPsgr_Pc_Actl 1;
BA_ "U_P702_MY2021_Tx" SG_ 843 SeatBlLoPsgr_Pc_Actl 1;
BA_ "U_U611_U625_MY20_Phev_Tx" SG_ 843 SeatBlLoPsgr_Pc_Actl 1;
BA_ "U_CX482_CX483_MY20_Tx" SG_ 843 SeatBlLoPsgr_Pc_Actl 1;
BA_ "U_U611_U625_MY20_Hev_Tx" SG_ 843 SeatBlLoPsgr_Pc_Actl 1;
BA_ "U_U611_U625_MY20_Gas_Tx" SG_ 843 SeatBlLoPsgr_Pc_Actl 1;
BA_ "GenSigSendType" SG_ 843 SeatBlLoPsgr_Pc_Actl 3;
BA_ "GenSigStartValue" SG_ 843 SeatBlLoPsgr_Pc_Actl 127;
BA_ "GenSigStartValueInteger" SG_ 843 SeatBlLoPsgr_Pc_Actl 127;
BA_ "CrossOver_InfoCAN" SG_ 843 SeatBlLoPsgr_Pc_Actl 1;
BA_ "U_P702_MY2021_Tx" SG_ 842 SeatLmbrUpDrv_Pc_Actl 1;
BA_ "U_U611_U625_MY20_Phev_Tx" SG_ 842 SeatLmbrUpDrv_Pc_Actl 1;
BA_ "U_CX482_CX483_MY20_Tx" SG_ 842 SeatLmbrUpDrv_Pc_Actl 1;
BA_ "U_U611_U625_MY20_Hev_Tx" SG_ 842 SeatLmbrUpDrv_Pc_Actl 1;
BA_ "U_U611_U625_MY20_Gas_Tx" SG_ 842 SeatLmbrUpDrv_Pc_Actl 1;
BA_ "GenSigSendType" SG_ 842 SeatLmbrUpDrv_Pc_Actl 3;
BA_ "GenSigStartValue" SG_ 842 SeatLmbrUpDrv_Pc_Actl 127;
BA_ "GenSigStartValueInteger" SG_ 842 SeatLmbrUpDrv_Pc_Actl 127;
BA_ "CrossOver_InfoCAN" SG_ 842 SeatLmbrUpDrv_Pc_Actl 1;
BA_ "U_P702_MY2021_Tx" SG_ 842 SeatLmbrMidDrv_Pc_Actl 1;
BA_ "U_U611_U625_MY20_Phev_Tx" SG_ 842 SeatLmbrMidDrv_Pc_Actl 1;
BA_ "U_CX482_CX483_MY20_Tx" SG_ 842 SeatLmbrMidDrv_Pc_Actl 1;
BA_ "U_U611_U625_MY20_Hev_Tx" SG_ 842 SeatLmbrMidDrv_Pc_Actl 1;
BA_ "U_U611_U625_MY20_Gas_Tx" SG_ 842 SeatLmbrMidDrv_Pc_Actl 1;
BA_ "GenSigSendType" SG_ 842 SeatLmbrMidDrv_Pc_Actl 3;
BA_ "GenSigStartValue" SG_ 842 SeatLmbrMidDrv_Pc_Actl 127;
BA_ "GenSigStartValueInteger" SG_ 842 SeatLmbrMidDrv_Pc_Actl 127;
BA_ "CrossOver_InfoCAN" SG_ 842 SeatLmbrMidDrv_Pc_Actl 1;
BA_ "U_P702_MY2021_Tx" SG_ 842 SeatLmbrLoDrv_Pc_Actl 1;
BA_ "U_U611_U625_MY20_Phev_Tx" SG_ 842 SeatLmbrLoDrv_Pc_Actl 1;
BA_ "U_CX482_CX483_MY20_Tx" SG_ 842 SeatLmbrLoDrv_Pc_Actl 1;
BA_ "U_U611_U625_MY20_Hev_Tx" SG_ 842 SeatLmbrLoDrv_Pc_Actl 1;
BA_ "U_U611_U625_MY20_Gas_Tx" SG_ 842 SeatLmbrLoDrv_Pc_Actl 1;
BA_ "GenSigSendType" SG_ 842 SeatLmbrLoDrv_Pc_Actl 3;
BA_ "GenSigStartValue" SG_ 842 SeatLmbrLoDrv_Pc_Actl 127;
BA_ "GenSigStartValueInteger" SG_ 842 SeatLmbrLoDrv_Pc_Actl 127;
BA_ "CrossOver_InfoCAN" SG_ 842 SeatLmbrLoDrv_Pc_Actl 1;
BA_ "U_P702_MY2021_Tx" SG_ 842 SeatBlUpDrv_Pc_Actl 1;
BA_ "U_U611_U625_MY20_Phev_Tx" SG_ 842 SeatBlUpDrv_Pc_Actl 1;
BA_ "U_CX482_CX483_MY20_Tx" SG_ 842 SeatBlUpDrv_Pc_Actl 1;
BA_ "U_U611_U625_MY20_Hev_Tx" SG_ 842 SeatBlUpDrv_Pc_Actl 1;
BA_ "U_U611_U625_MY20_Gas_Tx" SG_ 842 SeatBlUpDrv_Pc_Actl 1;
BA_ "GenSigSendType" SG_ 842 SeatBlUpDrv_Pc_Actl 3;
BA_ "GenSigStartValue" SG_ 842 SeatBlUpDrv_Pc_Actl 127;
BA_ "GenSigStartValueInteger" SG_ 842 SeatBlUpDrv_Pc_Actl 127;
BA_ "CrossOver_InfoCAN" SG_ 842 SeatBlUpDrv_Pc_Actl 1;
BA_ "U_P702_MY2021_Tx" SG_ 842 SeatBlLoDrv_Pc_Actl 1;
BA_ "U_U611_U625_MY20_Phev_Tx" SG_ 842 SeatBlLoDrv_Pc_Actl 1;
BA_ "U_CX482_CX483_MY20_Tx" SG_ 842 SeatBlLoDrv_Pc_Actl 1;
BA_ "U_U611_U625_MY20_Hev_Tx" SG_ 842 SeatBlLoDrv_Pc_Actl 1;
BA_ "U_U611_U625_MY20_Gas_Tx" SG_ 842 SeatBlLoDrv_Pc_Actl 1;
BA_ "GenSigSendType" SG_ 842 SeatBlLoDrv_Pc_Actl 3;
BA_ "GenSigStartValue" SG_ 842 SeatBlLoDrv_Pc_Actl 127;
BA_ "GenSigStartValueInteger" SG_ 842 SeatBlLoDrv_Pc_Actl 127;
BA_ "CrossOver_InfoCAN" SG_ 842 SeatBlLoDrv_Pc_Actl 1;
BA_ "U_CX727_MY2021_Tx" SG_ 1994 TesterPhysicalResRSM 1;
BA_ "U_CX430_MY2021_Tx" SG_ 1994 TesterPhysicalResRSM 1;
BA_ "U_CX482_CX483_MY20_Tx" SG_ 1994 TesterPhysicalResRSM 1;
BA_ "U_C519_MY18_5_Gas_Tx" SG_ 1994 TesterPhysicalResRSM 1;
BA_ "U_C519_MY18_5_Diesel_Tx" SG_ 1994 TesterPhysicalResRSM 1;
BA_ "U_B515_MCA_MY17_Gas_Tx" SG_ 1994 TesterPhysicalResRSM 1;
BA_ "U_B515_MCA_MY17_Diesel_Tx" SG_ 1994 TesterPhysicalResRSM 1;
BA_ "GenSigSendType" SG_ 1994 TesterPhysicalResRSM 3;
BA_ "U_CX727_MY2021_Rx" SG_ 1986 TesterPhysicalReqRSM 1;
BA_ "U_CX430_MY2021_Rx" SG_ 1986 TesterPhysicalReqRSM 1;
BA_ "U_CX482_CX483_MY20_Rx" SG_ 1986 TesterPhysicalReqRSM 1;
BA_ "U_C519_MY18_5_Gas_Rx" SG_ 1986 TesterPhysicalReqRSM 1;
BA_ "U_C519_MY18_5_Diesel_Rx" SG_ 1986 TesterPhysicalReqRSM 1;
BA_ "U_B515_MCA_MY17_Gas_Rx" SG_ 1986 TesterPhysicalReqRSM 1;
BA_ "U_B515_MCA_MY17_Diesel_Rx" SG_ 1986 TesterPhysicalReqRSM 1;
BA_ "GenSigSendType" SG_ 1986 TesterPhysicalReqRSM 3;
BA_ "U_P702_MY2021_Rx" SG_ 958 ElCmprOverTe_D_Stat 1;
BA_ "U_CX727_MY2021_Rx" SG_ 958 ElCmprOverTe_D_Stat 1;
BA_ "U_CX430_MY2021_Rx" SG_ 958 ElCmprOverTe_D_Stat 1;
BA_ "U_U611_U625_MY20_Phev_Rx" SG_ 958 ElCmprOverTe_D_Stat 1;
BA_ "U_CX482_CX483_MY20_Rx" SG_ 958 ElCmprOverTe_D_Stat 1;
BA_ "U_U611_U625_MY20_Hev_Rx" SG_ 958 ElCmprOverTe_D_Stat 1;
BA_ "U_U611_U625_MY20_Gas_Rx" SG_ 958 ElCmprOverTe_D_Stat 1;
BA_ "GenSigSendType" SG_ 958 ElCmprOverTe_D_Stat 3;
BA_ "GenSigSendType" SG_ 958 ElCmprOverTe_D_Stat_UB 3;
BA_ "U_P702_MY2021_Rx" SG_ 958 ElCmprOverTe_D_Stat_UB 1;
BA_ "U_CX727_MY2021_Rx" SG_ 958 ElCmprOverTe_D_Stat_UB 1;
BA_ "U_CX430_MY2021_Rx" SG_ 958 ElCmprOverTe_D_Stat_UB 1;
BA_ "U_U611_U625_MY20_Phev_Rx" SG_ 958 ElCmprOverTe_D_Stat_UB 1;
BA_ "U_CX482_CX483_MY20_Rx" SG_ 958 ElCmprOverTe_D_Stat_UB 1;
BA_ "U_U611_U625_MY20_Hev_Rx" SG_ 958 ElCmprOverTe_D_Stat_UB 1;
BA_ "U_U611_U625_MY20_Gas_Rx" SG_ 958 ElCmprOverTe_D_Stat_UB 1;
BA_ "U_P702_MY2021_Rx" SG_ 958 EngOff_T_Actl 1;
BA_ "U_CX727_MY2021_Rx" SG_ 958 EngOff_T_Actl 1;
BA_ "U_H567_MY20_Rx" SG_ 958 EngOff_T_Actl 1;
BA_ "U_CX430_MY2021_Rx" SG_ 958 EngOff_T_Actl 1;
BA_ "U_U611_U625_MY20_Phev_Rx" SG_ 958 EngOff_T_Actl 1;
BA_ "U_B562_MY18_Diesel_Rx" SG_ 958 EngOff_T_Actl 1;
BA_ "U_CX482_CX483_MY20_Rx" SG_ 958 EngOff_T_Actl 1;
BA_ "U_U611_U625_MY20_Hev_Rx" SG_ 958 EngOff_T_Actl 1;
BA_ "U_U611_U625_MY20_Gas_Rx" SG_ 958 EngOff_T_Actl 1;
BA_ "U_B500_MY18_Diesel_Rx" SG_ 958 EngOff_T_Actl 1;
BA_ "U_B500_MY18_Gas_Rx" SG_ 958 EngOff_T_Actl 1;
BA_ "U_C490_MY18_Rx" SG_ 958 EngOff_T_Actl 1;
BA_ "U_B562_MY18_Gas_Rx" SG_ 958 EngOff_T_Actl 1;
BA_ "U_C519_MY18_5_Gas_Rx" SG_ 958 EngOff_T_Actl 1;
BA_ "U_C519_MY18_5_Diesel_Rx" SG_ 958 EngOff_T_Actl 1;
BA_ "U_B515_MCA_MY17_Gas_Rx" SG_ 958 EngOff_T_Actl 1;
BA_ "U_B515_MCA_MY17_Diesel_Rx" SG_ 958 EngOff_T_Actl 1;
BA_ "U_B479_MY17_Diesel_Rx" SG_ 958 EngOff_T_Actl 1;
BA_ "U_B479_MY17_Gas_Rx" SG_ 958 EngOff_T_Actl 1;
BA_ "GenSigSendType" SG_ 958 EngOff_T_Actl 3;
BA_ "GenSigSendType" SG_ 958 EngOff_T_Actl_UB 3;
BA_ "U_P702_MY2021_Rx" SG_ 958 EngOff_T_Actl_UB 1;
BA_ "U_CX727_MY2021_Rx" SG_ 958 EngOff_T_Actl_UB 1;
BA_ "U_H567_MY20_Rx" SG_ 958 EngOff_T_Actl_UB 1;
BA_ "U_CX430_MY2021_Rx" SG_ 958 EngOff_T_Actl_UB 1;
BA_ "U_U611_U625_MY20_Phev_Rx" SG_ 958 EngOff_T_Actl_UB 1;
BA_ "U_B562_MY18_Diesel_Rx" SG_ 958 EngOff_T_Actl_UB 1;
BA_ "U_CX482_CX483_MY20_Rx" SG_ 958 EngOff_T_Actl_UB 1;
BA_ "U_U611_U625_MY20_Hev_Rx" SG_ 958 EngOff_T_Actl_UB 1;
BA_ "U_U611_U625_MY20_Gas_Rx" SG_ 958 EngOff_T_Actl_UB 1;
BA_ "U_B500_MY18_Diesel_Rx" SG_ 958 EngOff_T_Actl_UB 1;
BA_ "U_B500_MY18_Gas_Rx" SG_ 958 EngOff_T_Actl_UB 1;
BA_ "U_C490_MY18_Rx" SG_ 958 EngOff_T_Actl_UB 1;
BA_ "U_B562_MY18_Gas_Rx" SG_ 958 EngOff_T_Actl_UB 1;
BA_ "U_C519_MY18_5_Gas_Rx" SG_ 958 EngOff_T_Actl_UB 1;
BA_ "U_C519_MY18_5_Diesel_Rx" SG_ 958 EngOff_T_Actl_UB 1;
BA_ "U_B515_MCA_MY17_Gas_Rx" SG_ 958 EngOff_T_Actl_UB 1;
BA_ "U_B515_MCA_MY17_Diesel_Rx" SG_ 958 EngOff_T_Actl_UB 1;
BA_ "U_B479_MY17_Diesel_Rx" SG_ 958 EngOff_T_Actl_UB 1;
BA_ "U_B479_MY17_Gas_Rx" SG_ 958 EngOff_T_Actl_UB 1;
BA_ "GenSigSendType" SG_ 958 StopStrtDrvMde_D_Indic_UB 3;
BA_ "U_CX727_MY2021_Rx" SG_ 958 StopStrtDrvMde_D_Indic_UB 1;
BA_ "U_CX430_MY2021_Rx" SG_ 958 StopStrtDrvMde_D_Indic_UB 1;
BA_ "U_U611_U625_MY20_Phev_Rx" SG_ 958 StopStrtDrvMde_D_Indic_UB 1;
BA_ "U_B562_MY18_Diesel_Rx" SG_ 958 StopStrtDrvMde_D_Indic_UB 1;
BA_ "U_CX482_CX483_MY20_Rx" SG_ 958 StopStrtDrvMde_D_Indic_UB 1;
BA_ "U_U611_U625_MY20_Hev_Rx" SG_ 958 StopStrtDrvMde_D_Indic_UB 1;
BA_ "U_U611_U625_MY20_Gas_Rx" SG_ 958 StopStrtDrvMde_D_Indic_UB 1;
BA_ "U_B500_MY18_Diesel_Rx" SG_ 958 StopStrtDrvMde_D_Indic_UB 1;
BA_ "U_B500_MY18_Gas_Rx" SG_ 958 StopStrtDrvMde_D_Indic_UB 1;
BA_ "U_C490_MY18_Rx" SG_ 958 StopStrtDrvMde_D_Indic_UB 1;
BA_ "U_B562_MY18_Gas_Rx" SG_ 958 StopStrtDrvMde_D_Indic_UB 1;
BA_ "U_C519_MY18_5_Gas_Rx" SG_ 958 StopStrtDrvMde_D_Indic_UB 1;
BA_ "U_C519_MY18_5_Diesel_Rx" SG_ 958 StopStrtDrvMde_D_Indic_UB 1;
BA_ "U_B515_MCA_MY17_Gas_Rx" SG_ 958 StopStrtDrvMde_D_Indic_UB 1;
BA_ "U_B515_MCA_MY17_Diesel_Rx" SG_ 958 StopStrtDrvMde_D_Indic_UB 1;
BA_ "U_B479_MY17_Diesel_Rx" SG_ 958 StopStrtDrvMde_D_Indic_UB 1;
BA_ "U_B479_MY17_Gas_Rx" SG_ 958 StopStrtDrvMde_D_Indic_UB 1;
BA_ "U_CX727_MY2021_Rx" SG_ 958 PrmtrAlrmEvnt_D_Stat 1;
BA_ "U_CX430_MY2021_Rx" SG_ 958 PrmtrAlrmEvnt_D_Stat 1;
BA_ "U_CX482_CX483_MY20_Rx" SG_ 958 PrmtrAlrmEvnt_D_Stat 1;
BA_ "U_C519_MY18_5_Gas_Rx" SG_ 958 PrmtrAlrmEvnt_D_Stat 1;
BA_ "U_C519_MY18_5_Diesel_Rx" SG_ 958 PrmtrAlrmEvnt_D_Stat 1;
BA_ "U_B515_MCA_MY17_Gas_Rx" SG_ 958 PrmtrAlrmEvnt_D_Stat 1;
BA_ "U_B515_MCA_MY17_Diesel_Rx" SG_ 958 PrmtrAlrmEvnt_D_Stat 1;
BA_ "GenSigSendType" SG_ 958 PrmtrAlrmEvnt_D_Stat 3;
BA_ "U_CX727_MY2021_Rx" SG_ 958 PrmtrAlrmEvnt_D_Stat_UB 1;
BA_ "U_CX430_MY2021_Rx" SG_ 958 PrmtrAlrmEvnt_D_Stat_UB 1;
BA_ "U_CX482_CX483_MY20_Rx" SG_ 958 PrmtrAlrmEvnt_D_Stat_UB 1;
BA_ "U_C519_MY18_5_Gas_Rx" SG_ 958 PrmtrAlrmEvnt_D_Stat_UB 1;
BA_ "U_C519_MY18_5_Diesel_Rx" SG_ 958 PrmtrAlrmEvnt_D_Stat_UB 1;
BA_ "U_B515_MCA_MY17_Gas_Rx" SG_ 958 PrmtrAlrmEvnt_D_Stat_UB 1;
BA_ "U_B515_MCA_MY17_Diesel_Rx" SG_ 958 PrmtrAlrmEvnt_D_Stat_UB 1;
BA_ "U_CX727_MY2021_Rx" SG_ 958 StopStrtDrvMde_D_Indic 1;
BA_ "U_CX430_MY2021_Rx" SG_ 958 StopStrtDrvMde_D_Indic 1;
BA_ "U_U611_U625_MY20_Phev_Rx" SG_ 958 StopStrtDrvMde_D_Indic 1;
BA_ "U_B562_MY18_Diesel_Rx" SG_ 958 StopStrtDrvMde_D_Indic 1;
BA_ "U_CX482_CX483_MY20_Rx" SG_ 958 StopStrtDrvMde_D_Indic 1;
BA_ "U_U611_U625_MY20_Hev_Rx" SG_ 958 StopStrtDrvMde_D_Indic 1;
BA_ "U_U611_U625_MY20_Gas_Rx" SG_ 958 StopStrtDrvMde_D_Indic 1;
BA_ "U_B500_MY18_Diesel_Rx" SG_ 958 StopStrtDrvMde_D_Indic 1;
BA_ "U_B500_MY18_Gas_Rx" SG_ 958 StopStrtDrvMde_D_Indic 1;
BA_ "U_C490_MY18_Rx" SG_ 958 StopStrtDrvMde_D_Indic 1;
BA_ "U_B562_MY18_Gas_Rx" SG_ 958 StopStrtDrvMde_D_Indic 1;
BA_ "U_C519_MY18_5_Gas_Rx" SG_ 958 StopStrtDrvMde_D_Indic 1;
BA_ "U_C519_MY18_5_Diesel_Rx" SG_ 958 StopStrtDrvMde_D_Indic 1;
BA_ "U_B515_MCA_MY17_Gas_Rx" SG_ 958 StopStrtDrvMde_D_Indic 1;
BA_ "U_B515_MCA_MY17_Diesel_Rx" SG_ 958 StopStrtDrvMde_D_Indic 1;
BA_ "U_B479_MY17_Diesel_Rx" SG_ 958 StopStrtDrvMde_D_Indic 1;
BA_ "U_B479_MY17_Gas_Rx" SG_ 958 StopStrtDrvMde_D_Indic 1;
BA_ "GenSigSendType" SG_ 958 StopStrtDrvMde_D_Indic 3;
BA_ "CrossOver_InfoCAN" SG_ 958 StopStrtDrvMde_D_Indic 1;
BA_ "U_CX482_CX483_MY20_Rx" SG_ 958 FuelLvl_Pc_Dsply 1;
BA_ "U_C519_MY18_5_Gas_Rx" SG_ 958 FuelLvl_Pc_Dsply 1;
BA_ "U_C519_MY18_5_Diesel_Rx" SG_ 958 FuelLvl_Pc_Dsply 1;
BA_ "GenSigSendType" SG_ 958 FuelLvl_Pc_Dsply 3;
BA_ "CrossOver_InfoCAN" SG_ 958 FuelLvl_Pc_Dsply 1;
BA_ "U_CX482_CX483_MY20_Rx" SG_ 958 FuelLvl_Pc_Dsply_UB 1;
BA_ "U_C519_MY18_5_Gas_Rx" SG_ 958 FuelLvl_Pc_Dsply_UB 1;
BA_ "U_C519_MY18_5_Diesel_Rx" SG_ 958 FuelLvl_Pc_Dsply_UB 1;
BA_ "GenSigSendType" SG_ 958 OdometerMasterValue_UB 3;
BA_ "U_P702_MY2021_Rx" SG_ 958 OdometerMasterValue_UB 1;
BA_ "U_CX727_MY2021_Rx" SG_ 958 OdometerMasterValue_UB 1;
BA_ "U_U611_U625_MY20_Phev_Rx" SG_ 958 OdometerMasterValue_UB 1;
BA_ "U_CX482_CX483_MY20_Rx" SG_ 958 OdometerMasterValue_UB 1;
BA_ "U_U611_U625_MY20_Hev_Rx" SG_ 958 OdometerMasterValue_UB 1;
BA_ "U_U611_U625_MY20_Gas_Rx" SG_ 958 OdometerMasterValue_UB 1;
BA_ "U_C519_MY18_5_Gas_Rx" SG_ 958 OdometerMasterValue_UB 1;
BA_ "U_C519_MY18_5_Diesel_Rx" SG_ 958 OdometerMasterValue_UB 1;
BA_ "U_B562LC_MY15_Gas_Rx" SG_ 958 OdometerMasterValue_UB 1;
BA_ "U_B562LC_MY15_Diesel_Rx" SG_ 958 OdometerMasterValue_UB 1;
BA_ "U_P702_MY2021_Rx" SG_ 958 OdometerMasterValue 1;
BA_ "U_CX727_MY2021_Rx" SG_ 958 OdometerMasterValue 1;
BA_ "U_U611_U625_MY20_Phev_Rx" SG_ 958 OdometerMasterValue 1;
BA_ "U_CX482_CX483_MY20_Rx" SG_ 958 OdometerMasterValue 1;
BA_ "U_U611_U625_MY20_Hev_Rx" SG_ 958 OdometerMasterValue 1;
BA_ "U_U611_U625_MY20_Gas_Rx" SG_ 958 OdometerMasterValue 1;
BA_ "U_C519_MY18_5_Gas_Rx" SG_ 958 OdometerMasterValue 1;
BA_ "U_C519_MY18_5_Diesel_Rx" SG_ 958 OdometerMasterValue 1;
BA_ "U_B562LC_MY15_Gas_Rx" SG_ 958 OdometerMasterValue 1;
BA_ "U_B562LC_MY15_Diesel_Rx" SG_ 958 OdometerMasterValue 1;
BA_ "GenSigSendType" SG_ 958 OdometerMasterValue 3;
BA_ "CrossOver_InfoCAN" SG_ 958 OdometerMasterValue 1;
BA_ "U_P702_MY2021_Rx" SG_ 827 SteClmnSwtchTlt_D_Stat 1;
BA_ "U_CX727_MY2021_Rx" SG_ 827 SteClmnSwtchTlt_D_Stat 1;
BA_ "U_CX430_MY2021_Rx" SG_ 827 SteClmnSwtchTlt_D_Stat 1;
BA_ "U_U611_U625_MY20_Phev_Rx" SG_ 827 SteClmnSwtchTlt_D_Stat 1;
BA_ "U_CX482_CX483_MY20_Rx" SG_ 827 SteClmnSwtchTlt_D_Stat 1;
BA_ "U_U611_U625_MY20_Hev_Rx" SG_ 827 SteClmnSwtchTlt_D_Stat 1;
BA_ "U_U611_U625_MY20_Gas_Rx" SG_ 827 SteClmnSwtchTlt_D_Stat 1;
BA_ "GenSigSendType" SG_ 827 SteClmnSwtchTlt_D_Stat 3;
BA_ "WakeupSignal" SG_ 827 SteClmnSwtchTlt_D_Stat 1;
BA_ "U_P702_MY2021_Rx" SG_ 827 SteClmnSwtchTel_D_Stat 1;
BA_ "U_CX727_MY2021_Rx" SG_ 827 SteClmnSwtchTel_D_Stat 1;
BA_ "U_CX430_MY2021_Rx" SG_ 827 SteClmnSwtchTel_D_Stat 1;
BA_ "U_U611_U625_MY20_Phev_Rx" SG_ 827 SteClmnSwtchTel_D_Stat 1;
BA_ "U_CX482_CX483_MY20_Rx" SG_ 827 SteClmnSwtchTel_D_Stat 1;
BA_ "U_U611_U625_MY20_Hev_Rx" SG_ 827 SteClmnSwtchTel_D_Stat 1;
BA_ "U_U611_U625_MY20_Gas_Rx" SG_ 827 SteClmnSwtchTel_D_Stat 1;
BA_ "GenSigSendType" SG_ 827 SteClmnSwtchTel_D_Stat 3;
BA_ "WakeupSignal" SG_ 827 SteClmnSwtchTel_D_Stat 1;
BA_ "GenSigSendType" SG_ 827 LghtAmbIntns_D_Sns 3;
BA_ "U_CX727_MY2021_Tx" SG_ 902 PrmtrAlrmWarnRq_No_Actl 1;
BA_ "U_CX430_MY2021_Tx" SG_ 902 PrmtrAlrmWarnRq_No_Actl 1;
BA_ "U_CX482_CX483_MY20_Tx" SG_ 902 PrmtrAlrmWarnRq_No_Actl 1;
BA_ "U_C519_MY18_5_Gas_Tx" SG_ 902 PrmtrAlrmWarnRq_No_Actl 1;
BA_ "U_C519_MY18_5_Diesel_Tx" SG_ 902 PrmtrAlrmWarnRq_No_Actl 1;
BA_ "U_B515_MCA_MY17_Gas_Tx" SG_ 902 PrmtrAlrmWarnRq_No_Actl 1;
BA_ "U_B515_MCA_MY17_Diesel_Tx" SG_ 902 PrmtrAlrmWarnRq_No_Actl 1;
BA_ "GenSigSendType" SG_ 902 PrmtrAlrmWarnRq_No_Actl 3;
BA_ "WakeupSignal" SG_ 902 PrmtrAlrmWarnRq_No_Actl 1;
BA_ "U_CX727_MY2021_Tx" SG_ 902 PrmtrAlrmTrgRq_No_Actl 1;
BA_ "U_CX430_MY2021_Tx" SG_ 902 PrmtrAlrmTrgRq_No_Actl 1;
BA_ "U_CX482_CX483_MY20_Tx" SG_ 902 PrmtrAlrmTrgRq_No_Actl 1;
BA_ "U_C519_MY18_5_Gas_Tx" SG_ 902 PrmtrAlrmTrgRq_No_Actl 1;
BA_ "U_C519_MY18_5_Diesel_Tx" SG_ 902 PrmtrAlrmTrgRq_No_Actl 1;
BA_ "U_B515_MCA_MY17_Gas_Tx" SG_ 902 PrmtrAlrmTrgRq_No_Actl 1;
BA_ "U_B515_MCA_MY17_Diesel_Tx" SG_ 902 PrmtrAlrmTrgRq_No_Actl 1;
BA_ "GenSigSendType" SG_ 902 PrmtrAlrmTrgRq_No_Actl 3;
BA_ "WakeupSignal" SG_ 902 PrmtrAlrmTrgRq_No_Actl 1;
BA_ "U_CX727_MY2021_Tx" SG_ 902 Remote_Start_Req 1;
BA_ "U_CX430_MY2021_Tx" SG_ 902 Remote_Start_Req 1;
BA_ "U_CX482_CX483_MY20_Tx" SG_ 902 Remote_Start_Req 1;
BA_ "U_C519_MY18_5_Gas_Tx" SG_ 902 Remote_Start_Req 1;
BA_ "U_C519_MY18_5_Diesel_Tx" SG_ 902 Remote_Start_Req 1;
BA_ "U_B515_MCA_MY17_Gas_Tx" SG_ 902 Remote_Start_Req 1;
BA_ "U_B515_MCA_MY17_Diesel_Tx" SG_ 902 Remote_Start_Req 1;
BA_ "GenSigSendType" SG_ 902 Remote_Start_Req 3;
BA_ "WakeupSignal" SG_ 902 Remote_Start_Req 1;
BA_ "U_CX727_MY2021_Tx" SG_ 902 RollCode_No_ActlRsm 1;
BA_ "U_CX430_MY2021_Tx" SG_ 902 RollCode_No_ActlRsm 1;
BA_ "U_CX482_CX483_MY20_Tx" SG_ 902 RollCode_No_ActlRsm 1;
BA_ "U_C519_MY18_5_Gas_Tx" SG_ 902 RollCode_No_ActlRsm 1;
BA_ "U_C519_MY18_5_Diesel_Tx" SG_ 902 RollCode_No_ActlRsm 1;
BA_ "U_B515_MCA_MY17_Gas_Tx" SG_ 902 RollCode_No_ActlRsm 1;
BA_ "U_B515_MCA_MY17_Diesel_Tx" SG_ 902 RollCode_No_ActlRsm 1;
BA_ "GenSigSendType" SG_ 902 RollCode_No_ActlRsm 3;
BA_ "WakeupSignal" SG_ 902 RollCode_No_ActlRsm 1;
BA_ "U_CX727_MY2021_Tx" SG_ 902 PrmtrAlrmWarn_B_Rq 1;
BA_ "U_CX430_MY2021_Tx" SG_ 902 PrmtrAlrmWarn_B_Rq 1;
BA_ "U_CX482_CX483_MY20_Tx" SG_ 902 PrmtrAlrmWarn_B_Rq 1;
BA_ "U_C519_MY18_5_Gas_Tx" SG_ 902 PrmtrAlrmWarn_B_Rq 1;
BA_ "U_C519_MY18_5_Diesel_Tx" SG_ 902 PrmtrAlrmWarn_B_Rq 1;
BA_ "U_B515_MCA_MY17_Gas_Tx" SG_ 902 PrmtrAlrmWarn_B_Rq 1;
BA_ "U_B515_MCA_MY17_Diesel_Tx" SG_ 902 PrmtrAlrmWarn_B_Rq 1;
BA_ "GenSigSendType" SG_ 902 PrmtrAlrmWarn_B_Rq 3;
BA_ "WakeupSignal" SG_ 902 PrmtrAlrmWarn_B_Rq 1;
BA_ "U_CX727_MY2021_Tx" SG_ 902 PrmtrAlrmTrg_B_Rq 1;
BA_ "U_CX430_MY2021_Tx" SG_ 902 PrmtrAlrmTrg_B_Rq 1;
BA_ "U_CX482_CX483_MY20_Tx" SG_ 902 PrmtrAlrmTrg_B_Rq 1;
BA_ "U_C519_MY18_5_Gas_Tx" SG_ 902 PrmtrAlrmTrg_B_Rq 1;
BA_ "U_C519_MY18_5_Diesel_Tx" SG_ 902 PrmtrAlrmTrg_B_Rq 1;
BA_ "U_B515_MCA_MY17_Gas_Tx" SG_ 902 PrmtrAlrmTrg_B_Rq 1;
BA_ "U_B515_MCA_MY17_Diesel_Tx" SG_ 902 PrmtrAlrmTrg_B_Rq 1;
BA_ "GenSigSendType" SG_ 902 PrmtrAlrmTrg_B_Rq 3;
BA_ "WakeupSignal" SG_ 902 PrmtrAlrmTrg_B_Rq 1;
BA_ "U_CX727_MY2021_Tx" SG_ 902 PanicRq_No_ActlRsm 1;
BA_ "U_CX430_MY2021_Tx" SG_ 902 PanicRq_No_ActlRsm 1;
BA_ "U_CX482_CX483_MY20_Tx" SG_ 902 PanicRq_No_ActlRsm 1;
BA_ "U_C519_MY18_5_Gas_Tx" SG_ 902 PanicRq_No_ActlRsm 1;
BA_ "U_C519_MY18_5_Diesel_Tx" SG_ 902 PanicRq_No_ActlRsm 1;
BA_ "U_B515_MCA_MY17_Gas_Tx" SG_ 902 PanicRq_No_ActlRsm 1;
BA_ "U_B515_MCA_MY17_Diesel_Tx" SG_ 902 PanicRq_No_ActlRsm 1;
BA_ "GenSigSendType" SG_ 902 PanicRq_No_ActlRsm 3;
BA_ "WakeupSignal" SG_ 902 PanicRq_No_ActlRsm 1;
BA_ "U_CX727_MY2021_Tx" SG_ 902 Panic_D_RqRsm 1;
BA_ "U_CX430_MY2021_Tx" SG_ 902 Panic_D_RqRsm 1;
BA_ "U_CX482_CX483_MY20_Tx" SG_ 902 Panic_D_RqRsm 1;
BA_ "U_C519_MY18_5_Gas_Tx" SG_ 902 Panic_D_RqRsm 1;
BA_ "U_C519_MY18_5_Diesel_Tx" SG_ 902 Panic_D_RqRsm 1;
BA_ "U_B515_MCA_MY17_Gas_Tx" SG_ 902 Panic_D_RqRsm 1;
BA_ "U_B515_MCA_MY17_Diesel_Tx" SG_ 902 Panic_D_RqRsm 1;
BA_ "GenSigSendType" SG_ 902 Panic_D_RqRsm 3;
BA_ "WakeupSignal" SG_ 902 Panic_D_RqRsm 1;
BA_ "U_CX727_MY2021_Tx" SG_ 902 CellLockRq_No_ActlRsm 1;
BA_ "U_CX430_MY2021_Tx" SG_ 902 CellLockRq_No_ActlRsm 1;
BA_ "U_CX482_CX483_MY20_Tx" SG_ 902 CellLockRq_No_ActlRsm 1;
BA_ "U_C519_MY18_5_Gas_Tx" SG_ 902 CellLockRq_No_ActlRsm 1;
BA_ "U_C519_MY18_5_Diesel_Tx" SG_ 902 CellLockRq_No_ActlRsm 1;
BA_ "U_B515_MCA_MY17_Gas_Tx" SG_ 902 CellLockRq_No_ActlRsm 1;
BA_ "U_B515_MCA_MY17_Diesel_Tx" SG_ 902 CellLockRq_No_ActlRsm 1;
BA_ "GenSigSendType" SG_ 902 CellLockRq_No_ActlRsm 3;
BA_ "WakeupSignal" SG_ 902 CellLockRq_No_ActlRsm 1;
BA_ "U_CX727_MY2021_Tx" SG_ 902 CellLock_D_RqRsm 1;
BA_ "U_CX430_MY2021_Tx" SG_ 902 CellLock_D_RqRsm 1;
BA_ "U_CX482_CX483_MY20_Tx" SG_ 902 CellLock_D_RqRsm 1;
BA_ "U_C519_MY18_5_Gas_Tx" SG_ 902 CellLock_D_RqRsm 1;
BA_ "U_C519_MY18_5_Diesel_Tx" SG_ 902 CellLock_D_RqRsm 1;
BA_ "U_B515_MCA_MY17_Gas_Tx" SG_ 902 CellLock_D_RqRsm 1;
BA_ "U_B515_MCA_MY17_Diesel_Tx" SG_ 902 CellLock_D_RqRsm 1;
BA_ "GenSigSendType" SG_ 902 CellLock_D_RqRsm 3;
BA_ "WakeupSignal" SG_ 902 CellLock_D_RqRsm 1;
BA_ "U_U611_U625_MY20_Gas_Rx" SG_ 765 ValetMode_D_Stat_UB 1;
BA_ "U_U611_U625_MY20_Hev_Rx" SG_ 765 ValetMode_D_Stat_UB 1;
BA_ "U_CX482_CX483_MY20_Rx" SG_ 765 ValetMode_D_Stat_UB 1;
BA_ "U_U611_U625_MY20_Phev_Rx" SG_ 765 ValetMode_D_Stat_UB 1;
BA_ "U_CX430_MY2021_Rx" SG_ 765 ValetMode_D_Stat_UB 1;
BA_ "U_CX727_MY2021_Rx" SG_ 765 ValetMode_D_Stat_UB 1;
BA_ "U_P702_MY2021_Rx" SG_ 765 ValetMode_D_Stat_UB 1;
BA_ "GenSigSendType" SG_ 765 ValetMode_D_Stat 3;
BA_ "CrossOver_InfoCAN" SG_ 765 ValetMode_D_Stat 1;
BA_ "U_U611_U625_MY20_Gas_Rx" SG_ 765 ValetMode_D_Stat 1;
BA_ "U_U611_U625_MY20_Hev_Rx" SG_ 765 ValetMode_D_Stat 1;
BA_ "U_CX482_CX483_MY20_Rx" SG_ 765 ValetMode_D_Stat 1;
BA_ "U_U611_U625_MY20_Phev_Rx" SG_ 765 ValetMode_D_Stat 1;
BA_ "U_CX430_MY2021_Rx" SG_ 765 ValetMode_D_Stat 1;
BA_ "U_CX727_MY2021_Rx" SG_ 765 ValetMode_D_Stat 1;
BA_ "U_P702_MY2021_Rx" SG_ 765 ValetMode_D_Stat 1;
BA_ "CrossOver_InfoCAN" SG_ 765 CcStat_D_Actl_UB 1;
BA_ "CrossOver_InfoCAN" SG_ 765 CcStat_D_Actl 1;
BA_ "GenSigSendType" SG_ 765 ClimtBlwrLim_B_Rq_UB 3;
BA_ "U_CX727_MY2021_Rx" SG_ 765 ClimtBlwrLim_B_Rq_UB 1;
BA_ "U_CX430_MY2021_Rx" SG_ 765 ClimtBlwrLim_B_Rq_UB 1;
BA_ "U_B562_MY18_Diesel_Rx" SG_ 765 ClimtBlwrLim_B_Rq_UB 1;
BA_ "U_CX482_CX483_MY20_Rx" SG_ 765 ClimtBlwrLim_B_Rq_UB 1;
BA_ "U_B562_MY18_Gas_Rx" SG_ 765 ClimtBlwrLim_B_Rq_UB 1;
BA_ "U_C519_MY18_5_Gas_Rx" SG_ 765 ClimtBlwrLim_B_Rq_UB 1;
BA_ "U_C519_MY18_5_Diesel_Rx" SG_ 765 ClimtBlwrLim_B_Rq_UB 1;
BA_ "U_CX727_MY2021_Rx" SG_ 765 ClimtBlwrLim_B_Rq 1;
BA_ "U_CX430_MY2021_Rx" SG_ 765 ClimtBlwrLim_B_Rq 1;
BA_ "U_B562_MY18_Diesel_Rx" SG_ 765 ClimtBlwrLim_B_Rq 1;
BA_ "U_CX482_CX483_MY20_Rx" SG_ 765 ClimtBlwrLim_B_Rq 1;
BA_ "U_B562_MY18_Gas_Rx" SG_ 765 ClimtBlwrLim_B_Rq 1;
BA_ "U_C519_MY18_5_Gas_Rx" SG_ 765 ClimtBlwrLim_B_Rq 1;
BA_ "U_C519_MY18_5_Diesel_Rx" SG_ 765 ClimtBlwrLim_B_Rq 1;
BA_ "GenSigSendType" SG_ 765 ClimtBlwrLim_B_Rq 3;
BA_ "GenSigSendType" SG_ 765 TrlrBrkActCnnct_B_Actl 3;
BA_ "U_P702_MY2021_Rx" SG_ 765 EmPrflButtnAssoc_D_Rq 1;
BA_ "U_CX727_MY2021_Rx" SG_ 765 EmPrflButtnAssoc_D_Rq 1;
BA_ "U_CX430_MY2021_Rx" SG_ 765 EmPrflButtnAssoc_D_Rq 1;
BA_ "U_U611_U625_MY20_Phev_Rx" SG_ 765 EmPrflButtnAssoc_D_Rq 1;
BA_ "U_CX482_CX483_MY20_Rx" SG_ 765 EmPrflButtnAssoc_D_Rq 1;
BA_ "U_U611_U625_MY20_Hev_Rx" SG_ 765 EmPrflButtnAssoc_D_Rq 1;
BA_ "U_U611_U625_MY20_Gas_Rx" SG_ 765 EmPrflButtnAssoc_D_Rq 1;
BA_ "GenSigSendType" SG_ 765 EmPrflButtnAssoc_D_Rq 3;
BA_ "U_P702_MY2021_Rx" SG_ 765 EmPrflButtnAssoc_D_Rq_UB 1;
BA_ "U_CX727_MY2021_Rx" SG_ 765 EmPrflButtnAssoc_D_Rq_UB 1;
BA_ "U_CX430_MY2021_Rx" SG_ 765 EmPrflButtnAssoc_D_Rq_UB 1;
BA_ "U_U611_U625_MY20_Phev_Rx" SG_ 765 EmPrflButtnAssoc_D_Rq_UB 1;
BA_ "U_CX482_CX483_MY20_Rx" SG_ 765 EmPrflButtnAssoc_D_Rq_UB 1;
BA_ "U_U611_U625_MY20_Hev_Rx" SG_ 765 EmPrflButtnAssoc_D_Rq_UB 1;
BA_ "U_U611_U625_MY20_Gas_Rx" SG_ 765 EmPrflButtnAssoc_D_Rq_UB 1;
BA_ "GenSigSendType" SG_ 765 CamraFrntStat_D_Stat_UB 3;
BA_ "U_CX727_MY2021_Rx" SG_ 765 CamraFrntStat_D_Stat_UB 1;
BA_ "U_CX430_MY2021_Rx" SG_ 765 CamraFrntStat_D_Stat_UB 1;
BA_ "U_U611_U625_MY20_Phev_Rx" SG_ 765 CamraFrntStat_D_Stat_UB 1;
BA_ "U_CX482_CX483_MY20_Rx" SG_ 765 CamraFrntStat_D_Stat_UB 1;
BA_ "U_U611_U625_MY20_Hev_Rx" SG_ 765 CamraFrntStat_D_Stat_UB 1;
BA_ "U_U611_U625_MY20_Gas_Rx" SG_ 765 CamraFrntStat_D_Stat_UB 1;
BA_ "U_B500_MY18_Diesel_Rx" SG_ 765 CamraFrntStat_D_Stat_UB 1;
BA_ "U_B500_MY18_Gas_Rx" SG_ 765 CamraFrntStat_D_Stat_UB 1;
BA_ "U_C519_MY18_5_Gas_Rx" SG_ 765 CamraFrntStat_D_Stat_UB 1;
BA_ "U_C519_MY18_5_Diesel_Rx" SG_ 765 CamraFrntStat_D_Stat_UB 1;
BA_ "U_B515_MCA_MY17_Gas_Rx" SG_ 765 CamraFrntStat_D_Stat_UB 1;
BA_ "U_B515_MCA_MY17_Diesel_Rx" SG_ 765 CamraFrntStat_D_Stat_UB 1;
BA_ "U_B479_MY17_Diesel_Rx" SG_ 765 CamraFrntStat_D_Stat_UB 1;
BA_ "U_B479_MY17_Gas_Rx" SG_ 765 CamraFrntStat_D_Stat_UB 1;
BA_ "U_CX727_MY2021_Rx" SG_ 765 CamraFrntStat_D_Stat 1;
BA_ "U_CX430_MY2021_Rx" SG_ 765 CamraFrntStat_D_Stat 1;
BA_ "U_U611_U625_MY20_Phev_Rx" SG_ 765 CamraFrntStat_D_Stat 1;
BA_ "U_CX482_CX483_MY20_Rx" SG_ 765 CamraFrntStat_D_Stat 1;
BA_ "U_U611_U625_MY20_Hev_Rx" SG_ 765 CamraFrntStat_D_Stat 1;
BA_ "U_U611_U625_MY20_Gas_Rx" SG_ 765 CamraFrntStat_D_Stat 1;
BA_ "U_B500_MY18_Diesel_Rx" SG_ 765 CamraFrntStat_D_Stat 1;
BA_ "U_B500_MY18_Gas_Rx" SG_ 765 CamraFrntStat_D_Stat 1;
BA_ "U_C519_MY18_5_Gas_Rx" SG_ 765 CamraFrntStat_D_Stat 1;
BA_ "U_C519_MY18_5_Diesel_Rx" SG_ 765 CamraFrntStat_D_Stat 1;
BA_ "U_B515_MCA_MY17_Gas_Rx" SG_ 765 CamraFrntStat_D_Stat 1;
BA_ "U_B515_MCA_MY17_Diesel_Rx" SG_ 765 CamraFrntStat_D_Stat 1;
BA_ "U_B479_MY17_Diesel_Rx" SG_ 765 CamraFrntStat_D_Stat 1;
BA_ "U_B479_MY17_Gas_Rx" SG_ 765 CamraFrntStat_D_Stat 1;
BA_ "GenSigSendType" SG_ 765 CamraFrntStat_D_Stat 3;
BA_ "GenSigSendType" SG_ 765 AutoHoldSwMde_B_Ind_UB 3;
BA_ "U_CX727_MY2021_Rx" SG_ 765 AutoHoldSwMde_B_Ind_UB 1;
BA_ "U_CX430_MY2021_Rx" SG_ 765 AutoHoldSwMde_B_Ind_UB 1;
BA_ "U_U611_U625_MY20_Phev_Rx" SG_ 765 AutoHoldSwMde_B_Ind_UB 1;
BA_ "U_CX482_CX483_MY20_Rx" SG_ 765 AutoHoldSwMde_B_Ind_UB 1;
BA_ "U_U611_U625_MY20_Hev_Rx" SG_ 765 AutoHoldSwMde_B_Ind_UB 1;
BA_ "U_U611_U625_MY20_Gas_Rx" SG_ 765 AutoHoldSwMde_B_Ind_UB 1;
BA_ "U_B500_MY18_Diesel_Rx" SG_ 765 AutoHoldSwMde_B_Ind_UB 1;
BA_ "U_B500_MY18_Gas_Rx" SG_ 765 AutoHoldSwMde_B_Ind_UB 1;
BA_ "U_C519_MY18_5_Gas_Rx" SG_ 765 AutoHoldSwMde_B_Ind_UB 1;
BA_ "U_C519_MY18_5_Diesel_Rx" SG_ 765 AutoHoldSwMde_B_Ind_UB 1;
BA_ "U_B515_MCA_MY17_Gas_Rx" SG_ 765 AutoHoldSwMde_B_Ind_UB 1;
BA_ "U_B515_MCA_MY17_Diesel_Rx" SG_ 765 AutoHoldSwMde_B_Ind_UB 1;
BA_ "U_B479_MY17_Diesel_Rx" SG_ 765 AutoHoldSwMde_B_Ind_UB 1;
BA_ "U_B479_MY17_Gas_Rx" SG_ 765 AutoHoldSwMde_B_Ind_UB 1;
BA_ "U_CX727_MY2021_Rx" SG_ 765 AutoHoldSwMde_B_Ind 1;
BA_ "U_CX430_MY2021_Rx" SG_ 765 AutoHoldSwMde_B_Ind 1;
BA_ "U_U611_U625_MY20_Phev_Rx" SG_ 765 AutoHoldSwMde_B_Ind 1;
BA_ "U_CX482_CX483_MY20_Rx" SG_ 765 AutoHoldSwMde_B_Ind 1;
BA_ "U_U611_U625_MY20_Hev_Rx" SG_ 765 AutoHoldSwMde_B_Ind 1;
BA_ "U_U611_U625_MY20_Gas_Rx" SG_ 765 AutoHoldSwMde_B_Ind 1;
BA_ "U_B500_MY18_Diesel_Rx" SG_ 765 AutoHoldSwMde_B_Ind 1;
BA_ "U_B500_MY18_Gas_Rx" SG_ 765 AutoHoldSwMde_B_Ind 1;
BA_ "U_C519_MY18_5_Gas_Rx" SG_ 765 AutoHoldSwMde_B_Ind 1;
BA_ "U_C519_MY18_5_Diesel_Rx" SG_ 765 AutoHoldSwMde_B_Ind 1;
BA_ "U_B515_MCA_MY17_Gas_Rx" SG_ 765 AutoHoldSwMde_B_Ind 1;
BA_ "U_B515_MCA_MY17_Diesel_Rx" SG_ 765 AutoHoldSwMde_B_Ind 1;
BA_ "U_B479_MY17_Diesel_Rx" SG_ 765 AutoHoldSwMde_B_Ind 1;
BA_ "U_B479_MY17_Gas_Rx" SG_ 765 AutoHoldSwMde_B_Ind 1;
BA_ "GenSigSendType" SG_ 765 AutoHoldSwMde_B_Ind 3;
BA_ "ContentDependant" SG_ 765 AutoHoldSwMde_B_Ind 1;
BA_ "CrossOver_InfoCAN" SG_ 765 AutoHoldSwMde_B_Ind 1;
BA_ "U_P702_MY2021_Rx" SG_ 765 SteWhlHeat_D_Stat 1;
BA_ "U_CX727_MY2021_Rx" SG_ 765 SteWhlHeat_D_Stat 1;
BA_ "U_CX430_MY2021_Rx" SG_ 765 SteWhlHeat_D_Stat 1;
BA_ "U_U611_U625_MY20_Phev_Rx" SG_ 765 SteWhlHeat_D_Stat 1;
BA_ "U_CX482_CX483_MY20_Rx" SG_ 765 SteWhlHeat_D_Stat 1;
BA_ "U_U611_U625_MY20_Hev_Rx" SG_ 765 SteWhlHeat_D_Stat 1;
BA_ "U_U611_U625_MY20_Gas_Rx" SG_ 765 SteWhlHeat_D_Stat 1;
BA_ "U_B500_MY18_Diesel_Rx" SG_ 765 SteWhlHeat_D_Stat 1;
BA_ "U_B500_MY18_Gas_Rx" SG_ 765 SteWhlHeat_D_Stat 1;
BA_ "U_C519_MY18_5_Gas_Rx" SG_ 765 SteWhlHeat_D_Stat 1;
BA_ "U_C519_MY18_5_Diesel_Rx" SG_ 765 SteWhlHeat_D_Stat 1;
BA_ "U_B515_MCA_MY17_Gas_Rx" SG_ 765 SteWhlHeat_D_Stat 1;
BA_ "U_B515_MCA_MY17_Diesel_Rx" SG_ 765 SteWhlHeat_D_Stat 1;
BA_ "U_B479_MY17_Diesel_Rx" SG_ 765 SteWhlHeat_D_Stat 1;
BA_ "U_B479_MY17_Gas_Rx" SG_ 765 SteWhlHeat_D_Stat 1;
BA_ "GenSigSendType" SG_ 765 SteWhlHeat_D_Stat 3;
BA_ "GenSigSendType" SG_ 765 Running_Board_Cmd 3;
BA_ "GenSigSendType" SG_ 765 Bezel_Beeps_Rq 3;
BA_ "CrossOver_InfoCAN" SG_ 765 Bezel_Beeps_Rq 1;
BA_ "WakeupSignal" SG_ 765 Bezel_Beeps_Rq 1;
BA_ "GenSigSendType" SG_ 765 Diagnostic_Operation_Rq_UB 3;
BA_ "U_P702_MY2021_Rx" SG_ 765 Diagnostic_Operation_Rq_UB 1;
BA_ "U_CX727_MY2021_Rx" SG_ 765 Diagnostic_Operation_Rq_UB 1;
BA_ "U_U611_U625_MY20_Phev_Rx" SG_ 765 Diagnostic_Operation_Rq_UB 1;
BA_ "U_B562_MY18_Diesel_Rx" SG_ 765 Diagnostic_Operation_Rq_UB 1;
BA_ "U_CX482_CX483_MY20_Rx" SG_ 765 Diagnostic_Operation_Rq_UB 1;
BA_ "U_U611_U625_MY20_Hev_Rx" SG_ 765 Diagnostic_Operation_Rq_UB 1;
BA_ "U_U611_U625_MY20_Gas_Rx" SG_ 765 Diagnostic_Operation_Rq_UB 1;
BA_ "U_B562_MY18_Gas_Rx" SG_ 765 Diagnostic_Operation_Rq_UB 1;
BA_ "U_P702_MY2021_Rx" SG_ 765 Diagnostic_Operation_Rq 1;
BA_ "U_CX727_MY2021_Rx" SG_ 765 Diagnostic_Operation_Rq 1;
BA_ "U_U611_U625_MY20_Phev_Rx" SG_ 765 Diagnostic_Operation_Rq 1;
BA_ "U_B562_MY18_Diesel_Rx" SG_ 765 Diagnostic_Operation_Rq 1;
BA_ "U_CX482_CX483_MY20_Rx" SG_ 765 Diagnostic_Operation_Rq 1;
BA_ "U_U611_U625_MY20_Hev_Rx" SG_ 765 Diagnostic_Operation_Rq 1;
BA_ "U_U611_U625_MY20_Gas_Rx" SG_ 765 Diagnostic_Operation_Rq 1;
BA_ "U_B562_MY18_Gas_Rx" SG_ 765 Diagnostic_Operation_Rq 1;
BA_ "GenSigSendType" SG_ 765 Diagnostic_Operation_Rq 3;
BA_ "CrossOver_InfoCAN" SG_ 765 Diagnostic_Operation_Rq 1;
BA_ "GenSigSendType" SG_ 765 Bezel_Diag_State_Rq 3;
BA_ "CrossOver_InfoCAN" SG_ 765 Bezel_Diag_State_Rq 1;
BA_ "GenSigSendType" SG_ 765 Bezel_Diag_Module_Rq 3;
BA_ "CrossOver_InfoCAN" SG_ 765 Bezel_Diag_Module_Rq 1;
BA_ "GenSigSendType" SG_ 765 HMI_HMIMode_St_UB 3;
BA_ "U_CX430_MY2021_Rx" SG_ 765 HMI_HMIMode_St_UB 1;
BA_ "U_B500_MY18_Diesel_Rx" SG_ 765 HMI_HMIMode_St_UB 1;
BA_ "U_B500_MY18_Gas_Rx" SG_ 765 HMI_HMIMode_St_UB 1;
BA_ "U_C519_MY18_5_Gas_Rx" SG_ 765 HMI_HMIMode_St_UB 1;
BA_ "U_C519_MY18_5_Diesel_Rx" SG_ 765 HMI_HMIMode_St_UB 1;
BA_ "U_B515_MCA_MY17_Gas_Rx" SG_ 765 HMI_HMIMode_St_UB 1;
BA_ "U_B515_MCA_MY17_Diesel_Rx" SG_ 765 HMI_HMIMode_St_UB 1;
BA_ "U_B479_MY17_Diesel_Rx" SG_ 765 HMI_HMIMode_St_UB 1;
BA_ "U_B479_MY17_Gas_Rx" SG_ 765 HMI_HMIMode_St_UB 1;
BA_ "U_CX727_MY2021_Rx" SG_ 765 HMI_HMIMode_St_UB 1;
BA_ "U_U611_U625_MY20_Phev_Rx" SG_ 765 HMI_HMIMode_St_UB 1;
BA_ "U_CX482_CX483_MY20_Rx" SG_ 765 HMI_HMIMode_St_UB 1;
BA_ "U_U611_U625_MY20_Hev_Rx" SG_ 765 HMI_HMIMode_St_UB 1;
BA_ "U_U611_U625_MY20_Gas_Rx" SG_ 765 HMI_HMIMode_St_UB 1;
BA_ "U_CX430_MY2021_Rx" SG_ 765 HMI_HMIMode_St 1;
BA_ "U_B500_MY18_Diesel_Rx" SG_ 765 HMI_HMIMode_St 1;
BA_ "U_B500_MY18_Gas_Rx" SG_ 765 HMI_HMIMode_St 1;
BA_ "U_B515_MCA_MY17_Gas_Rx" SG_ 765 HMI_HMIMode_St 1;
BA_ "U_B515_MCA_MY17_Diesel_Rx" SG_ 765 HMI_HMIMode_St 1;
BA_ "U_B479_MY17_Diesel_Rx" SG_ 765 HMI_HMIMode_St 1;
BA_ "U_B479_MY17_Gas_Rx" SG_ 765 HMI_HMIMode_St 1;
BA_ "U_CX727_MY2021_Rx" SG_ 765 HMI_HMIMode_St 1;
BA_ "U_U611_U625_MY20_Phev_Rx" SG_ 765 HMI_HMIMode_St 1;
BA_ "U_CX482_CX483_MY20_Rx" SG_ 765 HMI_HMIMode_St 1;
BA_ "U_U611_U625_MY20_Hev_Rx" SG_ 765 HMI_HMIMode_St 1;
BA_ "U_U611_U625_MY20_Gas_Rx" SG_ 765 HMI_HMIMode_St 1;
BA_ "U_C519_MY18_5_Gas_Rx" SG_ 765 HMI_HMIMode_St 1;
BA_ "U_C519_MY18_5_Diesel_Rx" SG_ 765 HMI_HMIMode_St 1;
BA_ "GenSigSendType" SG_ 765 HMI_HMIMode_St 3;
BA_ "CrossOver_InfoCAN" SG_ 765 HMI_HMIMode_St 1;
BA_ "WakeupSignal" SG_ 765 HMI_HMIMode_St 1;
BA_ "GenSigSendType" SG_ 765 Mc_VehUnitTempUsrSel_St_UB 3;
BA_ "U_P702_MY2021_Rx" SG_ 765 Mc_VehUnitTempUsrSel_St_UB 1;
BA_ "U_CX727_MY2021_Rx" SG_ 765 Mc_VehUnitTempUsrSel_St_UB 1;
BA_ "U_H567_MY20_Rx" SG_ 765 Mc_VehUnitTempUsrSel_St_UB 1;
BA_ "U_CX430_MY2021_Rx" SG_ 765 Mc_VehUnitTempUsrSel_St_UB 1;
BA_ "U_U611_U625_MY20_Phev_Rx" SG_ 765 Mc_VehUnitTempUsrSel_St_UB 1;
BA_ "U_B562_MY18_Diesel_Rx" SG_ 765 Mc_VehUnitTempUsrSel_St_UB 1;
BA_ "U_CX482_CX483_MY20_Rx" SG_ 765 Mc_VehUnitTempUsrSel_St_UB 1;
BA_ "U_U611_U625_MY20_Hev_Rx" SG_ 765 Mc_VehUnitTempUsrSel_St_UB 1;
BA_ "U_U611_U625_MY20_Gas_Rx" SG_ 765 Mc_VehUnitTempUsrSel_St_UB 1;
BA_ "U_B500_MY18_Diesel_Rx" SG_ 765 Mc_VehUnitTempUsrSel_St_UB 1;
BA_ "U_B500_MY18_Gas_Rx" SG_ 765 Mc_VehUnitTempUsrSel_St_UB 1;
BA_ "U_C490_MY18_Rx" SG_ 765 Mc_VehUnitTempUsrSel_St_UB 1;
BA_ "U_B562_MY18_Gas_Rx" SG_ 765 Mc_VehUnitTempUsrSel_St_UB 1;
BA_ "U_C519_MY18_5_Gas_Rx" SG_ 765 Mc_VehUnitTempUsrSel_St_UB 1;
BA_ "U_C519_MY18_5_Diesel_Rx" SG_ 765 Mc_VehUnitTempUsrSel_St_UB 1;
BA_ "U_B515_MCA_MY17_Gas_Rx" SG_ 765 Mc_VehUnitTempUsrSel_St_UB 1;
BA_ "U_B515_MCA_MY17_Diesel_Rx" SG_ 765 Mc_VehUnitTempUsrSel_St_UB 1;
BA_ "U_B479_MY17_Diesel_Rx" SG_ 765 Mc_VehUnitTempUsrSel_St_UB 1;
BA_ "U_B479_MY17_Gas_Rx" SG_ 765 Mc_VehUnitTempUsrSel_St_UB 1;
BA_ "U_P702_MY2021_Rx" SG_ 765 Mc_VehUnitTempUsrSel_St 1;
BA_ "U_CX727_MY2021_Rx" SG_ 765 Mc_VehUnitTempUsrSel_St 1;
BA_ "U_H567_MY20_Rx" SG_ 765 Mc_VehUnitTempUsrSel_St 1;
BA_ "U_CX430_MY2021_Rx" SG_ 765 Mc_VehUnitTempUsrSel_St 1;
BA_ "U_U611_U625_MY20_Phev_Rx" SG_ 765 Mc_VehUnitTempUsrSel_St 1;
BA_ "U_B562_MY18_Diesel_Rx" SG_ 765 Mc_VehUnitTempUsrSel_St 1;
BA_ "U_CX482_CX483_MY20_Rx" SG_ 765 Mc_VehUnitTempUsrSel_St 1;
BA_ "U_U611_U625_MY20_Hev_Rx" SG_ 765 Mc_VehUnitTempUsrSel_St 1;
BA_ "U_U611_U625_MY20_Gas_Rx" SG_ 765 Mc_VehUnitTempUsrSel_St 1;
BA_ "U_B500_MY18_Diesel_Rx" SG_ 765 Mc_VehUnitTempUsrSel_St 1;
BA_ "U_B500_MY18_Gas_Rx" SG_ 765 Mc_VehUnitTempUsrSel_St 1;
BA_ "U_C490_MY18_Rx" SG_ 765 Mc_VehUnitTempUsrSel_St 1;
BA_ "U_B562_MY18_Gas_Rx" SG_ 765 Mc_VehUnitTempUsrSel_St 1;
BA_ "U_C519_MY18_5_Gas_Rx" SG_ 765 Mc_VehUnitTempUsrSel_St 1;
BA_ "U_C519_MY18_5_Diesel_Rx" SG_ 765 Mc_VehUnitTempUsrSel_St 1;
BA_ "U_B515_MCA_MY17_Gas_Rx" SG_ 765 Mc_VehUnitTempUsrSel_St 1;
BA_ "U_B515_MCA_MY17_Diesel_Rx" SG_ 765 Mc_VehUnitTempUsrSel_St 1;
BA_ "U_B479_MY17_Diesel_Rx" SG_ 765 Mc_VehUnitTempUsrSel_St 1;
BA_ "U_B479_MY17_Gas_Rx" SG_ 765 Mc_VehUnitTempUsrSel_St 1;
BA_ "GenSigSendType" SG_ 765 Mc_VehUnitTempUsrSel_St 3;
BA_ "CrossOver_InfoCAN" SG_ 765 Mc_VehUnitTempUsrSel_St 1;
BA_ "GenSigSendType" SG_ 765 PsngrFrntDetct_D_Actl_UB 3;
BA_ "U_P702_MY2021_Rx" SG_ 765 PsngrFrntDetct_D_Actl_UB 1;
BA_ "U_CX727_MY2021_Rx" SG_ 765 PsngrFrntDetct_D_Actl_UB 1;
BA_ "U_CX430_MY2021_Rx" SG_ 765 PsngrFrntDetct_D_Actl_UB 1;
BA_ "U_U611_U625_MY20_Phev_Rx" SG_ 765 PsngrFrntDetct_D_Actl_UB 1;
BA_ "U_CX482_CX483_MY20_Rx" SG_ 765 PsngrFrntDetct_D_Actl_UB 1;
BA_ "U_U611_U625_MY20_Hev_Rx" SG_ 765 PsngrFrntDetct_D_Actl_UB 1;
BA_ "U_U611_U625_MY20_Gas_Rx" SG_ 765 PsngrFrntDetct_D_Actl_UB 1;
BA_ "U_B500_MY18_Diesel_Rx" SG_ 765 PsngrFrntDetct_D_Actl_UB 1;
BA_ "U_B500_MY18_Gas_Rx" SG_ 765 PsngrFrntDetct_D_Actl_UB 1;
BA_ "U_C519_MY18_5_Gas_Rx" SG_ 765 PsngrFrntDetct_D_Actl_UB 1;
BA_ "U_C519_MY18_5_Diesel_Rx" SG_ 765 PsngrFrntDetct_D_Actl_UB 1;
BA_ "U_B515_MCA_MY17_Gas_Rx" SG_ 765 PsngrFrntDetct_D_Actl_UB 1;
BA_ "U_B515_MCA_MY17_Diesel_Rx" SG_ 765 PsngrFrntDetct_D_Actl_UB 1;
BA_ "U_B479_MY17_Diesel_Rx" SG_ 765 PsngrFrntDetct_D_Actl_UB 1;
BA_ "U_B479_MY17_Gas_Rx" SG_ 765 PsngrFrntDetct_D_Actl_UB 1;
BA_ "U_P702_MY2021_Rx" SG_ 765 PsngrFrntDetct_D_Actl 1;
BA_ "U_CX727_MY2021_Rx" SG_ 765 PsngrFrntDetct_D_Actl 1;
BA_ "U_CX430_MY2021_Rx" SG_ 765 PsngrFrntDetct_D_Actl 1;
BA_ "U_U611_U625_MY20_Phev_Rx" SG_ 765 PsngrFrntDetct_D_Actl 1;
BA_ "U_CX482_CX483_MY20_Rx" SG_ 765 PsngrFrntDetct_D_Actl 1;
BA_ "U_U611_U625_MY20_Hev_Rx" SG_ 765 PsngrFrntDetct_D_Actl 1;
BA_ "U_U611_U625_MY20_Gas_Rx" SG_ 765 PsngrFrntDetct_D_Actl 1;
BA_ "U_B500_MY18_Diesel_Rx" SG_ 765 PsngrFrntDetct_D_Actl 1;
BA_ "U_B500_MY18_Gas_Rx" SG_ 765 PsngrFrntDetct_D_Actl 1;
BA_ "U_C519_MY18_5_Gas_Rx" SG_ 765 PsngrFrntDetct_D_Actl 1;
BA_ "U_C519_MY18_5_Diesel_Rx" SG_ 765 PsngrFrntDetct_D_Actl 1;
BA_ "U_B515_MCA_MY17_Gas_Rx" SG_ 765 PsngrFrntDetct_D_Actl 1;
BA_ "U_B515_MCA_MY17_Diesel_Rx" SG_ 765 PsngrFrntDetct_D_Actl 1;
BA_ "U_B479_MY17_Diesel_Rx" SG_ 765 PsngrFrntDetct_D_Actl 1;
BA_ "U_B479_MY17_Gas_Rx" SG_ 765 PsngrFrntDetct_D_Actl 1;
BA_ "GenSigSendType" SG_ 765 PsngrFrntDetct_D_Actl 3;
BA_ "GenSigStartValue" SG_ 765 PsngrFrntDetct_D_Actl 3;
BA_ "GenSigStartValueInteger" SG_ 765 PsngrFrntDetct_D_Actl 3;
BA_ "CrossOver_InfoCAN" SG_ 765 PsngrFrntDetct_D_Actl 1;
BA_ "GenSigSendType" SG_ 765 SteWhlHeat_D_Stat_UB 3;
BA_ "U_P702_MY2021_Rx" SG_ 765 SteWhlHeat_D_Stat_UB 1;
BA_ "U_CX727_MY2021_Rx" SG_ 765 SteWhlHeat_D_Stat_UB 1;
BA_ "U_CX430_MY2021_Rx" SG_ 765 SteWhlHeat_D_Stat_UB 1;
BA_ "U_U611_U625_MY20_Phev_Rx" SG_ 765 SteWhlHeat_D_Stat_UB 1;
BA_ "U_CX482_CX483_MY20_Rx" SG_ 765 SteWhlHeat_D_Stat_UB 1;
BA_ "U_U611_U625_MY20_Hev_Rx" SG_ 765 SteWhlHeat_D_Stat_UB 1;
BA_ "U_U611_U625_MY20_Gas_Rx" SG_ 765 SteWhlHeat_D_Stat_UB 1;
BA_ "U_B500_MY18_Diesel_Rx" SG_ 765 SteWhlHeat_D_Stat_UB 1;
BA_ "U_B500_MY18_Gas_Rx" SG_ 765 SteWhlHeat_D_Stat_UB 1;
BA_ "U_C519_MY18_5_Gas_Rx" SG_ 765 SteWhlHeat_D_Stat_UB 1;
BA_ "U_C519_MY18_5_Diesel_Rx" SG_ 765 SteWhlHeat_D_Stat_UB 1;
BA_ "U_B515_MCA_MY17_Gas_Rx" SG_ 765 SteWhlHeat_D_Stat_UB 1;
BA_ "U_B515_MCA_MY17_Diesel_Rx" SG_ 765 SteWhlHeat_D_Stat_UB 1;
BA_ "U_B479_MY17_Diesel_Rx" SG_ 765 SteWhlHeat_D_Stat_UB 1;
BA_ "U_B479_MY17_Gas_Rx" SG_ 765 SteWhlHeat_D_Stat_UB 1;
BA_ "U_CX727_MY2021_Rx" SG_ 765 ParkDetect_Stat_UB 1;
BA_ "U_CX430_MY2021_Rx" SG_ 765 ParkDetect_Stat_UB 1;
BA_ "U_CX482_CX483_MY20_Rx" SG_ 765 ParkDetect_Stat_UB 1;
BA_ "U_B500_MY18_Diesel_Rx" SG_ 765 ParkDetect_Stat_UB 1;
BA_ "U_B500_MY18_Gas_Rx" SG_ 765 ParkDetect_Stat_UB 1;
BA_ "U_C519_MY18_5_Gas_Rx" SG_ 765 ParkDetect_Stat_UB 1;
BA_ "U_C519_MY18_5_Diesel_Rx" SG_ 765 ParkDetect_Stat_UB 1;
BA_ "U_B515_MCA_MY17_Gas_Rx" SG_ 765 ParkDetect_Stat_UB 1;
BA_ "U_B515_MCA_MY17_Diesel_Rx" SG_ 765 ParkDetect_Stat_UB 1;
BA_ "U_CX727_MY2021_Rx" SG_ 765 ParkDetect_Stat 1;
BA_ "U_CX430_MY2021_Rx" SG_ 765 ParkDetect_Stat 1;
BA_ "U_CX482_CX483_MY20_Rx" SG_ 765 ParkDetect_Stat 1;
BA_ "U_B500_MY18_Diesel_Rx" SG_ 765 ParkDetect_Stat 1;
BA_ "U_B500_MY18_Gas_Rx" SG_ 765 ParkDetect_Stat 1;
BA_ "U_C519_MY18_5_Gas_Rx" SG_ 765 ParkDetect_Stat 1;
BA_ "U_C519_MY18_5_Diesel_Rx" SG_ 765 ParkDetect_Stat 1;
BA_ "U_B515_MCA_MY17_Gas_Rx" SG_ 765 ParkDetect_Stat 1;
BA_ "U_B515_MCA_MY17_Diesel_Rx" SG_ 765 ParkDetect_Stat 1;
BA_ "GenSigSendType" SG_ 765 ParkDetect_Stat 3;
BA_ "CrossOver_InfoCAN" SG_ 765 ParkDetect_Stat 1;
BA_ "GenSigSendType" SG_ 765 Voice_Blower_Limit_UB 3;
BA_ "U_P702_MY2021_Rx" SG_ 765 Voice_Blower_Limit_UB 1;
BA_ "U_CX727_MY2021_Rx" SG_ 765 Voice_Blower_Limit_UB 1;
BA_ "U_CX430_MY2021_Rx" SG_ 765 Voice_Blower_Limit_UB 1;
BA_ "U_U611_U625_MY20_Phev_Rx" SG_ 765 Voice_Blower_Limit_UB 1;
BA_ "U_B562_MY18_Diesel_Rx" SG_ 765 Voice_Blower_Limit_UB 1;
BA_ "U_CX482_CX483_MY20_Rx" SG_ 765 Voice_Blower_Limit_UB 1;
BA_ "U_U611_U625_MY20_Hev_Rx" SG_ 765 Voice_Blower_Limit_UB 1;
BA_ "U_U611_U625_MY20_Gas_Rx" SG_ 765 Voice_Blower_Limit_UB 1;
BA_ "U_B500_MY18_Diesel_Rx" SG_ 765 Voice_Blower_Limit_UB 1;
BA_ "U_B500_MY18_Gas_Rx" SG_ 765 Voice_Blower_Limit_UB 1;
BA_ "U_B562_MY18_Gas_Rx" SG_ 765 Voice_Blower_Limit_UB 1;
BA_ "U_C519_MY18_5_Gas_Rx" SG_ 765 Voice_Blower_Limit_UB 1;
BA_ "U_C519_MY18_5_Diesel_Rx" SG_ 765 Voice_Blower_Limit_UB 1;
BA_ "U_B515_MCA_MY17_Gas_Rx" SG_ 765 Voice_Blower_Limit_UB 1;
BA_ "U_B515_MCA_MY17_Diesel_Rx" SG_ 765 Voice_Blower_Limit_UB 1;
BA_ "U_B479_MY17_Diesel_Rx" SG_ 765 Voice_Blower_Limit_UB 1;
BA_ "U_B479_MY17_Gas_Rx" SG_ 765 Voice_Blower_Limit_UB 1;
BA_ "CrossOver_InfoCAN" SG_ 765 Voice_Blower_Limit_UB 1;
BA_ "U_P702_MY2021_Rx" SG_ 765 Voice_Blower_Limit 1;
BA_ "U_CX727_MY2021_Rx" SG_ 765 Voice_Blower_Limit 1;
BA_ "U_CX430_MY2021_Rx" SG_ 765 Voice_Blower_Limit 1;
BA_ "U_U611_U625_MY20_Phev_Rx" SG_ 765 Voice_Blower_Limit 1;
BA_ "U_B562_MY18_Diesel_Rx" SG_ 765 Voice_Blower_Limit 1;
BA_ "U_CX482_CX483_MY20_Rx" SG_ 765 Voice_Blower_Limit 1;
BA_ "U_U611_U625_MY20_Hev_Rx" SG_ 765 Voice_Blower_Limit 1;
BA_ "U_U611_U625_MY20_Gas_Rx" SG_ 765 Voice_Blower_Limit 1;
BA_ "U_B500_MY18_Diesel_Rx" SG_ 765 Voice_Blower_Limit 1;
BA_ "U_B500_MY18_Gas_Rx" SG_ 765 Voice_Blower_Limit 1;
BA_ "U_B562_MY18_Gas_Rx" SG_ 765 Voice_Blower_Limit 1;
BA_ "U_C519_MY18_5_Gas_Rx" SG_ 765 Voice_Blower_Limit 1;
BA_ "U_C519_MY18_5_Diesel_Rx" SG_ 765 Voice_Blower_Limit 1;
BA_ "U_B515_MCA_MY17_Gas_Rx" SG_ 765 Voice_Blower_Limit 1;
BA_ "U_B515_MCA_MY17_Diesel_Rx" SG_ 765 Voice_Blower_Limit 1;
BA_ "U_B479_MY17_Diesel_Rx" SG_ 765 Voice_Blower_Limit 1;
BA_ "U_B479_MY17_Gas_Rx" SG_ 765 Voice_Blower_Limit 1;
BA_ "GenSigSendType" SG_ 765 Voice_Blower_Limit 3;
BA_ "CrossOver_InfoCAN" SG_ 765 Voice_Blower_Limit 1;
BA_ "CrossOver_InfoCAN" SG_ 765 PwStep_D_DrvInhbt_UB 1;
BA_ "GenSigSendType" SG_ 765 PwStep_D_DrvInhbt 3;
BA_ "GenSigSendType" SG_ 874 FrtTe_An_Actl 3;
BA_ "U_U611_U625_MY20_Phev_Rx" SG_ 874 FrtTe_An_Actl 1;
BA_ "U_CX482_CX483_MY20_Rx" SG_ 874 FrtTe_An_Actl 1;
BA_ "U_U611_U625_MY20_Hev_Rx" SG_ 874 FrtTe_An_Actl 1;
BA_ "U_U611_U625_MY20_Gas_Rx" SG_ 874 FrtTe_An_Actl 1;
BA_ "GenSigStartValue" SG_ 874 FrtTe_An_Actl 511;
BA_ "GenSigStartValueInteger" SG_ 874 FrtTe_An_Actl 511;
BA_ "GenSigSendType" SG_ 874 FrtBlwr_An_Actl 3;
BA_ "U_U611_U625_MY20_Phev_Rx" SG_ 874 FrtBlwr_An_Actl 1;
BA_ "U_CX482_CX483_MY20_Rx" SG_ 874 FrtBlwr_An_Actl 1;
BA_ "U_U611_U625_MY20_Hev_Rx" SG_ 874 FrtBlwr_An_Actl 1;
BA_ "U_U611_U625_MY20_Gas_Rx" SG_ 874 FrtBlwr_An_Actl 1;
BA_ "GenSigStartValue" SG_ 874 FrtBlwr_An_Actl 511;
BA_ "GenSigStartValueInteger" SG_ 874 FrtBlwr_An_Actl 511;
BA_ "GenSigSendType" SG_ 874 E_Voice_Blower_Limit 3;
BA_ "U_U611_U625_MY20_Phev_Rx" SG_ 874 E_Voice_Blower_Limit 1;
BA_ "U_CX482_CX483_MY20_Rx" SG_ 874 E_Voice_Blower_Limit 1;
BA_ "U_U611_U625_MY20_Hev_Rx" SG_ 874 E_Voice_Blower_Limit 1;
BA_ "U_U611_U625_MY20_Gas_Rx" SG_ 874 E_Voice_Blower_Limit 1;
BA_ "GenSigSendType" SG_ 874 E_Rr_Btn_Status_2nd 3;
BA_ "U_U611_U625_MY20_Phev_Rx" SG_ 874 E_Rr_Btn_Status_2nd 1;
BA_ "U_CX482_CX483_MY20_Rx" SG_ 874 E_Rr_Btn_Status_2nd 1;
BA_ "U_U611_U625_MY20_Hev_Rx" SG_ 874 E_Rr_Btn_Status_2nd 1;
BA_ "U_U611_U625_MY20_Gas_Rx" SG_ 874 E_Rr_Btn_Status_2nd 1;
BA_ "GenSigSendType" SG_ 874 E_Rr_Btn_Status_1st 3;
BA_ "U_U611_U625_MY20_Phev_Rx" SG_ 874 E_Rr_Btn_Status_1st 1;
BA_ "U_CX482_CX483_MY20_Rx" SG_ 874 E_Rr_Btn_Status_1st 1;
BA_ "U_U611_U625_MY20_Hev_Rx" SG_ 874 E_Rr_Btn_Status_1st 1;
BA_ "U_U611_U625_MY20_Gas_Rx" SG_ 874 E_Rr_Btn_Status_1st 1;
BA_ "GenSigSendType" SG_ 874 E_Frt_Btn_Status_2nd 3;
BA_ "U_U611_U625_MY20_Phev_Rx" SG_ 874 E_Frt_Btn_Status_2nd 1;
BA_ "U_CX482_CX483_MY20_Rx" SG_ 874 E_Frt_Btn_Status_2nd 1;
BA_ "U_U611_U625_MY20_Hev_Rx" SG_ 874 E_Frt_Btn_Status_2nd 1;
BA_ "U_U611_U625_MY20_Gas_Rx" SG_ 874 E_Frt_Btn_Status_2nd 1;
BA_ "GenSigSendType" SG_ 874 E_Frt_Btn_Status_1st 3;
BA_ "U_U611_U625_MY20_Phev_Rx" SG_ 874 E_Frt_Btn_Status_1st 1;
BA_ "U_CX482_CX483_MY20_Rx" SG_ 874 E_Frt_Btn_Status_1st 1;
BA_ "U_U611_U625_MY20_Hev_Rx" SG_ 874 E_Frt_Btn_Status_1st 1;
BA_ "U_U611_U625_MY20_Gas_Rx" SG_ 874 E_Frt_Btn_Status_1st 1;
BA_ "GenSigSendType" SG_ 874 E_Frt_Blwr_Speed 3;
BA_ "U_U611_U625_MY20_Phev_Rx" SG_ 874 E_Frt_Blwr_Speed 1;
BA_ "U_CX482_CX483_MY20_Rx" SG_ 874 E_Frt_Blwr_Speed 1;
BA_ "U_U611_U625_MY20_Hev_Rx" SG_ 874 E_Frt_Blwr_Speed 1;
BA_ "U_U611_U625_MY20_Gas_Rx" SG_ 874 E_Frt_Blwr_Speed 1;
BA_ "CrossOver_InfoCAN" SG_ 874 E_Frt_Blwr_Speed 1;
BA_ "GenSigSendType" SG_ 874 E_Drv_Set_Temp 3;
BA_ "U_U611_U625_MY20_Phev_Rx" SG_ 874 E_Drv_Set_Temp 1;
BA_ "U_CX482_CX483_MY20_Rx" SG_ 874 E_Drv_Set_Temp 1;
BA_ "U_U611_U625_MY20_Hev_Rx" SG_ 874 E_Drv_Set_Temp 1;
BA_ "U_U611_U625_MY20_Gas_Rx" SG_ 874 E_Drv_Set_Temp 1;
BA_ "GenSigStartValueInteger" SG_ 359 PrplWhlRgenMn_Tq_Actl 4095;
BA_ "CrossOver_InfoCAN" SG_ 359 ElPw_D_StatStrtStop 1;
BA_ "ContentDependant" SG_ 359 TrnAin_Tq_Actl 1;
BA_ "CrossOver_InfoCAN" SG_ 359 TrnAin_Tq_Actl 1;
BA_ "CrossOver_InfoCAN" SG_ 359 PrplWhlTot2_Tq_Actl 1;
BA_ "CrossOver_InfoCAN" SG_ 359 LscmbbDeny_B_ActlPrpl 1;
BA_ "CrossOver_InfoCAN" SG_ 359 LscmbbEngTqMn_B_Actl 1;
BA_ "MetaData" SG_ 359 TrnAinTq_D_Qf 1;
BA_ "ContentDependant" SG_ 359 TrnAinTq_D_Qf 1;
BA_ "CrossOver_InfoCAN" SG_ 359 TrnAinTq_D_Qf 1;
BA_ "U_B562_MY18_Diesel_Rx" SG_ 359 PwPckTq_D_Stat 1;
BA_ "U_B500_MY18_Diesel_Rx" SG_ 359 PwPckTq_D_Stat 1;
BA_ "U_B500_MY18_Gas_Rx" SG_ 359 PwPckTq_D_Stat 1;
BA_ "U_B562_MY18_Gas_Rx" SG_ 359 PwPckTq_D_Stat 1;
BA_ "U_VN127_MY20_Rx" SG_ 359 PwPckTq_D_Stat 1;
BA_ "U_H567_MY20_Rx" SG_ 359 PwPckTq_D_Stat 1;
BA_ "U_B562LC_MY15_Gas_Rx" SG_ 359 PwPckTq_D_Stat 1;
BA_ "U_B562LC_MY15_Diesel_Rx" SG_ 359 PwPckTq_D_Stat 1;
BA_ "U_P702_MY2021_Rx" SG_ 359 PwPckTq_D_Stat 1;
BA_ "U_CX727_MY2021_Rx" SG_ 359 PwPckTq_D_Stat 1;
BA_ "U_CX430_MY2021_Rx" SG_ 359 PwPckTq_D_Stat 1;
BA_ "U_U611_U625_MY20_Phev_Rx" SG_ 359 PwPckTq_D_Stat 1;
BA_ "U_U611_U625_MY20_Hev_Rx" SG_ 359 PwPckTq_D_Stat 1;
BA_ "U_U611_U625_MY20_Gas_Rx" SG_ 359 PwPckTq_D_Stat 1;
BA_ "U_C490_MY18_Rx" SG_ 359 PwPckTq_D_Stat 1;
BA_ "U_B515_MCA_MY17_Gas_Rx" SG_ 359 PwPckTq_D_Stat 1;
BA_ "U_B515_MCA_MY17_Diesel_Rx" SG_ 359 PwPckTq_D_Stat 1;
BA_ "U_B479_MY17_Diesel_Rx" SG_ 359 PwPckTq_D_Stat 1;
BA_ "U_B479_MY17_Gas_Rx" SG_ 359 PwPckTq_D_Stat 1;
BA_ "U_CX482_CX483_MY20_Rx" SG_ 359 PwPckTq_D_Stat 1;
BA_ "U_C519_MY18_5_Gas_Rx" SG_ 359 PwPckTq_D_Stat 1;
BA_ "U_C519_MY18_5_Diesel_Rx" SG_ 359 PwPckTq_D_Stat 1;
BA_ "GenSigSendType" SG_ 359 PwPckTq_D_Stat 3;
BA_ "CrossOver_InfoCAN" SG_ 359 PwPckTq_D_Stat 1;
BA_ "U_P702_MY2021_Rx" SG_ 359 Eng_D_Stat 1;
BA_ "U_CX727_MY2021_Rx" SG_ 359 Eng_D_Stat 1;
BA_ "U_H567_MY20_Rx" SG_ 359 Eng_D_Stat 1;
BA_ "U_CX430_MY2021_Rx" SG_ 359 Eng_D_Stat 1;
BA_ "U_U611_U625_MY20_Phev_Rx" SG_ 359 Eng_D_Stat 1;
BA_ "U_B562_MY18_Diesel_Rx" SG_ 359 Eng_D_Stat 1;
BA_ "U_U611_U625_MY20_Hev_Rx" SG_ 359 Eng_D_Stat 1;
BA_ "U_U611_U625_MY20_Gas_Rx" SG_ 359 Eng_D_Stat 1;
BA_ "U_B500_MY18_Diesel_Rx" SG_ 359 Eng_D_Stat 1;
BA_ "U_B500_MY18_Gas_Rx" SG_ 359 Eng_D_Stat 1;
BA_ "U_C490_MY18_Rx" SG_ 359 Eng_D_Stat 1;
BA_ "U_B562_MY18_Gas_Rx" SG_ 359 Eng_D_Stat 1;
BA_ "U_B515_MCA_MY17_Gas_Rx" SG_ 359 Eng_D_Stat 1;
BA_ "U_B515_MCA_MY17_Diesel_Rx" SG_ 359 Eng_D_Stat 1;
BA_ "U_B479_MY17_Diesel_Rx" SG_ 359 Eng_D_Stat 1;
BA_ "U_B479_MY17_Gas_Rx" SG_ 359 Eng_D_Stat 1;
BA_ "U_CX482_CX483_MY20_Rx" SG_ 359 Eng_D_Stat 1;
BA_ "U_C519_MY18_5_Gas_Rx" SG_ 359 Eng_D_Stat 1;
BA_ "U_C519_MY18_5_Diesel_Rx" SG_ 359 Eng_D_Stat 1;
BA_ "GenSigSendType" SG_ 359 Eng_D_Stat 3;
BA_ "CrossOver_InfoCAN" SG_ 359 Eng_D_Stat 1;
BA_ "GenSigStartValue" SG_ 359 PlgActvArb_B_Actl 1;
BA_ "ContentDependant" SG_ 359 PlgActvArb_B_Actl 1;
BA_ "GenSigStartValueInteger" SG_ 359 PlgActvArb_B_Actl 1;
BA_ "CrossOver_InfoCAN" SG_ 359 PlgActvArb_B_Actl 1;
BA_ "U_B562_MY18_Diesel_Rx" SG_ 359 ElPw_D_Stat 1;
BA_ "U_B500_MY18_Diesel_Rx" SG_ 359 ElPw_D_Stat 1;
BA_ "U_B500_MY18_Gas_Rx" SG_ 359 ElPw_D_Stat 1;
BA_ "U_B562_MY18_Gas_Rx" SG_ 359 ElPw_D_Stat 1;
BA_ "U_C490_MY18_Rx" SG_ 359 ElPw_D_Stat 1;
BA_ "U_B562LC_MY15_Gas_Rx" SG_ 359 ElPw_D_Stat 1;
BA_ "U_B562LC_MY15_Diesel_Rx" SG_ 359 ElPw_D_Stat 1;
BA_ "U_P702_MY2021_Rx" SG_ 359 ElPw_D_Stat 1;
BA_ "U_CX727_MY2021_Rx" SG_ 359 ElPw_D_Stat 1;
BA_ "U_VN127_MY20_Rx" SG_ 359 ElPw_D_Stat 1;
BA_ "U_H567_MY20_Rx" SG_ 359 ElPw_D_Stat 1;
BA_ "U_CX430_MY2021_Rx" SG_ 359 ElPw_D_Stat 1;
BA_ "U_U611_U625_MY20_Phev_Rx" SG_ 359 ElPw_D_Stat 1;
BA_ "U_CX482_CX483_MY20_Rx" SG_ 359 ElPw_D_Stat 1;
BA_ "U_U611_U625_MY20_Hev_Rx" SG_ 359 ElPw_D_Stat 1;
BA_ "U_U611_U625_MY20_Gas_Rx" SG_ 359 ElPw_D_Stat 1;
BA_ "U_C519_MY18_5_Gas_Rx" SG_ 359 ElPw_D_Stat 1;
BA_ "U_C519_MY18_5_Diesel_Rx" SG_ 359 ElPw_D_Stat 1;
BA_ "U_B515_MCA_MY17_Gas_Rx" SG_ 359 ElPw_D_Stat 1;
BA_ "U_B515_MCA_MY17_Diesel_Rx" SG_ 359 ElPw_D_Stat 1;
BA_ "U_B479_MY17_Diesel_Rx" SG_ 359 ElPw_D_Stat 1;
BA_ "U_B479_MY17_Gas_Rx" SG_ 359 ElPw_D_Stat 1;
BA_ "GenSigSendType" SG_ 359 ElPw_D_Stat 3;
BA_ "CrossOver_InfoCAN" SG_ 359 ElPw_D_Stat 1;
BA_ "U_CX727_MY2021_Rx" SG_ 131 StePinCompAnEst_D_Qf 1;
BA_ "U_CX430_MY2021_Rx" SG_ 131 StePinCompAnEst_D_Qf 1;
BA_ "U_U611_U625_MY20_Phev_Rx" SG_ 131 StePinCompAnEst_D_Qf 1;
BA_ "U_CX482_CX483_MY20_Rx" SG_ 131 StePinCompAnEst_D_Qf 1;
BA_ "U_U611_U625_MY20_Hev_Rx" SG_ 131 StePinCompAnEst_D_Qf 1;
BA_ "U_U611_U625_MY20_Gas_Rx" SG_ 131 StePinCompAnEst_D_Qf 1;
BA_ "U_C519_MY18_5_Gas_Rx" SG_ 131 StePinCompAnEst_D_Qf 1;
BA_ "U_C519_MY18_5_Diesel_Rx" SG_ 131 StePinCompAnEst_D_Qf 1;
BA_ "GenSigStartValue" SG_ 131 StePinCompAnEst_D_Qf 1;
BA_ "GenSigStartValueInteger" SG_ 131 StePinCompAnEst_D_Qf 1;
BA_ "CrossOver_InfoCAN" SG_ 131 StePinCompAnEst_D_Qf 1;
BA_ "U_CX727_MY2021_Rx" SG_ 131 StePinComp_An_Est_UB 1;
BA_ "U_CX430_MY2021_Rx" SG_ 131 StePinComp_An_Est_UB 1;
BA_ "U_U611_U625_MY20_Phev_Rx" SG_ 131 StePinComp_An_Est_UB 1;
BA_ "U_CX482_CX483_MY20_Rx" SG_ 131 StePinComp_An_Est_UB 1;
BA_ "U_U611_U625_MY20_Hev_Rx" SG_ 131 StePinComp_An_Est_UB 1;
BA_ "U_U611_U625_MY20_Gas_Rx" SG_ 131 StePinComp_An_Est_UB 1;
BA_ "U_C519_MY18_5_Gas_Rx" SG_ 131 StePinComp_An_Est_UB 1;
BA_ "U_C519_MY18_5_Diesel_Rx" SG_ 131 StePinComp_An_Est_UB 1;
BA_ "U_CX727_MY2021_Rx" SG_ 131 StePinComp_An_Est 1;
BA_ "U_CX430_MY2021_Rx" SG_ 131 StePinComp_An_Est 1;
BA_ "U_U611_U625_MY20_Phev_Rx" SG_ 131 StePinComp_An_Est 1;
BA_ "U_CX482_CX483_MY20_Rx" SG_ 131 StePinComp_An_Est 1;
BA_ "U_U611_U625_MY20_Hev_Rx" SG_ 131 StePinComp_An_Est 1;
BA_ "U_U611_U625_MY20_Gas_Rx" SG_ 131 StePinComp_An_Est 1;
BA_ "U_C519_MY18_5_Gas_Rx" SG_ 131 StePinComp_An_Est 1;
BA_ "U_C519_MY18_5_Diesel_Rx" SG_ 131 StePinComp_An_Est 1;
BA_ "GenSigStartValueInteger" SG_ 131 StePinComp_An_Est 16000;
BA_ "U_CX727_MY2021_Rx" SG_ 131 VehLongComp_A_Actl_UB 1;
BA_ "U_U611_U625_MY20_Phev_Rx" SG_ 131 VehLongComp_A_Actl_UB 1;
BA_ "U_CX482_CX483_MY20_Rx" SG_ 131 VehLongComp_A_Actl_UB 1;
BA_ "U_U611_U625_MY20_Hev_Rx" SG_ 131 VehLongComp_A_Actl_UB 1;
BA_ "U_U611_U625_MY20_Gas_Rx" SG_ 131 VehLongComp_A_Actl_UB 1;
BA_ "U_C519_MY18_5_Gas_Rx" SG_ 131 VehLongComp_A_Actl_UB 1;
BA_ "U_C519_MY18_5_Diesel_Rx" SG_ 131 VehLongComp_A_Actl_UB 1;
BA_ "U_CX727_MY2021_Rx" SG_ 131 VehLatComp_A_Actl_UB 1;
BA_ "U_U611_U625_MY20_Phev_Rx" SG_ 131 VehLatComp_A_Actl_UB 1;
BA_ "U_CX482_CX483_MY20_Rx" SG_ 131 VehLatComp_A_Actl_UB 1;
BA_ "U_U611_U625_MY20_Hev_Rx" SG_ 131 VehLatComp_A_Actl_UB 1;
BA_ "U_U611_U625_MY20_Gas_Rx" SG_ 131 VehLatComp_A_Actl_UB 1;
BA_ "U_C519_MY18_5_Gas_Rx" SG_ 131 VehLatComp_A_Actl_UB 1;
BA_ "U_C519_MY18_5_Diesel_Rx" SG_ 131 VehLatComp_A_Actl_UB 1;
BA_ "U_CX727_MY2021_Rx" SG_ 131 VehLongComp_A_Actl 1;
BA_ "U_U611_U625_MY20_Phev_Rx" SG_ 131 VehLongComp_A_Actl 1;
BA_ "U_CX482_CX483_MY20_Rx" SG_ 131 VehLongComp_A_Actl 1;
BA_ "U_U611_U625_MY20_Hev_Rx" SG_ 131 VehLongComp_A_Actl 1;
BA_ "U_U611_U625_MY20_Gas_Rx" SG_ 131 VehLongComp_A_Actl 1;
BA_ "U_C519_MY18_5_Gas_Rx" SG_ 131 VehLongComp_A_Actl 1;
BA_ "U_C519_MY18_5_Diesel_Rx" SG_ 131 VehLongComp_A_Actl 1;
BA_ "GenSigStartValue" SG_ 131 VehLongComp_A_Actl 1022;
BA_ "GenSigStartValueInteger" SG_ 131 VehLongComp_A_Actl 1022;
BA_ "U_CX727_MY2021_Rx" SG_ 131 VehLatComp_A_Actl 1;
BA_ "U_U611_U625_MY20_Phev_Rx" SG_ 131 VehLatComp_A_Actl 1;
BA_ "U_CX482_CX483_MY20_Rx" SG_ 131 VehLatComp_A_Actl 1;
BA_ "U_U611_U625_MY20_Hev_Rx" SG_ 131 VehLatComp_A_Actl 1;
BA_ "U_U611_U625_MY20_Gas_Rx" SG_ 131 VehLatComp_A_Actl 1;
BA_ "U_C519_MY18_5_Gas_Rx" SG_ 131 VehLatComp_A_Actl 1;
BA_ "U_C519_MY18_5_Diesel_Rx" SG_ 131 VehLatComp_A_Actl 1;
BA_ "GenSigStartValue" SG_ 131 VehLatComp_A_Actl 1022;
BA_ "GenSigStartValueInteger" SG_ 131 VehLatComp_A_Actl 1022;
BA_ "U_CX727_MY2021_Rx" SG_ 131 VehYaw_W_Actl_UB 1;
BA_ "U_CX430_MY2021_Rx" SG_ 131 VehYaw_W_Actl_UB 1;
BA_ "U_U611_U625_MY20_Phev_Rx" SG_ 131 VehYaw_W_Actl_UB 1;
BA_ "U_CX482_CX483_MY20_Rx" SG_ 131 VehYaw_W_Actl_UB 1;
BA_ "U_U611_U625_MY20_Hev_Rx" SG_ 131 VehYaw_W_Actl_UB 1;
BA_ "U_U611_U625_MY20_Gas_Rx" SG_ 131 VehYaw_W_Actl_UB 1;
BA_ "U_C519_MY18_5_Gas_Rx" SG_ 131 VehYaw_W_Actl_UB 1;
BA_ "U_C519_MY18_5_Diesel_Rx" SG_ 131 VehYaw_W_Actl_UB 1;
BA_ "U_B515_MCA_MY17_Gas_Rx" SG_ 131 VehYaw_W_Actl_UB 1;
BA_ "U_B515_MCA_MY17_Diesel_Rx" SG_ 131 VehYaw_W_Actl_UB 1;
BA_ "U_B479_MY17_Diesel_Rx" SG_ 131 VehYaw_W_Actl_UB 1;
BA_ "U_B479_MY17_Gas_Rx" SG_ 131 VehYaw_W_Actl_UB 1;
BA_ "U_CX727_MY2021_Rx" SG_ 131 VehYaw_W_Actl 1;
BA_ "U_CX430_MY2021_Rx" SG_ 131 VehYaw_W_Actl 1;
BA_ "U_U611_U625_MY20_Phev_Rx" SG_ 131 VehYaw_W_Actl 1;
BA_ "U_CX482_CX483_MY20_Rx" SG_ 131 VehYaw_W_Actl 1;
BA_ "U_U611_U625_MY20_Hev_Rx" SG_ 131 VehYaw_W_Actl 1;
BA_ "U_U611_U625_MY20_Gas_Rx" SG_ 131 VehYaw_W_Actl 1;
BA_ "U_C519_MY18_5_Gas_Rx" SG_ 131 VehYaw_W_Actl 1;
BA_ "U_C519_MY18_5_Diesel_Rx" SG_ 131 VehYaw_W_Actl 1;
BA_ "U_B515_MCA_MY17_Gas_Rx" SG_ 131 VehYaw_W_Actl 1;
BA_ "U_B515_MCA_MY17_Diesel_Rx" SG_ 131 VehYaw_W_Actl 1;
BA_ "U_B479_MY17_Diesel_Rx" SG_ 131 VehYaw_W_Actl 1;
BA_ "U_B479_MY17_Gas_Rx" SG_ 131 VehYaw_W_Actl 1;
BA_ "GenSigStartValue" SG_ 131 VehYaw_W_Actl 65534;
BA_ "GenSigStartValueInteger" SG_ 131 VehYaw_W_Actl 65534;
BA_ "U_P702_MY2021_Tx" SG_ 990 PersIndexDdm_D_Actl 1;
BA_ "U_CX727_MY2021_Tx" SG_ 990 PersIndexDdm_D_Actl 1;
BA_ "U_CX430_MY2021_Tx" SG_ 990 PersIndexDdm_D_Actl 1;
BA_ "U_U611_U625_MY20_Phev_Tx" SG_ 990 PersIndexDdm_D_Actl 1;
BA_ "U_CX482_CX483_MY20_Tx" SG_ 990 PersIndexDdm_D_Actl 1;
BA_ "U_U611_U625_MY20_Hev_Tx" SG_ 990 PersIndexDdm_D_Actl 1;
BA_ "U_U611_U625_MY20_Gas_Tx" SG_ 990 PersIndexDdm_D_Actl 1;
BA_ "U_C490_MY18_Tx" SG_ 990 PersIndexDdm_D_Actl 1;
BA_ "U_C519_MY18_5_Gas_Tx" SG_ 990 PersIndexDdm_D_Actl 1;
BA_ "U_C519_MY18_5_Diesel_Tx" SG_ 990 PersIndexDdm_D_Actl 1;
BA_ "U_B515_MCA_MY17_Gas_Tx" SG_ 990 PersIndexDdm_D_Actl 1;
BA_ "U_B515_MCA_MY17_Diesel_Tx" SG_ 990 PersIndexDdm_D_Actl 1;
BA_ "U_B479_MY17_Diesel_Tx" SG_ 990 PersIndexDdm_D_Actl 1;
BA_ "U_B479_MY17_Gas_Tx" SG_ 990 PersIndexDdm_D_Actl 1;
BA_ "GenSigSendType" SG_ 990 PersIndexDdm_D_Actl 3;
BA_ "GenSigStartValue" SG_ 990 PersIndexDdm_D_Actl 4;
BA_ "GenSigStartValueInteger" SG_ 990 PersIndexDdm_D_Actl 4;
BA_ "CrossOver_InfoCAN" SG_ 990 PersIndexDdm_D_Actl 1;
BA_ "U_P702_MY2021_Tx" SG_ 990 FeatNoDdm_No_Actl 1;
BA_ "U_CX727_MY2021_Tx" SG_ 990 FeatNoDdm_No_Actl 1;
BA_ "U_CX430_MY2021_Tx" SG_ 990 FeatNoDdm_No_Actl 1;
BA_ "U_U611_U625_MY20_Phev_Tx" SG_ 990 FeatNoDdm_No_Actl 1;
BA_ "U_CX482_CX483_MY20_Tx" SG_ 990 FeatNoDdm_No_Actl 1;
BA_ "U_U611_U625_MY20_Hev_Tx" SG_ 990 FeatNoDdm_No_Actl 1;
BA_ "U_U611_U625_MY20_Gas_Tx" SG_ 990 FeatNoDdm_No_Actl 1;
BA_ "U_C490_MY18_Tx" SG_ 990 FeatNoDdm_No_Actl 1;
BA_ "U_C519_MY18_5_Gas_Tx" SG_ 990 FeatNoDdm_No_Actl 1;
BA_ "U_C519_MY18_5_Diesel_Tx" SG_ 990 FeatNoDdm_No_Actl 1;
BA_ "U_B515_MCA_MY17_Gas_Tx" SG_ 990 FeatNoDdm_No_Actl 1;
BA_ "U_B515_MCA_MY17_Diesel_Tx" SG_ 990 FeatNoDdm_No_Actl 1;
BA_ "U_B479_MY17_Diesel_Tx" SG_ 990 FeatNoDdm_No_Actl 1;
BA_ "U_B479_MY17_Gas_Tx" SG_ 990 FeatNoDdm_No_Actl 1;
BA_ "GenSigSendType" SG_ 990 FeatNoDdm_No_Actl 3;
BA_ "CrossOver_InfoCAN" SG_ 990 FeatNoDdm_No_Actl 1;
BA_ "U_P702_MY2021_Tx" SG_ 990 FeatConfigDdmActl 1;
BA_ "U_CX727_MY2021_Tx" SG_ 990 FeatConfigDdmActl 1;
BA_ "U_CX430_MY2021_Tx" SG_ 990 FeatConfigDdmActl 1;
BA_ "U_U611_U625_MY20_Phev_Tx" SG_ 990 FeatConfigDdmActl 1;
BA_ "U_CX482_CX483_MY20_Tx" SG_ 990 FeatConfigDdmActl 1;
BA_ "U_U611_U625_MY20_Hev_Tx" SG_ 990 FeatConfigDdmActl 1;
BA_ "U_U611_U625_MY20_Gas_Tx" SG_ 990 FeatConfigDdmActl 1;
BA_ "U_C490_MY18_Tx" SG_ 990 FeatConfigDdmActl 1;
BA_ "U_C519_MY18_5_Gas_Tx" SG_ 990 FeatConfigDdmActl 1;
BA_ "U_C519_MY18_5_Diesel_Tx" SG_ 990 FeatConfigDdmActl 1;
BA_ "U_B515_MCA_MY17_Gas_Tx" SG_ 990 FeatConfigDdmActl 1;
BA_ "U_B515_MCA_MY17_Diesel_Tx" SG_ 990 FeatConfigDdmActl 1;
BA_ "U_B479_MY17_Diesel_Tx" SG_ 990 FeatConfigDdmActl 1;
BA_ "U_B479_MY17_Gas_Tx" SG_ 990 FeatConfigDdmActl 1;
BA_ "GenSigSendType" SG_ 990 FeatConfigDdmActl 3;
BA_ "CrossOver_InfoCAN" SG_ 990 FeatConfigDdmActl 1;
BA_ "GenSigSendType" SG_ 1003 PersSetupRestr_D_Actl 3;
BA_ "U_B500_MY18_Diesel_Rx" SG_ 1003 PersSetupRestr_D_Actl 1;
BA_ "U_B500_MY18_Gas_Rx" SG_ 1003 PersSetupRestr_D_Actl 1;
BA_ "U_CX727_MY2021_Rx" SG_ 1003 PersSetupRestr_D_Actl 1;
BA_ "U_CX430_MY2021_Rx" SG_ 1003 PersSetupRestr_D_Actl 1;
BA_ "U_C519_MY18_5_Gas_Rx" SG_ 1003 PersSetupRestr_D_Actl 1;
BA_ "U_C519_MY18_5_Diesel_Rx" SG_ 1003 PersSetupRestr_D_Actl 1;
BA_ "U_B515_MCA_MY17_Gas_Rx" SG_ 1003 PersSetupRestr_D_Actl 1;
BA_ "U_B515_MCA_MY17_Diesel_Rx" SG_ 1003 PersSetupRestr_D_Actl 1;
BA_ "U_B479_MY17_Diesel_Rx" SG_ 1003 PersSetupRestr_D_Actl 1;
BA_ "U_B479_MY17_Gas_Rx" SG_ 1003 PersSetupRestr_D_Actl 1;
BA_ "U_P702_MY2021_Rx" SG_ 1003 PersSetupRestr_D_Actl 1;
BA_ "U_U611_U625_MY20_Phev_Rx" SG_ 1003 PersSetupRestr_D_Actl 1;
BA_ "U_CX482_CX483_MY20_Rx" SG_ 1003 PersSetupRestr_D_Actl 1;
BA_ "U_U611_U625_MY20_Hev_Rx" SG_ 1003 PersSetupRestr_D_Actl 1;
BA_ "U_U611_U625_MY20_Gas_Rx" SG_ 1003 PersSetupRestr_D_Actl 1;
BA_ "CrossOver_InfoCAN" SG_ 1003 PersSetupRestr_D_Actl 1;
BA_ "GenSigSendType" SG_ 1003 PersSetupAccessCtrl 3;
BA_ "U_B500_MY18_Diesel_Rx" SG_ 1003 PersSetupAccessCtrl 1;
BA_ "U_B500_MY18_Gas_Rx" SG_ 1003 PersSetupAccessCtrl 1;
BA_ "U_P702_MY2021_Rx" SG_ 1003 PersSetupAccessCtrl 1;
BA_ "U_CX727_MY2021_Rx" SG_ 1003 PersSetupAccessCtrl 1;
BA_ "U_CX430_MY2021_Rx" SG_ 1003 PersSetupAccessCtrl 1;
BA_ "U_U611_U625_MY20_Phev_Rx" SG_ 1003 PersSetupAccessCtrl 1;
BA_ "U_CX482_CX483_MY20_Rx" SG_ 1003 PersSetupAccessCtrl 1;
BA_ "U_U611_U625_MY20_Hev_Rx" SG_ 1003 PersSetupAccessCtrl 1;
BA_ "U_U611_U625_MY20_Gas_Rx" SG_ 1003 PersSetupAccessCtrl 1;
BA_ "U_C519_MY18_5_Gas_Rx" SG_ 1003 PersSetupAccessCtrl 1;
BA_ "U_C519_MY18_5_Diesel_Rx" SG_ 1003 PersSetupAccessCtrl 1;
BA_ "U_B515_MCA_MY17_Gas_Rx" SG_ 1003 PersSetupAccessCtrl 1;
BA_ "U_B515_MCA_MY17_Diesel_Rx" SG_ 1003 PersSetupAccessCtrl 1;
BA_ "U_B479_MY17_Diesel_Rx" SG_ 1003 PersSetupAccessCtrl 1;
BA_ "U_B479_MY17_Gas_Rx" SG_ 1003 PersSetupAccessCtrl 1;
BA_ "CrossOver_InfoCAN" SG_ 1003 PersSetupAccessCtrl 1;
BA_ "GenSigSendType" SG_ 1003 PersSetup_No_Actl 3;
BA_ "U_B500_MY18_Diesel_Rx" SG_ 1003 PersSetup_No_Actl 1;
BA_ "U_B500_MY18_Gas_Rx" SG_ 1003 PersSetup_No_Actl 1;
BA_ "U_CX727_MY2021_Rx" SG_ 1003 PersSetup_No_Actl 1;
BA_ "U_CX430_MY2021_Rx" SG_ 1003 PersSetup_No_Actl 1;
BA_ "U_C519_MY18_5_Gas_Rx" SG_ 1003 PersSetup_No_Actl 1;
BA_ "U_C519_MY18_5_Diesel_Rx" SG_ 1003 PersSetup_No_Actl 1;
BA_ "U_B515_MCA_MY17_Gas_Rx" SG_ 1003 PersSetup_No_Actl 1;
BA_ "U_B515_MCA_MY17_Diesel_Rx" SG_ 1003 PersSetup_No_Actl 1;
BA_ "U_B479_MY17_Diesel_Rx" SG_ 1003 PersSetup_No_Actl 1;
BA_ "U_B479_MY17_Gas_Rx" SG_ 1003 PersSetup_No_Actl 1;
BA_ "U_P702_MY2021_Rx" SG_ 1003 PersSetup_No_Actl 1;
BA_ "U_U611_U625_MY20_Phev_Rx" SG_ 1003 PersSetup_No_Actl 1;
BA_ "U_CX482_CX483_MY20_Rx" SG_ 1003 PersSetup_No_Actl 1;
BA_ "U_U611_U625_MY20_Hev_Rx" SG_ 1003 PersSetup_No_Actl 1;
BA_ "U_U611_U625_MY20_Gas_Rx" SG_ 1003 PersSetup_No_Actl 1;
BA_ "CrossOver_InfoCAN" SG_ 1003 PersSetup_No_Actl 1;
BA_ "GenSigStartValue" SG_ 1003 PersConflict_D_Actl 1;
BA_ "GenSigStartValueInteger" SG_ 1003 PersConflict_D_Actl 1;
BA_ "CrossOver_InfoCAN" SG_ 1003 PersConflict_D_Actl 1;
BA_ "CrossOver_InfoCAN" SG_ 1003 AssocConfirm_D_Actl 1;
BA_ "GenSigSendType" SG_ 1003 RecallEvent_No_Cnt 3;
BA_ "U_B500_MY18_Diesel_Rx" SG_ 1003 RecallEvent_No_Cnt 1;
BA_ "U_B500_MY18_Gas_Rx" SG_ 1003 RecallEvent_No_Cnt 1;
BA_ "U_C519_MY18_5_Gas_Rx" SG_ 1003 RecallEvent_No_Cnt 1;
BA_ "U_C519_MY18_5_Diesel_Rx" SG_ 1003 RecallEvent_No_Cnt 1;
BA_ "U_B515_MCA_MY17_Gas_Rx" SG_ 1003 RecallEvent_No_Cnt 1;
BA_ "U_B515_MCA_MY17_Diesel_Rx" SG_ 1003 RecallEvent_No_Cnt 1;
BA_ "U_B479_MY17_Diesel_Rx" SG_ 1003 RecallEvent_No_Cnt 1;
BA_ "U_B479_MY17_Gas_Rx" SG_ 1003 RecallEvent_No_Cnt 1;
BA_ "U_P702_MY2021_Rx" SG_ 1003 RecallEvent_No_Cnt 1;
BA_ "U_CX727_MY2021_Rx" SG_ 1003 RecallEvent_No_Cnt 1;
BA_ "U_CX430_MY2021_Rx" SG_ 1003 RecallEvent_No_Cnt 1;
BA_ "U_U611_U625_MY20_Phev_Rx" SG_ 1003 RecallEvent_No_Cnt 1;
BA_ "U_CX482_CX483_MY20_Rx" SG_ 1003 RecallEvent_No_Cnt 1;
BA_ "U_U611_U625_MY20_Hev_Rx" SG_ 1003 RecallEvent_No_Cnt 1;
BA_ "U_U611_U625_MY20_Gas_Rx" SG_ 1003 RecallEvent_No_Cnt 1;
BA_ "MetaData" SG_ 1003 RecallEvent_No_Cnt 1;
BA_ "CrossOver_InfoCAN" SG_ 1003 RecallEvent_No_Cnt 1;
BA_ "GenSigSendType" SG_ 1003 PersNo_D_Actl 3;
BA_ "U_B500_MY18_Diesel_Rx" SG_ 1003 PersNo_D_Actl 1;
BA_ "U_B500_MY18_Gas_Rx" SG_ 1003 PersNo_D_Actl 1;
BA_ "U_B515_MCA_MY17_Gas_Rx" SG_ 1003 PersNo_D_Actl 1;
BA_ "U_B515_MCA_MY17_Diesel_Rx" SG_ 1003 PersNo_D_Actl 1;
BA_ "U_B479_MY17_Diesel_Rx" SG_ 1003 PersNo_D_Actl 1;
BA_ "U_B479_MY17_Gas_Rx" SG_ 1003 PersNo_D_Actl 1;
BA_ "U_CX727_MY2021_Rx" SG_ 1003 PersNo_D_Actl 1;
BA_ "U_CX430_MY2021_Rx" SG_ 1003 PersNo_D_Actl 1;
BA_ "U_C519_MY18_5_Gas_Rx" SG_ 1003 PersNo_D_Actl 1;
BA_ "U_C519_MY18_5_Diesel_Rx" SG_ 1003 PersNo_D_Actl 1;
BA_ "U_P702_MY2021_Rx" SG_ 1003 PersNo_D_Actl 1;
BA_ "U_U611_U625_MY20_Phev_Rx" SG_ 1003 PersNo_D_Actl 1;
BA_ "U_CX482_CX483_MY20_Rx" SG_ 1003 PersNo_D_Actl 1;
BA_ "U_U611_U625_MY20_Hev_Rx" SG_ 1003 PersNo_D_Actl 1;
BA_ "U_U611_U625_MY20_Gas_Rx" SG_ 1003 PersNo_D_Actl 1;
BA_ "GenSigStartValue" SG_ 1003 PersNo_D_Actl 4;
BA_ "GenSigStartValueInteger" SG_ 1003 PersNo_D_Actl 4;
BA_ "CrossOver_InfoCAN" SG_ 1003 PersNo_D_Actl 1;
BA_ "U_P702_MY2021_Rx" SG_ 1003 PersNoPos_D_Actl 1;
BA_ "U_CX727_MY2021_Rx" SG_ 1003 PersNoPos_D_Actl 1;
BA_ "U_CX430_MY2021_Rx" SG_ 1003 PersNoPos_D_Actl 1;
BA_ "U_U611_U625_MY20_Phev_Rx" SG_ 1003 PersNoPos_D_Actl 1;
BA_ "U_CX482_CX483_MY20_Rx" SG_ 1003 PersNoPos_D_Actl 1;
BA_ "U_U611_U625_MY20_Hev_Rx" SG_ 1003 PersNoPos_D_Actl 1;
BA_ "U_U611_U625_MY20_Gas_Rx" SG_ 1003 PersNoPos_D_Actl 1;
BA_ "U_C490_MY18_Rx" SG_ 1003 PersNoPos_D_Actl 1;
BA_ "GenSigStartValue" SG_ 1003 PersNoPos_D_Actl 4;
BA_ "GenSigStartValueInteger" SG_ 1003 PersNoPos_D_Actl 4;
BA_ "CrossOver_InfoCAN" SG_ 1003 PersNoPos_D_Actl 1;
BA_ "U_P702_MY2021_Tx" SG_ 1945 TesterPhysicalResTRM 1;
BA_ "U_CX430_MY2021_Tx" SG_ 1945 TesterPhysicalResTRM 1;
BA_ "U_U611_U625_MY20_Phev_Tx" SG_ 1945 TesterPhysicalResTRM 1;
BA_ "U_CX482_CX483_MY20_Tx" SG_ 1945 TesterPhysicalResTRM 1;
BA_ "U_U611_U625_MY20_Gas_Tx" SG_ 1945 TesterPhysicalResTRM 1;
BA_ "U_C519_MY18_5_Gas_Tx" SG_ 1945 TesterPhysicalResTRM 1;
BA_ "U_C519_MY18_5_Diesel_Tx" SG_ 1945 TesterPhysicalResTRM 1;
BA_ "U_B515_MCA_MY17_Gas_Tx" SG_ 1945 TesterPhysicalResTRM 1;
BA_ "U_B515_MCA_MY17_Diesel_Tx" SG_ 1945 TesterPhysicalResTRM 1;
BA_ "U_B479_MY17_Diesel_Tx" SG_ 1945 TesterPhysicalResTRM 1;
BA_ "U_B479_MY17_Gas_Tx" SG_ 1945 TesterPhysicalResTRM 1;
BA_ "GenSigSendType" SG_ 1945 TesterPhysicalResTRM 3;
BA_ "U_CX482_CX483_MY20_Tx" SG_ 836 FohFalt_D_Stat 1;
BA_ "U_C519_MY18_5_Gas_Tx" SG_ 836 FohFalt_D_Stat 1;
BA_ "U_C519_MY18_5_Diesel_Tx" SG_ 836 FohFalt_D_Stat 1;
BA_ "ContentDependant" SG_ 836 FohFalt_D_Stat 1;
BA_ "U_CX482_CX483_MY20_Tx" SG_ 836 FohEnbl_B_RqDrv 1;
BA_ "U_C519_MY18_5_Gas_Tx" SG_ 836 FohEnbl_B_RqDrv 1;
BA_ "U_C519_MY18_5_Diesel_Tx" SG_ 836 FohEnbl_B_RqDrv 1;
BA_ "ContentDependant" SG_ 836 FohEnbl_B_RqDrv 1;
BA_ "U_CX482_CX483_MY20_Tx" SG_ 836 FohRqRun_B_Rq 1;
BA_ "U_C519_MY18_5_Gas_Tx" SG_ 836 FohRqRun_B_Rq 1;
BA_ "U_C519_MY18_5_Diesel_Tx" SG_ 836 FohRqRun_B_Rq 1;
BA_ "ContentDependant" SG_ 836 FohRqRun_B_Rq 1;
BA_ "U_CX482_CX483_MY20_Tx" SG_ 836 HvacPrecondMode_D_Rq 1;
BA_ "U_C519_MY18_5_Gas_Tx" SG_ 836 HvacPrecondMode_D_Rq 1;
BA_ "U_C519_MY18_5_Diesel_Tx" SG_ 836 HvacPrecondMode_D_Rq 1;
BA_ "U_CX727_MY2021_Rx" SG_ 836 HvacPrecondMode_D_Rq 1;
BA_ "U_CX430_MY2021_Rx" SG_ 836 HvacPrecondMode_D_Rq 1;
BA_ "U_U611_U625_MY20_Phev_Rx" SG_ 836 HvacPrecondMode_D_Rq 1;
BA_ "U_CX482_CX483_MY20_Rx" SG_ 836 HvacPrecondMode_D_Rq 1;
BA_ "U_U611_U625_MY20_Hev_Rx" SG_ 836 HvacPrecondMode_D_Rq 1;
BA_ "U_U611_U625_MY20_Gas_Rx" SG_ 836 HvacPrecondMode_D_Rq 1;
BA_ "U_C519_MY18_5_Gas_Rx" SG_ 836 HvacPrecondMode_D_Rq 1;
BA_ "U_C519_MY18_5_Diesel_Rx" SG_ 836 HvacPrecondMode_D_Rq 1;
BA_ "U_B479_MY17_Gas_Rx" SG_ 836 HvacPrecondMode_D_Rq 1;
BA_ "GenSigSendType" SG_ 836 HvacPrecondMode_D_Rq 3;
BA_ "ContentDependant" SG_ 836 HvacPrecondMode_D_Rq 1;
BA_ "WakeupSignal" SG_ 836 HvacPrecondMode_D_Rq 1;
BA_ "U_CX482_CX483_MY20_Tx" SG_ 836 HvacPrecondBlwr_D_Rq 1;
BA_ "U_C519_MY18_5_Gas_Tx" SG_ 836 HvacPrecondBlwr_D_Rq 1;
BA_ "U_C519_MY18_5_Diesel_Tx" SG_ 836 HvacPrecondBlwr_D_Rq 1;
BA_ "U_CX727_MY2021_Rx" SG_ 836 HvacPrecondBlwr_D_Rq 1;
BA_ "U_CX430_MY2021_Rx" SG_ 836 HvacPrecondBlwr_D_Rq 1;
BA_ "U_U611_U625_MY20_Phev_Rx" SG_ 836 HvacPrecondBlwr_D_Rq 1;
BA_ "U_CX482_CX483_MY20_Rx" SG_ 836 HvacPrecondBlwr_D_Rq 1;
BA_ "U_U611_U625_MY20_Hev_Rx" SG_ 836 HvacPrecondBlwr_D_Rq 1;
BA_ "U_U611_U625_MY20_Gas_Rx" SG_ 836 HvacPrecondBlwr_D_Rq 1;
BA_ "U_C519_MY18_5_Gas_Rx" SG_ 836 HvacPrecondBlwr_D_Rq 1;
BA_ "U_C519_MY18_5_Diesel_Rx" SG_ 836 HvacPrecondBlwr_D_Rq 1;
BA_ "U_B479_MY17_Gas_Rx" SG_ 836 HvacPrecondBlwr_D_Rq 1;
BA_ "GenSigSendType" SG_ 836 HvacPrecondBlwr_D_Rq 3;
BA_ "ContentDependant" SG_ 836 HvacPrecondBlwr_D_Rq 1;
BA_ "WakeupSignal" SG_ 836 HvacPrecondBlwr_D_Rq 1;
BA_ "GenSigSendType" SG_ 836 Foh_D_Stat 3;
BA_ "U_CX482_CX483_MY20_Tx" SG_ 836 Foh_D_Stat 1;
BA_ "U_C519_MY18_5_Gas_Tx" SG_ 836 Foh_D_Stat 1;
BA_ "U_C519_MY18_5_Diesel_Tx" SG_ 836 Foh_D_Stat 1;
BA_ "U_CX727_MY2021_Rx" SG_ 836 Foh_D_Stat 1;
BA_ "U_CX430_MY2021_Rx" SG_ 836 Foh_D_Stat 1;
BA_ "U_CX482_CX483_MY20_Rx" SG_ 836 Foh_D_Stat 1;
BA_ "U_C519_MY18_5_Gas_Rx" SG_ 836 Foh_D_Stat 1;
BA_ "U_C519_MY18_5_Diesel_Rx" SG_ 836 Foh_D_Stat 1;
BA_ "U_B479_MY17_Gas_Rx" SG_ 836 Foh_D_Stat 1;
BA_ "ContentDependant" SG_ 836 Foh_D_Stat 1;
BA_ "WakeupSignal" SG_ 836 Foh_D_Stat 1;
BA_ "U_CX482_CX483_MY20_Tx" SG_ 836 FuelFlw_Vl_ActlFoh 1;
BA_ "U_C519_MY18_5_Gas_Tx" SG_ 836 FuelFlw_Vl_ActlFoh 1;
BA_ "U_C519_MY18_5_Diesel_Tx" SG_ 836 FuelFlw_Vl_ActlFoh 1;
BA_ "ContentDependant" SG_ 836 FuelFlw_Vl_ActlFoh 1;
BA_ "CrossOver_InfoCAN" SG_ 836 FuelFlw_Vl_ActlFoh 1;
BA_ "GenSigSendType" SG_ 836 EngClnt_Te_ActlFoh 3;
BA_ "U_CX482_CX483_MY20_Tx" SG_ 836 EngClnt_Te_ActlFoh 1;
BA_ "U_C519_MY18_5_Gas_Tx" SG_ 836 EngClnt_Te_ActlFoh 1;
BA_ "U_C519_MY18_5_Diesel_Tx" SG_ 836 EngClnt_Te_ActlFoh 1;
BA_ "U_CX727_MY2021_Rx" SG_ 836 EngClnt_Te_ActlFoh 1;
BA_ "U_CX430_MY2021_Rx" SG_ 836 EngClnt_Te_ActlFoh 1;
BA_ "U_CX482_CX483_MY20_Rx" SG_ 836 EngClnt_Te_ActlFoh 1;
BA_ "U_C519_MY18_5_Gas_Rx" SG_ 836 EngClnt_Te_ActlFoh 1;
BA_ "U_C519_MY18_5_Diesel_Rx" SG_ 836 EngClnt_Te_ActlFoh 1;
BA_ "ContentDependant" SG_ 836 EngClnt_Te_ActlFoh 1;
VAL_ 1095 Pers4Phone_D_Stat 7 "SevenPhoneAssociated" 6 "SixPhoneAssociated" 5 "FivePhoneAssociated" 4 "FourPhoneAssociated" 3 "ThreePhoneAssociated" 2 "TwoPhoneAssociated" 1 "OnePhoneAssociated" 0 "NoPhoneAssociated" ;
VAL_ 1095 Pers3Phone_D_Stat 7 "SevenPhoneAssociated" 6 "SixPhoneAssociated" 5 "FivePhoneAssociated" 4 "FourPhoneAssociated" 3 "ThreePhoneAssociated" 2 "TwoPhoneAssociated" 1 "OnePhoneAssociated" 0 "NoPhoneAssociated" ;
VAL_ 1095 Pers2Phone_D_Stat 7 "SevenPhoneAssociated" 6 "SixPhoneAssociated" 5 "FivePhoneAssociated" 4 "FourPhoneAssociated" 3 "ThreePhoneAssociated" 2 "TwoPhoneAssociated" 1 "OnePhoneAssociated" 0 "NoPhoneAssociated" ;
VAL_ 1095 Pers1Phone_D_Stat 7 "SevenPhoneAssociated" 6 "SixPhoneAssociated" 5 "FivePhoneAssociated" 4 "FourPhoneAssociated" 3 "ThreePhoneAssociated" 2 "TwoPhoneAssociated" 1 "OnePhoneAssociated" 0 "NoPhoneAssociated" ;
VAL_ 1095 HeadLghtOn_D_Rq 7 "NotUsed2" 6 "NotUsed1" 5 "DrlBoth" 4 "DrlRight" 3 "DrlLeft" 2 "High" 1 "Low" 0 "Off" ;
VAL_ 1095 PepsKeyActv_D_Stat 15 "NotUsed11" 14 "NotUsed10" 13 "NotUsed9" 12 "NotUsed8" 11 "NotUsed7" 10 "NotUsed6" 9 "NotUsed5" 8 "Key4Active" 7 "NotUsed4" 6 "NotUsed3" 5 "NotUsed2" 4 "Key3Active" 3 "NotUsed1" 2 "Key2Active" 1 "Key1Active" 0 "NoKeyActive" ;
VAL_ 1095 VehLck_D_Dsply 3 "Faulty" 2 "Unlock" 1 "Lock" 0 "Off" ;
VAL_ 948 Tire_Press_ILR_Stat 4 "Alert" 15 "Not_Supported" 3 "Fault" 2 "Low" 1 "Normal" 0 "Unknown" ;
VAL_ 948 Tire_Press_IRR_Stat 4 "Alert" 15 "Not_Supported" 3 "Fault" 2 "Low" 1 "Normal" 0 "Unknown" ;
VAL_ 948 Tire_Press_LR_OLR_Stat 4 "Alert" 15 "Not_Supported" 3 "Fault" 2 "Low" 1 "Normal" 0 "Unknown" ;
VAL_ 948 Tire_Press_RR_ORR_Stat 4 "Alert" 15 "Not_Supported" 3 "Fault" 2 "Low" 1 "Normal" 0 "Unknown" ;
VAL_ 948 Tire_Press_RF_Stat 4 "Alert" 15 "Not_Supported" 3 "Fault" 2 "Low" 1 "Normal" 0 "Unknown" ;
VAL_ 948 Tire_Press_LF_Stat 4 "Alert" 15 "Not_Supported" 3 "Fault" 2 "Low" 1 "Normal" 0 "Unknown" ;
VAL_ 948 Tire_Press_System_Stat 13 "Training_Complete" 12 "Train_InsideLeftRear_tire" 11 "Train_OutsideLeftRear_tire" 10 "Train_LeftRear_tire" 9 "Train_InsideRtRear_tire" 8 "Train_OutsideRtRear_tire" 7 "Train_RightRear_tire" 14 "Tires_not_trained" 6 "Train_RightFront_tire" 5 "Train_LeftFront_tire" 4 "Systm_Activ_Composite_Stat" 3 "Low_Composite_Stat" 2 "Sensr_Fault_Composite_Stat" 1 "Systm_Fault_Composite_Stat" 0 "Unknown_Composite_Stat" ;
VAL_ 948 Tire_Press_Telltale 3 "Not_Used" 2 "Flash" 1 "On" 0 "Off" ;
VAL_ 948 TirePReset_D_Stat 3 "Not_Used" 2 "Nack" 1 "Ack" 0 "Null" ;
VAL_ 840 FohT2Wednesday_T_Rq 1 "Enable" 0 "Disable" ;
VAL_ 840 FohT2Tuesday_T_Rq 1 "Enable" 0 "Disable" ;
VAL_ 840 FohT2Thursday_T_Rq 1 "Enable" 0 "Disable" ;
VAL_ 840 FohT2Sunday_T_Rq 1 "Enable" 0 "Disable" ;
VAL_ 840 FohT2Saturday_T_Rq 1 "Enable" 0 "Disable" ;
VAL_ 840 FohT2Monday_T_Rq 1 "Enable" 0 "Disable" ;
VAL_ 840 FohT2Friday_T_Rq 1 "Enable" 0 "Disable" ;
VAL_ 840 FohT1Wednesday_T_Rq 1 "Enable" 0 "Disable" ;
VAL_ 840 FohT1Tuesday_T_Rq 1 "Enable" 0 "Disable" ;
VAL_ 840 FohT1Thursday_T_Rq 1 "Enable" 0 "Disable" ;
VAL_ 840 FohT1Sunday_T_Rq 1 "Enable" 0 "Disable" ;
VAL_ 840 FohT1Saturday_T_Rq 1 "Enable" 0 "Disable" ;
VAL_ 840 FohT1Monday_T_Rq 1 "Enable" 0 "Disable" ;
VAL_ 840 FohT1Friday_T_Rq 1 "Enable" 0 "Disable" ;
VAL_ 840 FohAddHeater_D_Rq 3 "NotUsed" 2 "On" 1 "Off" 0 "NoModeSelected" ;
VAL_ 945 KeyOffMde_D_Actl 15 "NotUsed_11" 14 "NotUsed_10" 13 "NotUsed_9" 12 "NotUsed_8" 11 "NotUsed_7" 10 "NotUsed_6" 9 "NotUsed_5" 8 "NotUsed_4" 7 "NotUsed_3" 6 "NotUsed_2" 5 "NotUsed_1" 4 "CriticalBattery" 3 "Hibernate" 2 "Transport" 1 "Factory" 0 "Normal" ;
VAL_ 981 PreCondActv_B_Actl_UB 1 "Fresh_data" 0 "Unchanged_data" ;
VAL_ 981 HvacPrecondRecirc_D_Rq_UB 1 "Fresh_data" 0 "Unchanged_data" ;
VAL_ 981 HvacPrecondMode2_D_Rq_UB 1 "Fresh_data" 0 "Unchanged_data" ;
VAL_ 981 HvacPrecondBlwr2_D_Rq_UB 1 "Fresh_data" 0 "Unchanged_data" ;
VAL_ 981 HvacPrecondAC_D_Rq_UB 1 "Fresh_data" 0 "Unchanged_data" ;
VAL_ 981 HvacPrecond_Te_Rq_UB 1 "Fresh_data" 0 "Unchanged_data" ;
VAL_ 981 DrvCondTpRrDefrs_B_Rq_UB 1 "Fresh_data" 0 "Unchanged_data" ;
VAL_ 981 PreCondActv_B_Actl 1 "On" 0 "Off" ;
VAL_ 981 HvacPrecondRecirc_D_Rq 3 "Last_User_Setting" 2 "Auto" 1 "Recirc" 0 "Outside" ;
VAL_ 981 HvacPrecondMode2_D_Rq 15 "NotUsed4" 14 "NotUsed3" 13 "NotUsed2" 12 "NotUsed1" 11 "Last_User_Settings" 10 "Auto" 9 "Max_Defrost" 8 "Windshield_Panel_Floor" 7 "Windshield_Panel" 6 "Windshield" 5 "Windshield_Floor" 4 "Floor" 3 "Panel_Floor" 2 "Panel" 1 "MAX_AC" 0 "Off" ;
VAL_ 981 HvacPrecondBlwr2_D_Rq 15 "NotUsed6" 14 "NotUsed5" 13 "NotUsed4" 12 "NotUsed3" 11 "NotUsed2" 10 "NotUsed1" 9 "Last_User_Setting" 8 "Auto" 7 "Speed7" 6 "Speed6" 5 "Speed5" 4 "Speed4" 3 "Speed3" 2 "Speed2" 1 "Speed1" 0 "Off" ;
VAL_ 981 HvacPrecondAC_D_Rq 3 "Last_User_Setting" 2 "Auto" 1 "On" 0 "Off" ;
VAL_ 981 DrvCondTpRrDefrs_B_Rq 1 "On" 0 "Off" ;
VAL_ 839 FohStop_B_Stat 3 "Unknown" 2 "NotUsed" 1 "Enable" 0 "Disable" ;
VAL_ 839 FohMsgTxt_D_Rq 4 "BatteryNotFullyCharged" 3 "Exceed7DaysFromLastEngRun" 2 "AmbientTemperatureTooHigh" 1 "LowFuel" 0 "NoMessage" ;
VAL_ 839 FohKeyOff_B_Rq 1 "Enable" 0 "Disable" ;
VAL_ 839 FohEnbl_B_Rq 1 "Enable" 0 "Disable" ;
VAL_ 839 FohTAllEnable_B_Stat 3 "Unknown" 2 "NotUsed" 1 "Enable" 0 "Disable" ;
VAL_ 839 FohT2Enable_B_Stat 1 "Enable" 0 "Disable" ;
VAL_ 839 FohT1Enable_B_Stat 1 "Enable" 0 "Disable" ;
VAL_ 839 FohStrtEnable_B_Stat 1 "Enable" 0 "Disable" ;
VAL_ 839 FohContOn_B_Stat 3 "Unknown" 2 "NotUsed" 1 "Enable" 0 "Disable" ;
VAL_ 839 FohStrtDay_T_Stat 7 "Sunday" 6 "Saturday" 5 "Friday" 4 "Thursday" 3 "Wednesday" 2 "Tuesday" 1 "Monday" 0 "NotUsed" ;
VAL_ 839 FohT2Wednesday_T_Stat 1 "Enable" 0 "Disable" ;
VAL_ 839 FohT2Tuesday_T_Stat 1 "Enable" 0 "Disable" ;
VAL_ 839 FohT2Thursday_T_Stat 1 "Enable" 0 "Disable" ;
VAL_ 839 FohT2Sunday_T_Stat 1 "Enable" 0 "Disable" ;
VAL_ 839 FohT2Saturday_T_Stat 1 "Enable" 0 "Disable" ;
VAL_ 839 FohT2Monday_T_Stat 1 "Enable" 0 "Disable" ;
VAL_ 839 FohT2Friday_T_Stat 1 "Enable" 0 "Disable" ;
VAL_ 839 FohT1Wednesday_T_Stat 1 "Enable" 0 "Disable" ;
VAL_ 839 FohT1Tuesday_T_Stat 1 "Enable" 0 "Disable" ;
VAL_ 839 FohT1Thursday_T_Stat 1 "Enable" 0 "Disable" ;
VAL_ 839 FohT1Sunday_T_Stat 1 "Enable" 0 "Disable" ;
VAL_ 839 FohT1Saturday_T_Stat 1 "Enable" 0 "Disable" ;
VAL_ 839 FohT1Monday_T_Stat 1 "Enable" 0 "Disable" ;
VAL_ 839 FohT1Friday_T_Stat 1 "Enable" 0 "Disable" ;
VAL_ 850 SeatCshnPsgrRR_Pc_Actl 127 "Null" ;
VAL_ 850 SeatCshnPsgrRL_Pc_Actl 127 "Null" ;
VAL_ 850 SeatCshnPsgrFR_Pc_Actl 127 "Null" ;
VAL_ 850 SeatCshnPsgrFL_Pc_Actl 127 "Null" ;
VAL_ 850 SeatBlLoPsgr_Pc_Actl2 127 "Null" ;
VAL_ 849 SeatCshnDrvRR_Pc_Actl 127 "Null" ;
VAL_ 849 SeatCshnDrvRL_Pc_Actl 127 "Null" ;
VAL_ 849 SeatCshnDrvFR_Pc_Actl 127 "Null" ;
VAL_ 849 SeatCshnDrvFL_Pc_Actl 127 "Null" ;
VAL_ 846 SeatMasgDrv_D_Rq 15 "NotUsed_10" 14 "NotUsed_9" 13 "NotUsed_8" 12 "NotUsed_7" 11 "NotUsed_6" 10 "NotUsed_5" 9 "NotUsed_4" 8 "NotUsed_3" 7 "NotUsed_2" 6 "NotUsed_1" 5 "Pattern5" 4 "Pattern4" 3 "Pattern3" 2 "Pattern2" 1 "Pattern1" 0 "Null" ;
VAL_ 846 SeatMasgPsngr_D_Rq 15 "NotUsed_10" 14 "NotUsed_9" 13 "NotUsed_8" 12 "NotUsed_7" 11 "NotUsed_6" 10 "NotUsed_5" 9 "NotUsed_4" 8 "NotUsed_3" 7 "NotUsed_2" 6 "NotUsed_1" 5 "Pattern5" 4 "Pattern4" 3 "Pattern3" 2 "Pattern2" 1 "Pattern1" 0 "Null" ;
VAL_ 846 SeatLmbr_D_Rq 15 "NotUsed_7" 14 "NotUsed_6" 13 "NotUsed_5" 12 "NotUsed_4" 11 "NotUsed_3" 10 "NotUsed_2" 9 "NotUsed_1" 8 "PassengerDown" 7 "PassengerUp" 6 "PassengerAft" 5 "PassengerFore" 4 "DriverDown" 3 "DriverUp" 2 "DriverAft" 1 "DriverFore" 0 "Null" ;
VAL_ 846 SeatFnChngPsgr2_D_Rq 15 "Faulty" 14 "NotUsed9" 13 "NotUsed8" 12 "NotUsed7" 11 "NotUsed6" 10 "High_2" 9 "Med_2" 8 "Low_2" 7 "Off_2" 6 "High" 5 "Low" 4 "Off" 3 "Decrease" 2 "Increase" 1 "NotUsed1" 0 "Inactive" ;
VAL_ 846 SeatFnChngDrv2_D_Rq 15 "Faulty" 14 "NotUsed9" 13 "NotUsed8" 12 "NotUsed7" 11 "NotUsed6" 10 "High_2" 9 "Med_2" 8 "Low_2" 7 "Off_2" 6 "High" 5 "Low" 4 "Off" 3 "Decrease" 2 "Increase" 1 "NotUsed1" 0 "Inactive" ;
VAL_ 845 StmsLmbrPsgr_D_Stat 3 "High" 2 "Low" 1 "Off" 0 "Null" ;
VAL_ 845 StmsCshnPsgr_D_Stat 3 "High" 2 "Low" 1 "Off" 0 "Null" ;
VAL_ 845 SeatSwtchPsgr_B_Stat 1 "On" 0 "Off" ;
VAL_ 845 SeatPPsgr_B_Stat 1 "Updating" 0 "NotUpdating" ;
VAL_ 845 SeatFnPsgr_D_Stat 7 "CushionMassage" 6 "LumbarMassage" 5 "UpperBolster" 4 "LowerBolster" 3 "UpperLumbar" 2 "MiddleLumbar" 1 "LowerLumbar" 0 "Null" ;
VAL_ 845 PsgrMemFeedback_Rsp 8 "Recall_4" 7 "Recall_3" 6 "Recall_2" 5 "Recall_1" 4 "Store_4" 3 "Store_3" 2 "Store_2" 1 "Store_1" 0 "Inactive" ;
VAL_ 844 StmsLmbrDrv_D_Stat 3 "High" 2 "Low" 1 "Off" 0 "Null" ;
VAL_ 844 StmsCshnDrv_D_Stat 3 "High" 2 "Low" 1 "Off" 0 "Null" ;
VAL_ 844 SeatSwtchDrv_B_Stat 1 "On" 0 "Off" ;
VAL_ 844 SeatFnDrv_D_Stat 7 "CushionMassage" 6 "LumbarMassage" 5 "UpperBolster" 4 "LowerBolster" 3 "UpperLumbar" 2 "MiddleLumbar" 1 "LowerLumbar" 0 "Null" ;
VAL_ 844 SeatPDrv_B_Stat 1 "Updating" 0 "NotUpdating" ;
VAL_ 843 SeatBlUpPsgr_Pc_Actl 127 "Null" ;
VAL_ 843 SeatBlLoPsgr_Pc_Actl 127 "Null" ;
VAL_ 842 SeatBlUpDrv_Pc_Actl 127 "Null" ;
VAL_ 842 SeatBlLoDrv_Pc_Actl 127 "Null" ;
VAL_ 958 ElCmprOverTe_D_Stat 3 "OverTempStop" 2 "OverTempWarning" 1 "Normal" 0 "Undefined" ;
VAL_ 958 ElCmprOverTe_D_Stat_UB 1 "Fresh_data" 0 "Unchanged_data" ;
VAL_ 958 EngOff_T_Actl 65535 "Invalid" ;
VAL_ 958 EngOff_T_Actl_UB 1 "Fresh_data" 0 "Unchanged_data" ;
VAL_ 958 StopStrtDrvMde_D_Indic_UB 1 "Fresh_data" 0 "Unchanged_data" ;
VAL_ 958 PrmtrAlrmEvnt_D_Stat 15 "Diag_Tamper" 14 "Trailer" 13 "Shock_Sensor" 12 "Post_Crash" 11 "Panic" 10 "Intrusion" 9 "Inclination" 8 "Ign_Tamper" 7 "LG_Door" 6 "Decklid" 5 "Hood" 4 "PR_Door" 3 "PF_Door" 2 "DR_Door" 1 "DF_Door" 0 "Null" ;
VAL_ 958 PrmtrAlrmEvnt_D_Stat_UB 1 "Fresh_data" 0 "Unchanged_data" ;
VAL_ 958 StopStrtDrvMde_D_Indic 3 "NotUsed" 2 "StartStop_IndirectDeselect" 1 "StopStart_Deselected" 0 "StopStart_Selected" ;
VAL_ 958 FuelLvl_Pc_Dsply_UB 1 "Fresh_data" 0 "Unchanged_data" ;
VAL_ 958 OdometerMasterValue_UB 1 "Fresh_data" 0 "Unchanged_data" ;
VAL_ 958 OdometerMasterValue 16777215 "Invalid" ;
VAL_ 827 SteClmnSwtchTlt_D_Stat 3 "Unused" 2 "Down" 1 "Up" 0 "Null" ;
VAL_ 827 SteClmnSwtchTel_D_Stat 3 "Unused" 2 "Rearward" 1 "Forward" 0 "Null" ;
VAL_ 827 LghtAmbIntns_D_Sns 3 "Faulty" 2 "High" 1 "Low" 0 "Null" ;
VAL_ 902 Remote_Start_Req 3 "Not_Used" 2 "Remote_Cancel" 1 "Remote_Start" 0 "No_Request" ;
VAL_ 902 PrmtrAlrmWarn_B_Rq 1 "Active" 0 "Null" ;
VAL_ 902 PrmtrAlrmTrg_B_Rq 1 "Active" 0 "Null" ;
VAL_ 902 Panic_D_RqRsm 3 "NotUsed" 2 "On" 1 "Off" 0 "Null" ;
VAL_ 902 CellLock_D_RqRsm 7 "NotUsed3" 6 "NotUsed2" 5 "NotUsed1" 4 "TrunkRelPopGlassLgCargo" 3 "LockAllDoorsandTailgate" 2 "UnlockDriversDoor" 1 "UnlockAllDoorsandTailgate" 0 "NoRequest" ;
VAL_ 765 ValetMode_D_Stat_UB 1 "Fresh_data" 0 "Unchanged_data" ;
VAL_ 765 ValetMode_D_Stat 3 "NotUsed" 2 "On" 1 "Off" 0 "Null" ;
VAL_ 765 CcStat_D_Actl_UB 1 "Fresh_data" 0 "Unchanged_data" ;
VAL_ 765 CcStat_D_Actl 7 "Undefined_2" 6 "Undefined_1" 5 "Active" 4 "Active_Que_Assist" 3 "Standby" 2 "Standby_Denied" 1 "Denied" 0 "Off" ;
VAL_ 765 PrplTqMnSat_B_Actl_UB 1 "Fresh_data" 0 "Unchanged_data" ;
VAL_ 765 PrplTqMnSat_B_Actl 1 "Yes" 0 "No" ;
VAL_ 765 ClimtBlwrLim_B_Rq_UB 1 "Fresh_data" 0 "Unchanged_data" ;
VAL_ 765 ClimtBlwrLim_B_Rq 1 "Request" 0 "NoRequest" ;
VAL_ 765 TrlrBrkActCnnct_B_Actl_UB 1 "Fresh_data" 0 "Unchanged_data" ;
VAL_ 765 TrlrBrkActCnnct_B_Actl 1 "Yes" 0 "No" ;
VAL_ 765 EmPrflButtnAssoc_D_Rq 3 "NotUsed" 2 "ExitButtonAssociation" 1 "EnterButtonAssociation" 0 "Null" ;
VAL_ 765 EmPrflButtnAssoc_D_Rq_UB 1 "Fresh_data" 0 "Unchanged_data" ;
VAL_ 765 CamraFrntStat_D_Stat_UB 1 "Fresh_data" 0 "Unchanged_data" ;
VAL_ 765 CamraFrntStat_D_Stat 3 "No_Data_Present" 2 "NotUsed" 1 "On" 0 "Off" ;
VAL_ 765 AutoHoldSwMde_B_Ind_UB 1 "Fresh_data" 0 "Unchanged_data" ;
VAL_ 765 AutoHoldSwMde_B_Ind 1 "On" 0 "Off" ;
VAL_ 765 SteWhlHeat_D_Stat 15 "NotUsed6" 14 "NotUsed5" 13 "NotUsed4" 12 "NotUsed3" 11 "NotUsed2" 10 "NotUsed1" 9 "Reserved_3" 8 "Reserved_2" 7 "Reserved_1" 6 "Level_3_Heating" 5 "Level_3_Heating_LS" 4 "Level_2_Heating" 3 "Level_2_Heating_LS" 2 "Level_1_Heating" 1 "Level_1_Heating_LS" 0 "Off" ;
VAL_ 765 Running_Board_Cmd_UB 1 "Fresh_data" 0 "Unchanged_data" ;
VAL_ 765 Running_Board_Cmd 3 "Unused" 2 "Manually_Deployed" 1 "All_Enabled" 0 "All_Disabled" ;
VAL_ 765 Bezel_Beeps_Rq_UB 1 "Fresh_data" 0 "Unchanged_data" ;
VAL_ 765 Bezel_Beeps_Rq 0 "Inactive" 2 "Disable" 1 "Enable" ;
VAL_ 765 Diagnostic_Operation_Rq_UB 1 "Fresh_data" 0 "Unchanged_data" ;
VAL_ 765 Bezel_Diag_State_Rq_UB 1 "Fresh_data" 0 "Unchanged_data" ;
VAL_ 765 Bezel_Diag_Module_Rq_UB 1 "Fresh_data" 0 "Unchanged_data" ;
VAL_ 765 Diagnostic_Operation_Rq 7 "SignalStrength" 6 "SDARSESNNumber" 5 "SpeakerWalkAround" 4 "CalibrationPartNumber" 15 "Reserved" 3 "HardwarePartNumber" 2 "SoftwarePartNumber" 1 "GetAllBackgroundDiagRq" 0 "Inactive" ;
VAL_ 765 Bezel_Diag_State_Rq 1 "Active" 0 "Inactive" ;
VAL_ 765 Bezel_Diag_Module_Rq 15 "Reserved" 3 "EFP" 2 "DSP_AMP" 1 "AHU" 0 "Inactive" ;
VAL_ 765 HMI_HMIMode_St_UB 1 "Fresh_data" 0 "Unchanged_data" ;
VAL_ 765 HMI_HMIMode_St 7 "NotUsed2" 6 "NotUsed1" 5 "Load_Shed_Active" 0 "Invalid" 1 "OffMode" 2 "On" 3 "Phone" 4 "Climate" ;
VAL_ 765 Mc_VehUnitTempUsrSel_St_UB 1 "Fresh_data" 0 "Unchanged_data" ;
VAL_ 765 Mc_VehUnitTempUsrSel_St 0 "Temperature_deg_c" 1 "Temperature_deg_f" ;
VAL_ 765 PsngrFrntDetct_D_Actl_UB 1 "Fresh_data" 0 "Unchanged_data" ;
VAL_ 765 PsngrFrntDetct_D_Actl 3 "Unknown" 2 "Empty" 0 "Faulty" 1 "Occupied" ;
VAL_ 765 SteWhlHeat_D_Stat_UB 1 "Fresh_data" 0 "Unchanged_data" ;
VAL_ 765 PrkAidLamp_D_Rq_UB 1 "Fresh_data" 0 "Unchanged_data" ;
VAL_ 765 ParkDetect_Stat_UB 1 "Fresh_data" 0 "Unchanged_data" ;
VAL_ 765 ParkDetect_Stat 1 "Park" 0 "Not_Park" ;
VAL_ 765 Voice_Blower_Limit_UB 1 "Fresh_data" 0 "Unchanged_data" ;
VAL_ 765 Voice_Blower_Limit 1 "Request" 0 "NoRequest" ;
VAL_ 765 PwStep_D_DrvInhbt_UB 1 "Fresh_data" 0 "Unchanged_data" ;
VAL_ 765 PwStep_D_DrvInhbt 3 "NotUsed" 2 "DriveInhibitMalfunction" 1 "DriveInhibited" 0 "DriveNotInhibited" ;
VAL_ 874 FrtTe_An_Actl 511 "Faulty" ;
VAL_ 874 FrtBlwr_An_Actl 511 "Faulty" ;
VAL_ 874 E_Voice_Blower_Limit 1 "Request" 0 "NoRequest" ;
VAL_ 874 E_Rr_Btn_Status_2nd 31 "NotUsed15" 30 "NotUsed14" 29 "NotUsed13" 28 "NotUsed12" 27 "NotUsed11" 26 "NotUsed10" 25 "NotUsed9" 24 "Third_Synch_Pressed" 23 "Third_Rr_Pwr_Pressed" 22 "Third_Auto_Pressed" 21 "Third_Pnl_Flr_Pressed" 20 "Third_Floor_Pressed" 19 "Third_Panel_Pressed" 18 "Third_Blwr_Dec_Pressed" 17 "Third_Blwr_Inc_Pressed" 16 "Rear_Lock_Pressed" 15 "RHS_Cld_Seat_Pressed" 14 "LHS_Cld_Seat_Pressed" 13 "RHS_Htd_Seat_Pressed" 12 "LHS_Htd_Seat_Pressed" 11 "Rear_Power_Pressed" 10 "AUTO_Pressed" 9 "Blwr_Dec_Pressed" 8 "Blwr_Inc_Pressed" 7 "RHS_Temp_Dec_Pressed" 6 "RHS_Temp_Inc_Pressed" 5 "LHS_Temp_Dec_Pressed" 4 "LHS_Temp_Inc_Pressed" 3 "Floor_Pressed" 2 "Panel_Floor_Pressed" 1 "Panel_Pressed" 0 "None_Pressed" ;
VAL_ 874 E_Rr_Btn_Status_1st 31 "NotUsed15" 30 "NotUsed14" 29 "NotUsed13" 28 "NotUsed12" 27 "NotUsed11" 26 "NotUsed10" 25 "NotUsed9" 24 "Third_Synch_Pressed" 23 "Third_Rr_Pwr_Pressed" 22 "Third_Auto_Pressed" 21 "Third_Pnl_Flr_Pressed" 20 "Third_Floor_Pressed" 19 "Third_Panel_Pressed" 18 "Third_Blwr_Dec_Pressed" 17 "Third_Blwr_Inc_Pressed" 16 "Rear_Lock_Pressed" 15 "RHS_Cld_Seat_Pressed" 14 "LHS_Cld_Seat_Pressed" 13 "RHS_Htd_Seat_Pressed" 12 "LHS_Htd_Seat_Pressed" 11 "Rear_Power_Pressed" 10 "AUTO_Pressed" 9 "Blwr_Dec_Pressed" 8 "Blwr_Inc_Pressed" 7 "RHS_Temp_Dec_Pressed" 6 "RHS_Temp_Inc_Pressed" 5 "LHS_Temp_Dec_Pressed" 4 "LHS_Temp_Inc_Pressed" 3 "Floor_Pressed" 2 "Panel_Floor_Pressed" 1 "Panel_Pressed" 0 "None_Pressed" ;
VAL_ 874 E_Frt_Btn_Status_2nd 36 "MdeMnu_Pressed" 35 "AAR_Pressed" 34 "Heat_Pressed" 33 "RearMnu_Pressed" 32 "FrontMnu_Pressed" 31 "Defrost_Pressed" 30 "Htg_Strg_Whl_Pressed" 29 "RHS_Cld_Seat_Pressed" 28 "LHS_Cld_Seat_Pressed" 27 "RHS_Htd_Seat_Pressed" 26 "LHS_Htd_Seat_Pressed" 25 "Max_Defrost_Pressed" 24 "My_Temp_Pressed" 23 "Front_Power_Pressed" 22 "Rear_Defrost_Pressed" 21 "Pnl_Flr_Ws_Pressed" 20 "Pnl_Ws_Pressed" 19 "Windscreen_Pressed" 18 "Htd_Frt_Wsh_Pressed" 17 "Auto_Recirc_Pressed" 16 "Outside_Pressed" 15 "Recirc_Pressed" 14 "Max_AC_Pressed" 13 "AUTO_Pressed" 12 "Blwr_Dec_Pressed" 11 "Blwr_Inc_Pressed" 10 "RHS_Temp_Dec_Pressed" 9 "RHS_Temp_Inc_Pressed" 8 "LHS_Temp_Dec_Pressed" 7 "LHS_Temp_Inc_Pressed" 6 "Dual_Pressed" 5 "AC_Pressed" 4 "Floor_Ws_Pressed" 3 "Floor_Pressed" 2 "Panel_Floor_Pressed" 1 "Panel_Pressed" 0 "None_Pressed" ;
VAL_ 874 E_Frt_Btn_Status_1st 36 "MdeMnu_Pressed" 35 "AAR_Pressed" 34 "Heat_Pressed" 33 "RearMnu_Pressed" 32 "FrontMnu_Pressed" 31 "Defrost_Pressed" 30 "Htg_Strg_Whl_Pressed" 29 "RHS_Cld_Seat_Pressed" 28 "LHS_Cld_Seat_Pressed" 27 "RHS_Htd_Seat_Pressed" 26 "LHS_Htd_Seat_Pressed" 25 "Max_Defrost_Pressed" 24 "My_Temp_Pressed" 23 "Front_Power_Pressed" 22 "Rear_Defrost_Pressed" 21 "Pnl_Flr_Ws_Pressed" 20 "Pnl_Ws_Pressed" 19 "Windscreen_Pressed" 18 "Htd_Frt_Wsh_Pressed" 17 "Auto_Recirc_Pressed" 16 "Outside_Pressed" 15 "Recirc_Pressed" 14 "Max_AC_Pressed" 13 "AUTO_Pressed" 12 "Blwr_Dec_Pressed" 11 "Blwr_Inc_Pressed" 10 "RHS_Temp_Dec_Pressed" 9 "RHS_Temp_Inc_Pressed" 8 "LHS_Temp_Dec_Pressed" 7 "LHS_Temp_Inc_Pressed" 6 "Dual_Pressed" 5 "AC_Pressed" 4 "Floor_Ws_Pressed" 3 "Floor_Pressed" 2 "Panel_Floor_Pressed" 1 "Panel_Pressed" 0 "None_Pressed" ;
VAL_ 874 E_Frt_Blwr_Speed 3 "NotUsed" 2 "Max_Blower" 1 "Min_Blower" 0 "No_Request" ;
VAL_ 874 E_Drv_Set_Temp 31 "HI" 30 "29_5" 29 "29_0" 28 "28_5" 27 "28_0" 26 "27_5" 25 "27_0" 24 "26_5" 23 "26_0" 22 "25_5" 21 "25_0" 20 "24_5" 19 "24_0" 18 "23_5" 17 "23_0" 16 "22_5" 15 "22_0" 14 "21_5" 13 "21_0" 12 "20_5" 11 "20_0" 10 "19_5" 9 "19_0" 8 "18_5" 7 "18_0" 6 "17_5" 5 "17_0" 4 "16_5" 3 "16_0" 2 "15_5" 1 "LO" 0 "No_Request" ;
VAL_ 359 PrplWhlRgenMn_Tq_Actl 8191 "Faulty" ;
VAL_ 359 ElPw_D_StatStrtStop 15 "NotUsed6" 14 "NotUsed5" 13 "NotUsed4" 12 "NotUsed3" 11 "NotUsed2" 10 "NotUsed1" 9 "Supported_Level_4" 8 "Supported_Level_3" 7 "Supported_Level_2" 6 "Supported_Level_1" 5 "Limited_Support" 4 "Fault_Limited" 3 "LV_Event_in_Progress" 2 "Not_Supported_Imminent" 1 "Supported_All" 0 "Not_Supported" ;
VAL_ 359 PrplWhlTot2_Tq_Actl 65535 "Fault" 65534 "NoDataExists" ;
VAL_ 359 LscmbbDeny_B_ActlPrpl 1 "Denied" 0 "Allowed" ;
VAL_ 359 LscmbbEngTqMn_B_Actl 1 "Engine_Braking_Activated" 0 "Engine_Braking_Off" ;
VAL_ 359 TrnAinTq_D_Qf 3 "OK" 2 "Not_Within_Specifications" 1 "No_Data_Exists" 0 "Faulty" ;
VAL_ 359 PwPckTq_D_Stat 3 "PwPckOn_TqAvailable" 2 "StartInPrgrss_TqNotAvail" 1 "PwPckOn_TqNotAvailable" 0 "PwPckOff_TqNotAvailable" ;
VAL_ 359 Eng_D_Stat 3 "NotUsed" 2 "EngAutoStopped" 1 "EngOn" 0 "EngOff" ;
VAL_ 359 PlgActvArb_B_Actl 1 "On" 0 "Off" ;
VAL_ 359 ElPw_D_Stat 7 "NotUsed_3" 6 "NotUsed_2" 5 "NotUsed_1" 4 "Fault_Limited" 3 "LV_Event_In_Progress" 2 "Not_Supported_Imminent" 1 "Supported" 0 "Not_Supported" ;
VAL_ 131 StePinCompAnEst_D_Qf 3 "OK" 2 "Degraded" 1 "No_Data_Exists" 0 "Faulty" ;
VAL_ 131 StePinComp_An_Est_UB 1 "Fresh_data" 0 "Unchanged_data" ;
VAL_ 131 VehLongComp_A_Actl_UB 1 "Fresh_data" 0 "Unchanged_data" ;
VAL_ 131 VehLatComp_A_Actl_UB 1 "Fresh_data" 0 "Unchanged_data" ;
VAL_ 131 VehLongComp_A_Actl 1023 "Fault" 1022 "NoDataExists" ;
VAL_ 131 VehLatComp_A_Actl 1023 "Fault" 1022 "NoDataExists" ;
VAL_ 131 VehYaw_W_Actl_UB 1 "Fresh_data" 0 "Unchanged_data" ;
VAL_ 131 VehYaw_W_Actl 65535 "Faulty" 65534 "NoDataExists" ;
VAL_ 990 PersIndexDdm_D_Actl 7 "Unused_3" 6 "Unused_2" 5 "Unused_1" 4 "Vehicle" 3 "PERS_4" 2 "PERS_3" 1 "PERS_2" 0 "PERS_1" ;
VAL_ 1003 Pers4Key_D_Stat 3 "NotUsed_1" 2 "KeyUnAssociated" 1 "KeyAssociated" 0 "Null" ;
VAL_ 1003 Pers3Key_D_Stat 3 "NotUsed_1" 2 "KeyUnAssociated" 1 "KeyAssociated" 0 "Null" ;
VAL_ 1003 Pers2Key_D_Stat 3 "NotUsed_1" 2 "KeyUnAssociated" 1 "KeyAssociated" 0 "Null" ;
VAL_ 1003 Pers1Key_D_Stat 3 "NotUsed_1" 2 "KeyUnAssociated" 1 "KeyAssociated" 0 "Null" ;
VAL_ 1003 EmPrflNo_D_Stat 7 "NotUsed_3" 6 "NotUsed_2" 5 "NotUsed_1" 4 "Pers4" 3 "Pers3" 2 "Pers2" 1 "Pers1" 0 "Null" ;
VAL_ 1003 EmPrflKeyAssoc_D_Stat 7 "WrongDevice" 6 "KeyAssociateFailed" 5 "KeyAssociateSuccess" 4 "KeyAlreadyInUse" 3 "KeyDisassociated" 2 "KeyAssociationExited" 1 "KeyAssociationEntered" 0 "Null" ;
VAL_ 1003 PersSetupRestr_D_Actl 3 "Non_Moveable_Person" 2 "Moveable_Person" 1 "Vehicle" 0 "Factory" ;
VAL_ 1003 PersSetupAccessCtrl 1 "Limited" 0 "Full" ;
VAL_ 1003 PersConflict_D_Actl 1 "Conflict" 0 "No_Conflict" ;
VAL_ 1003 AssocConfirm_D_Actl 0 "None" 7 "Associate" 6 "Keycode_Rejected" 5 "Keycode_Accepted" 4 "In_Progress" 3 "Erase" 2 "Duplicate" 1 "Disassociate" ;
VAL_ 1003 PersNo_D_Actl 7 "Unused_3" 6 "Unused_2" 5 "NotDetermined" 4 "Vehicle" 3 "PERS_4" 2 "PERS_3" 1 "PERS_2" 0 "PERS_1" ;
VAL_ 1003 PersNoPos_D_Actl 7 "Unused_3" 6 "Unused_2" 5 "Unused_1" 4 "Vehicle" 3 "PERS_4" 2 "PERS_3" 1 "PERS_2" 0 "PERS_1" ;
VAL_ 836 FohFalt_D_Stat 15 "NotUsed4" 14 "NotUsed3" 13 "NotUsed2" 12 "NotUsed1" 11 "FuelTypeDoesNotMatchFOH" 10 "Lifecycle_ModeNotSet" 9 "AuxElectricCoolantPumpInop" 8 "TimeDelayAvoidExcessCycl" 7 "Fuel_Level_OutofRange" 6 "External_Fault" 5 "Internal_Fault" 4 "Voltage_limitation" 3 "Impact_Event" 2 "CoolantTemp_OutofRange" 1 "AmbientTemp_OutofRange" 0 "No_Disable" ;
VAL_ 836 FohEnbl_B_RqDrv 1 "On" 0 "Off" ;
VAL_ 836 FohRqRun_B_Rq 1 "SubmitRequest_toRun" 0 "DoesNotSubmitRequest_toRun" ;
VAL_ 836 HvacPrecondMode_D_Rq 15 "NotUsed4" 14 "NotUsed3" 13 "NotUsed2" 12 "NotUsed1" 11 "Last_User_Settings" 10 "Auto" 9 "Max_Defrost" 8 "Windshield_Panel_Floor" 7 "Windshield_Panel" 6 "Windshield" 5 "Windshield_Floor" 4 "Floor" 3 "Panel_Floor" 2 "Panel" 1 "MAX_AC" 0 "Off" ;
VAL_ 836 HvacPrecondBlwr_D_Rq 15 "NotUsed6" 14 "NotUsed5" 13 "NotUsed4" 12 "NotUsed3" 11 "NotUsed2" 10 "NotUsed1" 9 "Last_User_Setting" 8 "Auto" 7 "Speed7" 6 "Speed6" 5 "Speed5" 4 "Speed4" 3 "Speed3" 2 "Speed2" 1 "Speed1" 0 "Off" ;
VAL_ 836 Foh_D_Stat 7 "Unused3" 6 "Unused2" 5 "Unused1" 4 "Stopping" 3 "Running" 2 "Starting" 1 "Prestart" 0 "Off" ;
VAL_ 836 EngClnt_Te_ActlFoh 255 "Fault" ;
